VERSION ""

NS_ :

BS_:

BU_:

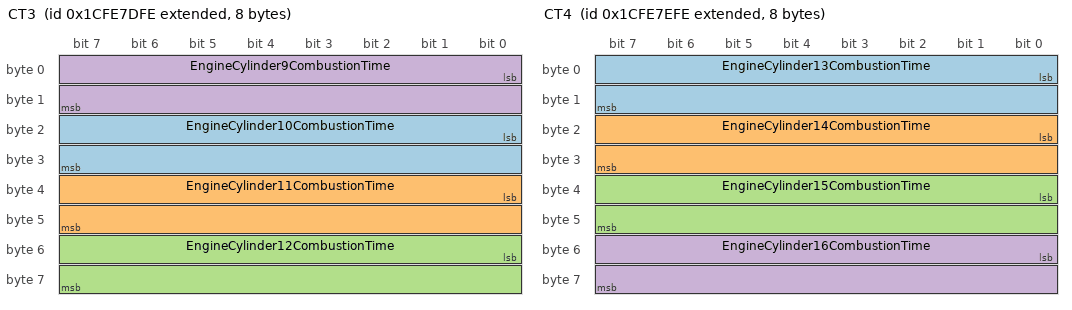
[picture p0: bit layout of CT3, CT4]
BO_ 2633924094 CT3: 8 Vector__XXX
 SG_ EngineCylinder10CombustionTime : 16|16@1+ (0.01,0) [0|642.55] "ms" Vector__XXX
 SG_ EngineCylinder11CombustionTime : 32|16@1+ (0.01,0) [0|642.55] "ms" Vector__XXX
 SG_ EngineCylinder12CombustionTime : 48|16@1+ (0.01,0) [0|642.55] "ms" Vector__XXX
 SG_ EngineCylinder9CombustionTime : 0|16@1+ (0.01,0) [0|642.55] "ms" Vector__XXX

BO_ 2633924350 CT4: 8 Vector__XXX
 SG_ EngineCylinder13CombustionTime : 0|16@1+ (0.01,0) [0|642.55] "ms" Vector__XXX
 SG_ EngineCylinder14CombustionTime : 16|16@1+ (0.01,0) [0|642.55] "ms" Vector__XXX
 SG_ EngineCylinder15CombustionTime : 32|16@1+ (0.01,0) [0|642.55] "ms" Vector__XXX
 SG_ EngineCylinder16CombustionTime : 48|16@1+ (0.01,0) [0|642.55] "ms" Vector__XXX

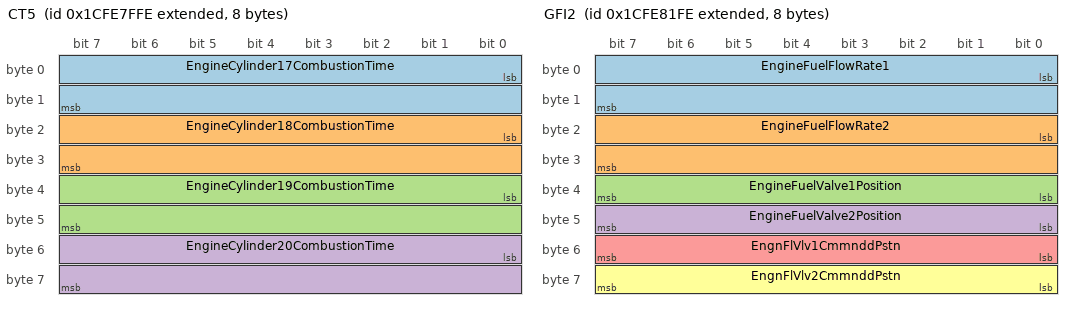
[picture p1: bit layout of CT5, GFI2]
BO_ 2633924606 CT5: 8 Vector__XXX
 SG_ EngineCylinder17CombustionTime : 0|16@1+ (0.01,0) [0|642.55] "ms" Vector__XXX
 SG_ EngineCylinder18CombustionTime : 16|16@1+ (0.01,0) [0|642.55] "ms" Vector__XXX
 SG_ EngineCylinder19CombustionTime : 32|16@1+ (0.01,0) [0|642.55] "ms" Vector__XXX
 SG_ EngineCylinder20CombustionTime : 48|16@1+ (0.01,0) [0|642.55] "ms" Vector__XXX

BO_ 2633924862 CT6: 8 Vector__XXX
 SG_ EngineAverageCombustionTime : 16|16@1+ (0.01,0) [0|642.55] "ms" Vector__XXX
 SG_ EngineDesiredCombustionTime : 0|16@1+ (0.01,0) [0|642.55] "ms" Vector__XXX

BO_ 2633925118 GFI2: 8 Vector__XXX
 SG_ EngineFuelFlowRate1 : 0|16@1+ (0.1,0) [0|6425.5] "(m*m*m)/h" Vector__XXX
 SG_ EngineFuelFlowRate2 : 16|16@1+ (0.1,0) [0|6425.5] "(m*m*m)/h" Vector__XXX
 SG_ EngineFuelValve1Position : 32|8@1+ (0.4,0) [0|100] "%" Vector__XXX
 SG_ EngineFuelValve2Position : 40|8@1+ (0.4,0) [0|100] "%" Vector__XXX
 SG_ EngnFlVlv1CmmnddPstn : 48|8@1+ (0.4,0) [0|100] "%" Vector__XXX
 SG_ EngnFlVlv2CmmnddPstn : 56|8@1+ (0.4,0) [0|100] "%" Vector__XXX

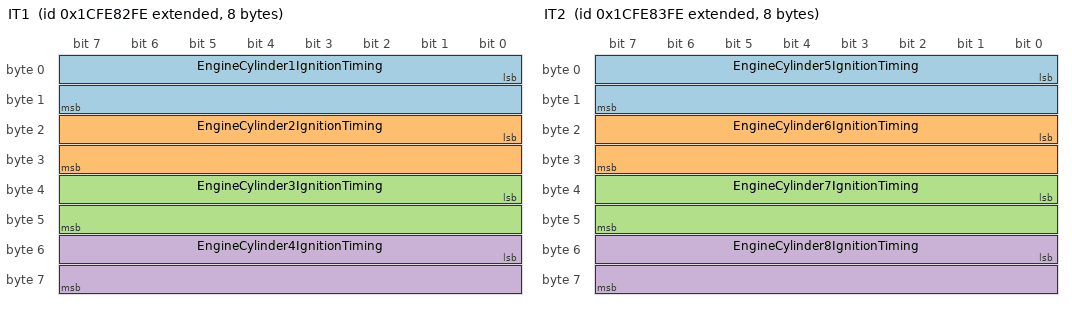
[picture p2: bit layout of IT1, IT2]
BO_ 2633925374 IT1: 8 Vector__XXX
 SG_ EngineCylinder1IgnitionTiming : 0|16@1+ (0.0078125,-200) [-200|301.9921875] "deg" Vector__XXX
 SG_ EngineCylinder2IgnitionTiming : 16|16@1+ (0.0078125,-200) [-200|301.9921875] "deg" Vector__XXX
 SG_ EngineCylinder3IgnitionTiming : 32|16@1+ (0.0078125,-200) [-200|301.9921875] "deg" Vector__XXX
 SG_ EngineCylinder4IgnitionTiming : 48|16@1+ (0.0078125,-200) [-200|301.9921875] "deg" Vector__XXX

BO_ 2633925630 IT2: 8 Vector__XXX
 SG_ EngineCylinder5IgnitionTiming : 0|16@1+ (0.0078125,-200) [-200|301.9921875] "deg" Vector__XXX
 SG_ EngineCylinder6IgnitionTiming : 16|16@1+ (0.0078125,-200) [-200|301.9921875] "deg" Vector__XXX
 SG_ EngineCylinder7IgnitionTiming : 32|16@1+ (0.0078125,-200) [-200|301.9921875] "deg" Vector__XXX
 SG_ EngineCylinder8IgnitionTiming : 48|16@1+ (0.0078125,-200) [-200|301.9921875] "deg" Vector__XXX

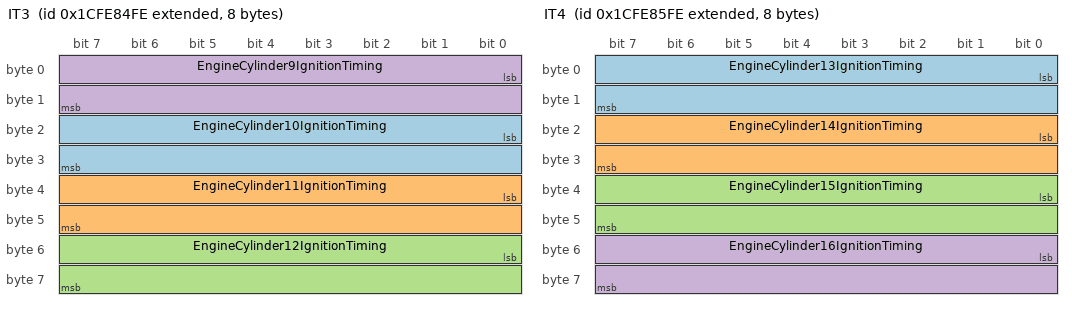
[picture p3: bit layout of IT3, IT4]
BO_ 2633925886 IT3: 8 Vector__XXX
 SG_ EngineCylinder10IgnitionTiming : 16|16@1+ (0.0078125,-200) [-200|301.9921875] "deg" Vector__XXX
 SG_ EngineCylinder11IgnitionTiming : 32|16@1+ (0.0078125,-200) [-200|301.9921875] "deg" Vector__XXX
 SG_ EngineCylinder12IgnitionTiming : 48|16@1+ (0.0078125,-200) [-200|301.9921875] "deg" Vector__XXX
 SG_ EngineCylinder9IgnitionTiming : 0|16@1+ (0.0078125,-200) [-200|301.9921875] "deg" Vector__XXX

BO_ 2633926142 IT4: 8 Vector__XXX
 SG_ EngineCylinder13IgnitionTiming : 0|16@1+ (0.0078125,-200) [-200|301.9921875] "deg" Vector__XXX
 SG_ EngineCylinder14IgnitionTiming : 16|16@1+ (0.0078125,-200) [-200|301.9921875] "deg" Vector__XXX
 SG_ EngineCylinder15IgnitionTiming : 32|16@1+ (0.0078125,-200) [-200|301.9921875] "deg" Vector__XXX
 SG_ EngineCylinder16IgnitionTiming : 48|16@1+ (0.0078125,-200) [-200|301.9921875] "deg" Vector__XXX

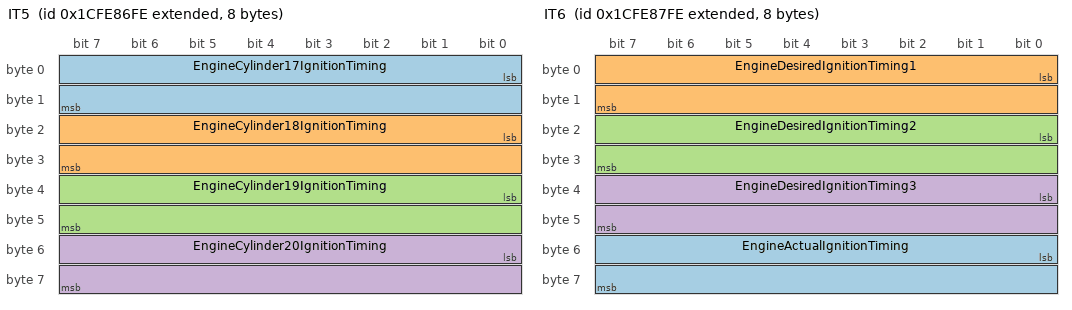
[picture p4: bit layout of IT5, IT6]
BO_ 2633926398 IT5: 8 Vector__XXX
 SG_ EngineCylinder17IgnitionTiming : 0|16@1+ (0.0078125,-200) [-200|301.9921875] "deg" Vector__XXX
 SG_ EngineCylinder18IgnitionTiming : 16|16@1+ (0.0078125,-200) [-200|301.9921875] "deg" Vector__XXX
 SG_ EngineCylinder19IgnitionTiming : 32|16@1+ (0.0078125,-200) [-200|301.9921875] "deg" Vector__XXX
 SG_ EngineCylinder20IgnitionTiming : 48|16@1+ (0.0078125,-200) [-200|301.9921875] "deg" Vector__XXX

BO_ 2633926654 IT6: 8 Vector__XXX
 SG_ EngineActualIgnitionTiming : 48|16@1+ (0.0078125,-200) [-200|301.9921875] "deg" Vector__XXX
 SG_ EngineDesiredIgnitionTiming1 : 0|16@1+ (0.0078125,-200) [-200|301.9921875] "deg" Vector__XXX
 SG_ EngineDesiredIgnitionTiming2 : 16|16@1+ (0.0078125,-200) [-200|301.9921875] "deg" Vector__XXX
 SG_ EngineDesiredIgnitionTiming3 : 32|16@1+ (0.0078125,-200) [-200|301.9921875] "deg" Vector__XXX

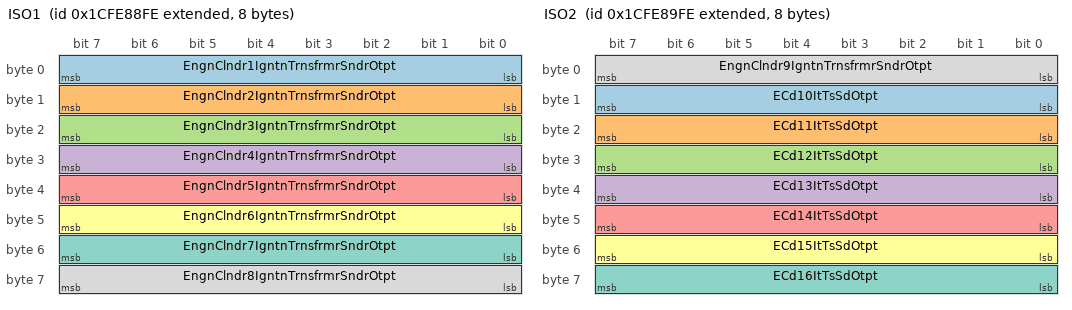
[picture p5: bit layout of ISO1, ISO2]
BO_ 2633926910 ISO1: 8 Vector__XXX
 SG_ EngnClndr1IgntnTrnsfrmrSndrOtpt : 0|8@1+ (1,-125) [-125|125] "%" Vector__XXX
 SG_ EngnClndr2IgntnTrnsfrmrSndrOtpt : 8|8@1+ (1,-125) [-125|125] "%" Vector__XXX
 SG_ EngnClndr3IgntnTrnsfrmrSndrOtpt : 16|8@1+ (1,-125) [-125|125] "%" Vector__XXX
 SG_ EngnClndr4IgntnTrnsfrmrSndrOtpt : 24|8@1+ (1,-125) [-125|125] "%" Vector__XXX
 SG_ EngnClndr5IgntnTrnsfrmrSndrOtpt : 32|8@1+ (1,-125) [-125|125] "%" Vector__XXX
 SG_ EngnClndr6IgntnTrnsfrmrSndrOtpt : 40|8@1+ (1,-125) [-125|125] "%" Vector__XXX
 SG_ EngnClndr7IgntnTrnsfrmrSndrOtpt : 48|8@1+ (1,-125) [-125|125] "%" Vector__XXX
 SG_ EngnClndr8IgntnTrnsfrmrSndrOtpt : 56|8@1+ (1,-125) [-125|125] "%" Vector__XXX

BO_ 2633927166 ISO2: 8 Vector__XXX
 SG_ ECd10ItTsSdOtpt : 8|8@1+ (1,-125) [-125|125] "%" Vector__XXX
 SG_ ECd11ItTsSdOtpt : 16|8@1+ (1,-125) [-125|125] "%" Vector__XXX
 SG_ ECd12ItTsSdOtpt : 24|8@1+ (1,-125) [-125|125] "%" Vector__XXX
 SG_ ECd13ItTsSdOtpt : 32|8@1+ (1,-125) [-125|125] "%" Vector__XXX
 SG_ ECd14ItTsSdOtpt : 40|8@1+ (1,-125) [-125|125] "%" Vector__XXX
 SG_ ECd15ItTsSdOtpt : 48|8@1+ (1,-125) [-125|125] "%" Vector__XXX
 SG_ ECd16ItTsSdOtpt : 56|8@1+ (1,-125) [-125|125] "%" Vector__XXX
 SG_ EngnClndr9IgntnTrnsfrmrSndrOtpt : 0|8@1+ (1,-125) [-125|125] "%" Vector__XXX

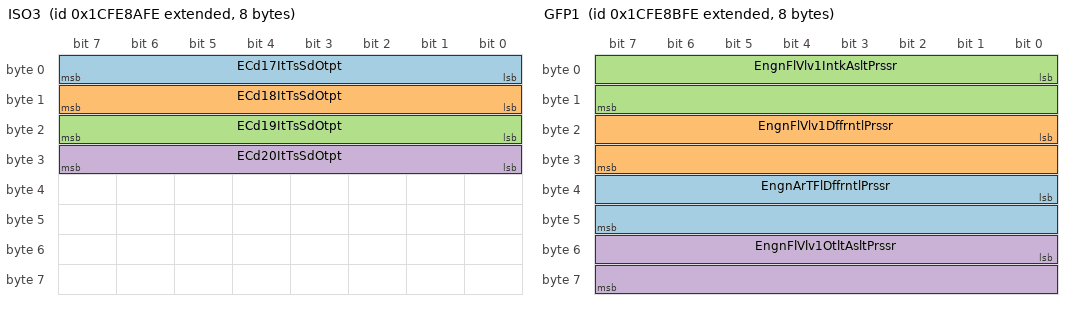
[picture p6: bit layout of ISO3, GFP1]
BO_ 2633927422 ISO3: 8 Vector__XXX
 SG_ ECd17ItTsSdOtpt : 0|8@1+ (1,-125) [-125|125] "%" Vector__XXX
 SG_ ECd18ItTsSdOtpt : 8|8@1+ (1,-125) [-125|125] "%" Vector__XXX
 SG_ ECd19ItTsSdOtpt : 16|8@1+ (1,-125) [-125|125] "%" Vector__XXX
 SG_ ECd20ItTsSdOtpt : 24|8@1+ (1,-125) [-125|125] "%" Vector__XXX

BO_ 2633927678 GFP1: 8 Vector__XXX
 SG_ EngnArTFlDffrntlPrssr : 32|16@1+ (0.1,0) [0|6425.5] "kPa" Vector__XXX
 SG_ EngnFlVlv1DffrntlPrssr : 16|16@1+ (0.1,0) [0|6425.5] "kPa" Vector__XXX
 SG_ EngnFlVlv1IntkAsltPrssr : 0|16@1+ (0.1,0) [0|6425.5] "kPa" Vector__XXX
 SG_ EngnFlVlv1OtltAsltPrssr : 48|16@1+ (0.1,0) [0|6425.5] "kPa" Vector__XXX

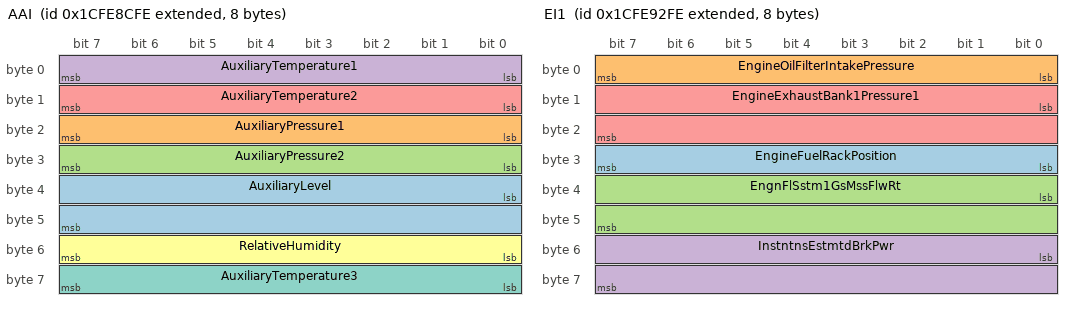
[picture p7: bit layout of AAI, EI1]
BO_ 2633927934 AAI: 8 Vector__XXX
 SG_ AuxiliaryLevel : 32|16@1+ (0.1,0) [0|6425.5] "mm" Vector__XXX
 SG_ AuxiliaryPressure1 : 16|8@1+ (16,0) [0|4000] "kPa" Vector__XXX
 SG_ AuxiliaryPressure2 : 24|8@1+ (16,0) [0|4000] "kPa" Vector__XXX
 SG_ AuxiliaryTemperature1 : 0|8@1+ (1,-40) [-40|210] "degC" Vector__XXX
 SG_ AuxiliaryTemperature2 : 8|8@1+ (1,-40) [-40|210] "degC" Vector__XXX
 SG_ RelativeHumidity : 48|8@1+ (0.4,0) [0|100] "%" Vector__XXX
 SG_ AuxiliaryTemperature3 : 56|8@1+ (1,-40) [-40|210] "degC" Vector__XXX

BO_ 2633928446 S2: 8 Vector__XXX
 SG_ ServiceComponentIdentification : 0|8@1+ (1,0) [0|250] "ID" Vector__XXX
 SG_ TimeSinceLastService : 8|16@1+ (1,-32127) [-32127|32128] "h" Vector__XXX

BO_ 2633929214 FL: 8 Vector__XXX
 SG_ EngineFluidBundLevel : 8|8@1+ (0.4,0) [0|100] "%" Vector__XXX
 SG_ EngineFuelLeakage1 : 0|2@1+ (1,0) [0|3] "" Vector__XXX
 SG_ EngineFuelLeakage2 : 2|2@1+ (1,0) [0|3] "" Vector__XXX

BO_ 2633929470 EI1: 8 Vector__XXX
 SG_ EngineFuelRackPosition : 24|8@1+ (0.4,0) [0|100] "%" Vector__XXX
 SG_ EngineOilFilterIntakePressure : 0|8@1+ (4,0) [0|1000] "kPa" Vector__XXX
 SG_ EngnFlSstm1GsMssFlwRt : 32|16@1+ (0.05,0) [0|3212.75] "kg/h" Vector__XXX
 SG_ InstntnsEstmtdBrkPwr : 48|16@1+ (0.5,0) [0|32127.5] "kW" Vector__XXX
 SG_ EngineExhaustBank1Pressure1 : 8|16@1+ (0.0078125,-250) [-250|251.9921875] "kPa" Vector__XXX

BO_ 2633929726 EES: 8 Vector__XXX
 SG_ ElectricalLoad : 0|16@1+ (0.5,0) [0|32127.5] "kW" Vector__XXX
 SG_ EngineTurningGearEngaged : 18|2@1+ (1,0) [0|3] "" Vector__XXX
 SG_ SafetyWireStatus : 16|2@1+ (1,0) [0|3] "" Vector__XXX

BO_ 2633930238 RBI: 8 Vector__XXX
 SG_ EngineOperationTimeSinceRebuild : 0|32@1+ (1,0) [0|4211081215] "s" Vector__XXX

BO_ 2633931774 TCI1: 8 Vector__XXX
 SG_ EngineTurbocharger2Speed : 8|16@1+ (4,0) [0|257020] "rpm" Vector__XXX
 SG_ EngineTurbocharger3Speed : 24|16@1+ (4,0) [0|257020] "rpm" Vector__XXX
 SG_ EngineTurbocharger4Speed : 40|16@1+ (4,0) [0|257020] "rpm" Vector__XXX
 SG_ EngnTrhrgrLOlPrssr2 : 0|8@1+ (4,0) [0|1000] "kPa" Vector__XXX

BO_ 2633932798 EPT5: 8 Vector__XXX
 SG_ EngnExhstGsPrt17Tmprtr : 0|16@1+ (0.03125,-273) [-273|1734.96875] "degC" Vector__XXX
 SG_ EngnExhstGsPrt18Tmprtr : 16|16@1+ (0.03125,-273) [-273|1734.96875] "degC" Vector__XXX
 SG_ EngnExhstGsPrt19Tmprtr : 32|16@1+ (0.03125,-273) [-273|1734.96875] "degC" Vector__XXX
 SG_ EngnExhstGsPrt20Tmprtr : 48|16@1+ (0.03125,-273) [-273|1734.96875] "degC" Vector__XXX

BO_ 2633933310 EPT3: 8 Vector__XXX
 SG_ EngnExhstGsPrt10Tmprtr : 16|16@1+ (0.03125,-273) [-273|1734.96875] "degC" Vector__XXX
 SG_ EngnExhstGsPrt11Tmprtr : 32|16@1+ (0.03125,-273) [-273|1734.96875] "degC" Vector__XXX
 SG_ EngnExhstGsPrt12Tmprtr : 48|16@1+ (0.03125,-273) [-273|1734.96875] "degC" Vector__XXX
 SG_ EngnExhstGsPrt9Tmprtr : 0|16@1+ (0.03125,-273) [-273|1734.96875] "degC" Vector__XXX

BO_ 2633933566 EPT2: 8 Vector__XXX
 SG_ EngnExhstGsPrt5Tmprtr : 0|16@1+ (0.03125,-273) [-273|1734.96875] "degC" Vector__XXX
 SG_ EngnExhstGsPrt6Tmprtr : 16|16@1+ (0.03125,-273) [-273|1734.96875] "degC" Vector__XXX
 SG_ EngnExhstGsPrt7Tmprtr : 32|16@1+ (0.03125,-273) [-273|1734.96875] "degC" Vector__XXX
 SG_ EngnExhstGsPrt8Tmprtr : 48|16@1+ (0.03125,-273) [-273|1734.96875] "degC" Vector__XXX

BO_ 2633933822 EPT1: 8 Vector__XXX
 SG_ EngnExhstGsPrt1Tmprtr : 0|16@1+ (0.03125,-273) [-273|1734.96875] "degC" Vector__XXX
 SG_ EngnExhstGsPrt2Tmprtr : 16|16@1+ (0.03125,-273) [-273|1734.96875] "degC" Vector__XXX
 SG_ EngnExhstGsPrt3Tmprtr : 32|16@1+ (0.03125,-273) [-273|1734.96875] "degC" Vector__XXX
 SG_ EngnExhstGsPrt4Tmprtr : 48|16@1+ (0.03125,-273) [-273|1734.96875] "degC" Vector__XXX

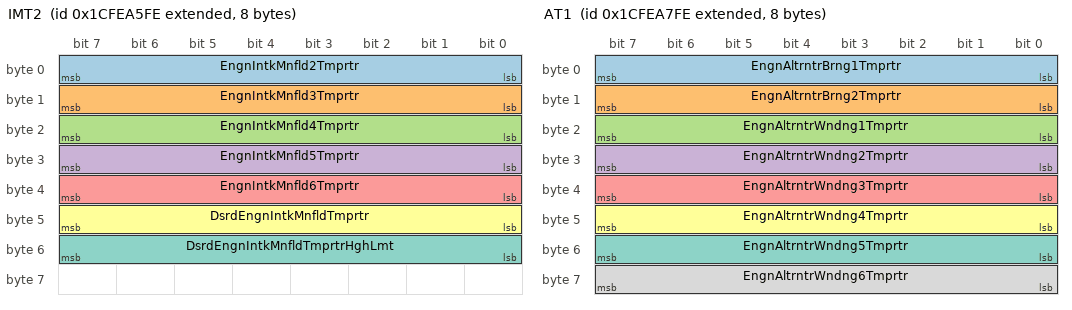
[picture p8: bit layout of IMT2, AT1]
BO_ 2633934334 IMT2: 8 Vector__XXX
 SG_ EngnIntkMnfld2Tmprtr : 0|8@1+ (1,-40) [-40|210] "degC" Vector__XXX
 SG_ EngnIntkMnfld3Tmprtr : 8|8@1+ (1,-40) [-40|210] "degC" Vector__XXX
 SG_ EngnIntkMnfld4Tmprtr : 16|8@1+ (1,-40) [-40|210] "degC" Vector__XXX
 SG_ EngnIntkMnfld5Tmprtr : 24|8@1+ (1,-40) [-40|210] "degC" Vector__XXX
 SG_ EngnIntkMnfld6Tmprtr : 32|8@1+ (1,-40) [-40|210] "degC" Vector__XXX
 SG_ DsrdEngnIntkMnfldTmprtr : 40|8@1+ (1,-40) [-40|210] "degC" Vector__XXX
 SG_ DsrdEngnIntkMnfldTmprtrHghLmt : 48|8@1+ (1,-40) [-40|210] "degC" Vector__XXX

BO_ 2633934846 AT1: 8 Vector__XXX
 SG_ EngnAltrntrBrng1Tmprtr : 0|8@1+ (1,-40) [-40|210] "degC" Vector__XXX
 SG_ EngnAltrntrBrng2Tmprtr : 8|8@1+ (1,-40) [-40|210] "degC" Vector__XXX
 SG_ EngnAltrntrWndng1Tmprtr : 16|8@1+ (1,-40) [-40|210] "degC" Vector__XXX
 SG_ EngnAltrntrWndng2Tmprtr : 24|8@1+ (1,-40) [-40|210] "degC" Vector__XXX
 SG_ EngnAltrntrWndng3Tmprtr : 32|8@1+ (1,-40) [-40|210] "degC" Vector__XXX
 SG_ EngnAltrntrWndng4Tmprtr : 40|8@1+ (1,-40) [-40|210] "degC" Vector__XXX
 SG_ EngnAltrntrWndng5Tmprtr : 48|8@1+ (1,-40) [-40|210] "degC" Vector__XXX
 SG_ EngnAltrntrWndng6Tmprtr : 56|8@1+ (1,-40) [-40|210] "degC" Vector__XXX

BO_ 2633935102 ACTL: 8 Vector__XXX
 SG_ ArticulationAngle : 0|8@1+ (1,-125) [-125|125] "deg" Vector__XXX
 SG_ ArticulationAngularVelocity : 8|16@1+ (0.0078125,-250) [-250|251.9921875] "deg/s" Vector__XXX

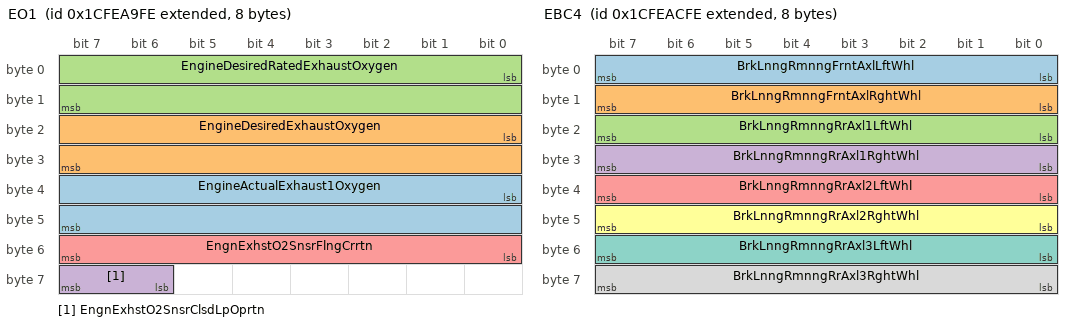
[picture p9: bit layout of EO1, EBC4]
BO_ 2633935358 EO1: 8 Vector__XXX
 SG_ EngineActualExhaust1Oxygen : 32|16@1+ (0.0025,0) [0|160.6375] "%" Vector__XXX
 SG_ EngineDesiredExhaustOxygen : 16|16@1+ (0.0025,0) [0|160.6375] "%" Vector__XXX
 SG_ EngineDesiredRatedExhaustOxygen : 0|16@1+ (0.0025,0) [0|160.6375] "%" Vector__XXX
 SG_ EngnExhstO2SnsrClsdLpOprtn : 62|2@1+ (1,0) [0|3] "" Vector__XXX
 SG_ EngnExhstO2SnsrFlngCrrtn : 48|8@1+ (1,-125) [-125|125] "%" Vector__XXX

BO_ 2633935614 AF2: 8 Vector__XXX
 SG_ EFSstGsMssFwRtSsFCt : 32|8@1+ (1,-125) [-125|125] "%" Vector__XXX
 SG_ EngnIntkMnfldDsrdAsltPrssr : 8|16@1+ (0.1,0) [0|6425.5] "kPa" Vector__XXX
 SG_ EngnTrhrgrWstgtVlvPstn : 24|8@1+ (0.4,0) [0|100] "%" Vector__XXX
 SG_ GaseousFuelCorrectionFactor : 0|8@1+ (1,0) [0|250] "%" Vector__XXX
 SG_ GssFlInjtnPlsCrrtnFtr : 40|16@1+ (0.0078125,-251) [0|150] "%" Vector__XXX

BO_ 2633935870 ETC6: 8 Vector__XXX
 SG_ ClutchLifeRemaining : 24|8@1+ (0.4,0) [0|100] "%" Vector__XXX
 SG_ HighestPossibleGear : 8|8@1+ (1,-125) [-125|125] "gear value" Vector__XXX
 SG_ LowestPossibleGear : 16|8@1+ (1,-125) [-125|125] "gear value" Vector__XXX
 SG_ RecommendedGear : 0|8@1+ (1,-125) [-125|125] "gear value" Vector__XXX

BO_ 2633936126 EBC4: 8 Vector__XXX
 SG_ BrkLnngRmnngFrntAxlLftWhl : 0|8@1+ (0.4,0) [0|100] "%" Vector__XXX
 SG_ BrkLnngRmnngFrntAxlRghtWhl : 8|8@1+ (0.4,0) [0|100] "%" Vector__XXX
 SG_ BrkLnngRmnngRrAxl1LftWhl : 16|8@1+ (0.4,0) [0|100] "%" Vector__XXX
 SG_ BrkLnngRmnngRrAxl1RghtWhl : 24|8@1+ (0.4,0) [0|100] "%" Vector__XXX
 SG_ BrkLnngRmnngRrAxl2LftWhl : 32|8@1+ (0.4,0) [0|100] "%" Vector__XXX
 SG_ BrkLnngRmnngRrAxl2RghtWhl : 40|8@1+ (0.4,0) [0|100] "%" Vector__XXX
 SG_ BrkLnngRmnngRrAxl3LftWhl : 48|8@1+ (0.4,0) [0|100] "%" Vector__XXX
 SG_ BrkLnngRmnngRrAxl3RghtWhl : 56|8@1+ (0.4,0) [0|100] "%" Vector__XXX

BO_ 2633936894 GFC: 8 Vector__XXX
 SG_ TotalFuelUsedGaseous : 32|32@1+ (0.5,0) [0|2105540607.5] "kg" Vector__XXX
 SG_ TripFuelGaseous : 0|32@1+ (0.5,0) [0|2105540607.5] "kg" Vector__XXX

BO_ 2633937150 TTI2: 20 Vector__XXX
 SG_ TripAirCompressorOnTime : 128|32@1+ (0.05,0) [0|210554060.75] "h" Vector__XXX
 SG_ TripCruiseTime : 0|32@1+ (0.05,0) [0|210554060.75] "h" Vector__XXX
 SG_ TripEngineRunningTime : 64|32@1+ (0.05,0) [0|210554060.75] "h" Vector__XXX
 SG_ TripIdleTime : 96|32@1+ (0.05,0) [0|210554060.75] "h" Vector__XXX
 SG_ TripPtoGovernorTime : 32|32@1+ (0.05,0) [0|210554060.75] "h" Vector__XXX

BO_ 2633937406 EH: 8 Vector__XXX
 SG_ TotalEcuDistance : 0|32@1+ (0.125,0) [0|526385151.875] "km" Vector__XXX
 SG_ TotalEcuRunTime : 32|32@1+ (0.05,0) [0|210554060.75] "h" Vector__XXX

BO_ 2633937662 GFI1: 8 Vector__XXX
 SG_ EngineFuelSpecificGravity : 48|16@1+ (0.0001,0) [0|2] "" Vector__XXX
 SG_ TripAverageFuelRateGaseous : 32|16@1+ (0.05,0) [0|3212.75] "kg/h" Vector__XXX
 SG_ TtlEngnPtGvrnrFlUsdGss : 0|32@1+ (0.5,0) [0|2105540607.5] "kg" Vector__XXX

BO_ 2633937918 LFI1: 8 Vector__XXX
 SG_ FlexibleFuelPercentage : 48|16@1+ (0.0025,0) [0|100] "%" Vector__XXX
 SG_ TotalEnginePtoGovernorFuelUsed : 0|32@1+ (0.5,0) [0|2105540607.5] "l" Vector__XXX
 SG_ TripAverageFuelRate : 32|16@1+ (0.05,0) [0|3212.75] "l/h" Vector__XXX

BO_ 2633938174 TTI1: 16 Vector__XXX
 SG_ TripTimeInDerateByEngine : 96|32@1+ (0.05,0) [0|210554060.75] "h" Vector__XXX
 SG_ TripTimeInGearDown : 64|32@1+ (0.05,0) [0|210554060.75] "h" Vector__XXX
 SG_ TripTimeInTopGear : 32|32@1+ (0.05,0) [0|210554060.75] "h" Vector__XXX
 SG_ TripTimeInVsl : 0|32@1+ (0.05,0) [0|210554060.75] "h" Vector__XXX

BO_ 2633938430 TSI: 8 Vector__XXX
 SG_ TripNumberOfHotShutdowns : 0|16@1+ (1,0) [0|64255] "count" Vector__XXX
 SG_ TripNumberOfIdleShutdowns : 16|16@1+ (1,0) [0|64255] "count" Vector__XXX
 SG_ TripSuddenDecelerations : 48|16@1+ (1,0) [0|64255] "count" Vector__XXX
 SG_ TrpNmrOfIdlShtdwnOvrrds : 32|16@1+ (1,0) [0|64255] "count" Vector__XXX

BO_ 2633938686 TVI: 8 Vector__XXX
 SG_ TripCruiseDistance : 16|32@1+ (0.125,0) [0|526385151.875] "km" Vector__XXX
 SG_ TripMaximumVehicleSpeed : 0|16@1+ (0.00390625,0) [0|250.99609375] "km/h" Vector__XXX

BO_ 2633938942 LF1: 10 Vector__XXX
 SG_ TotalEngineCruiseTime : 48|32@1+ (0.05,0) [0|210554060.75] "h" Vector__XXX
 SG_ TripAverageEngineSpeed : 16|16@1+ (0.125,0) [0|8031.875] "rpm" Vector__XXX
 SG_ TripMaximumEngineSpeed : 0|16@1+ (0.125,0) [0|8031.875] "rpm" Vector__XXX
 SG_ TripDriveAverageLoadFactor : 32|8@1+ (0.4,0) [0|100] "%" Vector__XXX
 SG_ TotalDriveAverageLoadFactor : 40|8@1+ (0.4,0) [0|100] "%" Vector__XXX

BO_ 2633939198 GTFI: 22 Vector__XXX
 SG_ TripCruiseFuelUsedGaseous : 128|32@1+ (0.5,0) [0|2105540607.5] "kg" Vector__XXX
 SG_ TripDriveFuelEconomyGaseous : 160|16@1+ (0.001953125,0) [0|125.498046875] "km/kg" Vector__XXX
 SG_ TripDriveFuelUsedGaseous : 0|32@1+ (0.5,0) [0|2105540607.5] "kg" Vector__XXX
 SG_ TripVehicleIdleFuelUsedGaseous : 96|32@1+ (0.5,0) [0|2105540607.5] "kg" Vector__XXX
 SG_ TrpPtGvrnrMvngFlUsdGss : 32|32@1+ (0.5,0) [0|2105540607.5] "kg" Vector__XXX
 SG_ TrpPtGvrnrNnMvngFlUsdGss : 64|32@1+ (0.5,0) [0|2105540607.5] "kg" Vector__XXX

BO_ 2633939454 LTFI: 22 Vector__XXX
 SG_ TripCruiseFuelUsed : 128|32@1+ (0.5,0) [0|2105540607.5] "l" Vector__XXX
 SG_ TripDriveFuelEconomy : 160|16@1+ (0.001953125,0) [0|125.498046875] "km/L" Vector__XXX
 SG_ TripDriveFuelUsed : 0|32@1+ (0.5,0) [0|2105540607.5] "l" Vector__XXX
 SG_ TripPtoGovernorMovingFuelUsed : 32|32@1+ (0.5,0) [0|2105540607.5] "l" Vector__XXX
 SG_ TripVehicleIdleFuelUsed : 96|32@1+ (0.5,0) [0|2105540607.5] "l" Vector__XXX
 SG_ TrpPtGvrnrNnMvngFlUsd : 64|32@1+ (0.5,0) [0|2105540607.5] "l" Vector__XXX

BO_ 2633939710 TDI: 12 Vector__XXX
 SG_ TripDistanceInTopGear : 64|32@1+ (0.125,0) [0|526385151.875] "km" Vector__XXX
 SG_ TripDistanceOnVsl : 0|32@1+ (0.125,0) [0|526385151.875] "km" Vector__XXX
 SG_ TripGearDownDistance : 32|32@1+ (0.125,0) [0|526385151.875] "km" Vector__XXX

BO_ 2633939966 TFI: 16 Vector__XXX
 SG_ TripFanOnTime : 0|32@1+ (0.05,0) [0|210554060.75] "h" Vector__XXX
 SG_ TripFanOnTimeDueToAManualSwitch : 64|32@1+ (0.05,0) [0|210554060.75] "h" Vector__XXX
 SG_ TripFanOnTimeDueToTheACSystem : 96|32@1+ (0.05,0) [0|210554060.75] "h" Vector__XXX
 SG_ TrpFnOnTmDTThEngnSstm : 32|32@1+ (0.05,0) [0|210554060.75] "h" Vector__XXX

BO_ 2633940222 CBI: 16 Vector__XXX
 SG_ TotalCompressionBrakeDistance : 0|32@1+ (0.125,0) [0|526385151.875] "km" Vector__XXX
 SG_ TripCompressionBrakeDistance : 32|32@1+ (0.125,0) [0|526385151.875] "km" Vector__XXX
 SG_ TripServiceBrakeApplications : 96|32@1+ (1,0) [0|4211081215] "brake appl" Vector__XXX
 SG_ TripServiceBrakeDistance : 64|32@1+ (0.125,0) [0|526385151.875] "km" Vector__XXX

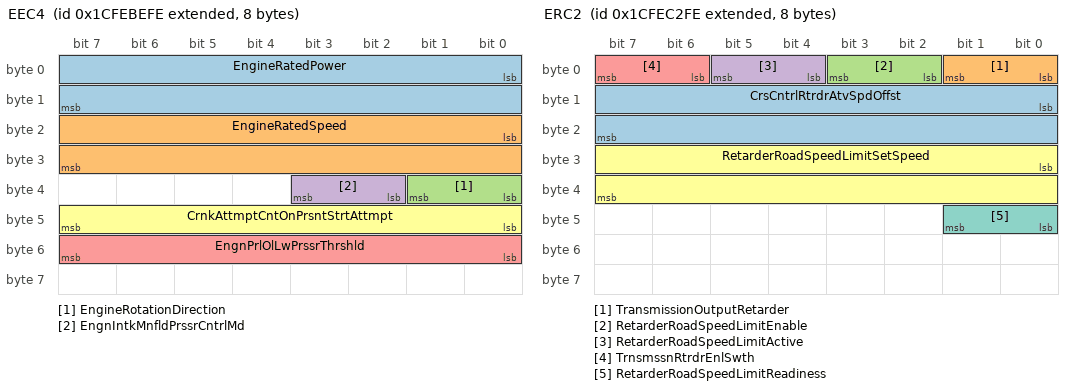
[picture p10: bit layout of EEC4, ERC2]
BO_ 2633940734 EEC4: 8 Vector__XXX
 SG_ EngineRatedPower : 0|16@1+ (0.5,0) [0|32127.5] "kW" Vector__XXX
 SG_ EngineRatedSpeed : 16|16@1+ (0.125,0) [0|8031.875] "rpm" Vector__XXX
 SG_ EngineRotationDirection : 32|2@1+ (1,0) [0|3] "" Vector__XXX
 SG_ EngnIntkMnfldPrssrCntrlMd : 34|2@1+ (1,0) [0|3] "" Vector__XXX
 SG_ EngnPrlOlLwPrssrThrshld : 48|8@1+ (4,0) [0|1000] "kPa" Vector__XXX
 SG_ CrnkAttmptCntOnPrsntStrtAttmpt : 40|8@1+ (1,0) [0|250] "count" Vector__XXX

BO_ 2633941758 ERC2: 8 Vector__XXX
 SG_ CrsCntrlRtrdrAtvSpdOffst : 8|16@1+ (0.00390625,-125) [0|125.996] "km/h" Vector__XXX
 SG_ TransmissionOutputRetarder : 0|2@1+ (1,0) [0|3] "" Vector__XXX
 SG_ RetarderRoadSpeedLimitEnable : 2|2@1+ (1,0) [0|3] "" Vector__XXX
 SG_ RetarderRoadSpeedLimitActive : 4|2@1+ (1,0) [0|3] "" Vector__XXX
 SG_ TrnsmssnRtrdrEnlSwth : 6|2@1+ (1,0) [0|3] "" Vector__XXX
 SG_ RetarderRoadSpeedLimitSetSpeed : 24|16@1+ (0.00390625,0) [0|250.99609375] "km/h" Vector__XXX
 SG_ RetarderRoadSpeedLimitReadiness : 40|2@1+ (1,0) [0|3] "" Vector__XXX

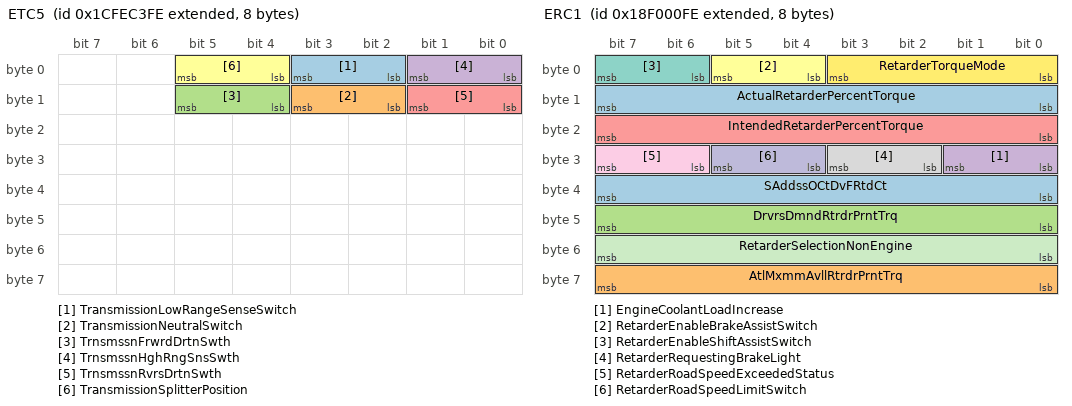
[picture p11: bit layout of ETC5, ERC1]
BO_ 2633942014 ETC5: 8 Vector__XXX
 SG_ TransmissionLowRangeSenseSwitch : 2|2@1+ (1,0) [0|3] "" Vector__XXX
 SG_ TransmissionNeutralSwitch : 10|2@1+ (1,0) [0|3] "" Vector__XXX
 SG_ TrnsmssnFrwrdDrtnSwth : 12|2@1+ (1,0) [0|3] "" Vector__XXX
 SG_ TrnsmssnHghRngSnsSwth : 0|2@1+ (1,0) [0|3] "" Vector__XXX
 SG_ TrnsmssnRvrsDrtnSwth : 8|2@1+ (1,0) [0|3] "" Vector__XXX
 SG_ TransmissionSplitterPosition : 4|2@1+ (1,0) [0|3] "" Vector__XXX

BO_ 2633942526 ETC4: 8 Vector__XXX
 SG_ TrnsmssnSnhrnzrBrkVl : 8|8@1+ (0.4,0) [0|100] "%" Vector__XXX
 SG_ TrnsmssnSnhrnzrClthVl : 0|8@1+ (0.4,0) [0|100] "%" Vector__XXX

BO_ 2633943038 ETC3: 8 Vector__XXX
 SG_ TransmissionClutchActuator : 40|2@1+ (1,0) [0|3] "" Vector__XXX
 SG_ TransmissionDefuelActuator : 44|2@1+ (1,0) [0|3] "" Vector__XXX
 SG_ TransmissionRangeHighActuator : 32|2@1+ (1,0) [0|3] "" Vector__XXX
 SG_ TransmissionRangeLowActuator : 34|2@1+ (1,0) [0|3] "" Vector__XXX
 SG_ TrnsmssnInrtBrkAttr : 46|2@1+ (1,0) [0|3] "" Vector__XXX
 SG_ TrnsmssnShftFngrCntrRlIndtr : 20|2@1+ (1,0) [0|3] "" Vector__XXX
 SG_ TrnsmssnShftFngrEnggmntIndtr : 18|2@1+ (1,0) [0|3] "" Vector__XXX
 SG_ TrnsmssnShftFngrGrAttr1 : 26|2@1+ (1,0) [0|3] "" Vector__XXX
 SG_ TrnsmssnShftFngrGrAttr2 : 30|2@1+ (1,0) [0|3] "" Vector__XXX
 SG_ TrnsmssnShftFngrGrPstn : 0|8@1+ (0.4,0) [0|100] "%" Vector__XXX
 SG_ TrnsmssnShftFngrNtrlIndtr : 16|2@1+ (1,0) [0|3] "" Vector__XXX
 SG_ TrnsmssnShftFngrRlAttr1 : 24|2@1+ (1,0) [0|3] "" Vector__XXX
 SG_ TrnsmssnShftFngrRlAttr2 : 28|2@1+ (1,0) [0|3] "" Vector__XXX
 SG_ TrnsmssnShftFngrRlPstn : 8|8@1+ (0.4,0) [0|100] "%" Vector__XXX
 SG_ TrnsmssnSplttrDrtAttr : 36|2@1+ (1,0) [0|3] "" Vector__XXX
 SG_ TrnsmssnSplttrIndrtAttr : 38|2@1+ (1,0) [0|3] "" Vector__XXX
 SG_ TrnsmssnTrqCnvrtrLkpClthAttr : 42|2@1+ (1,0) [0|3] "" Vector__XXX

BO_ 2565865726 ERC1: 8 Vector__XXX
 SG_ ActualRetarderPercentTorque : 8|8@1+ (1,-125) [-125|0] "%" Vector__XXX
 SG_ AtlMxmmAvllRtrdrPrntTrq : 56|8@1+ (1,-125) [-125|0] "%" Vector__XXX
 SG_ DrvrsDmndRtrdrPrntTrq : 40|8@1+ (1,-125) [-125|0] "%" Vector__XXX
 SG_ EngineCoolantLoadIncrease : 24|2@1+ (1,0) [0|3] "" Vector__XXX
 SG_ IntendedRetarderPercentTorque : 16|8@1+ (1,-125) [-125|0] "%" Vector__XXX
 SG_ RetarderEnableBrakeAssistSwitch : 4|2@1+ (1,0) [0|3] "" Vector__XXX
 SG_ RetarderEnableShiftAssistSwitch : 6|2@1+ (1,0) [0|3] "" Vector__XXX
 SG_ RetarderRequestingBrakeLight : 26|2@1+ (1,0) [0|3] "" Vector__XXX
 SG_ RetarderRoadSpeedExceededStatus : 30|2@1+ (1,0) [0|3] "" Vector__XXX
 SG_ RetarderRoadSpeedLimitSwitch : 28|2@1+ (1,0) [0|3] "" Vector__XXX
 SG_ RetarderSelectionNonEngine : 48|8@1+ (0.4,0) [0|100] "%" Vector__XXX
 SG_ RetarderTorqueMode : 0|4@1+ (1,0) [0|15] "" Vector__XXX
 SG_ SAddssOCtDvFRtdCt : 32|8@1+ (1,0) [0|253] "sourceadr" Vector__XXX

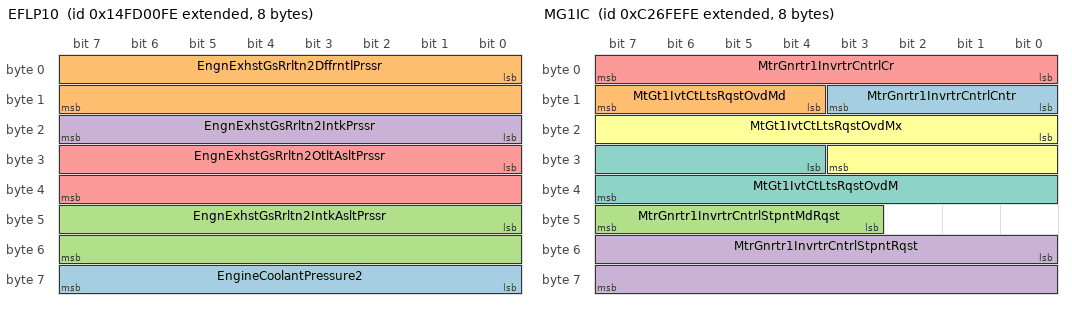
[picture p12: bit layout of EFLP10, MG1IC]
BO_ 2499608830 EFLP10: 8 Vector__XXX
 SG_ EngineCoolantPressure2 : 56|8@1+ (2,0) [0|500] "kPa" Vector__XXX
 SG_ EngnExhstGsRrltn2DffrntlPrssr : 0|16@1+ (0.0078125,-250) [-250|251.9921875] "kPa" Vector__XXX
 SG_ EngnExhstGsRrltn2IntkAsltPrssr : 40|16@1+ (0.1,0) [0|6425.5] "kPa" Vector__XXX
 SG_ EngnExhstGsRrltn2IntkPrssr : 16|8@1+ (2,0) [0|500] "kPa" Vector__XXX
 SG_ EngnExhstGsRrltn2OtltAsltPrssr : 24|16@1+ (0.1,0) [0|6425.5] "kPa" Vector__XXX

BO_ 2365456638 GPBAC: 8 Vector__XXX
 SG_ GeneratorPhaseBAcFrequency : 32|16@1+ (0.0078125,0) [0|501.9921875] "Hz" Vector__XXX
 SG_ GeneratorPhaseBAcRmsCurrent : 48|16@1+ (1,0) [0|64255] "A" Vector__XXX
 SG_ GnrtrPhsBLnLnARmsVltg : 0|16@1+ (1,0) [0|64255] "V" Vector__XXX
 SG_ GnrtrPhsBLnNtrlARmsVltg : 16|16@1+ (1,0) [0|64255] "V" Vector__XXX

BO_ 2351365886 MG1IC: 8 Vector__XXX
 SG_ MtrGnrtr1InvrtrCntrlCntr : 8|4@1+ (1,0) [0|15] "" Vector__XXX
 SG_ MtGt1IvtCtLtsRqstOvdMd : 12|4@1+ (1,0) [0|15] "" Vector__XXX
 SG_ MtrGnrtr1InvrtrCntrlStpntMdRqst : 43|5@1+ (1,0) [0|31] "" Vector__XXX
 SG_ MtrGnrtr1InvrtrCntrlStpntRqst : 48|16@1+ (0.00390625,-125) [-125|125.99609375] "%" Vector__XXX
 SG_ MtrGnrtr1InvrtrCntrlCr : 0|8@1+ (1,0) [0|250] "count" Vector__XXX
 SG_ MtGt1IvtCtLtsRqstOvdMx : 16|12@1+ (0.0625,-125) [-125|125.9375] "%" Vector__XXX
 SG_ MtGt1IvtCtLtsRqstOvdM : 28|12@1+ (0.0625,-125) [-125|125.9375] "%" Vector__XXX

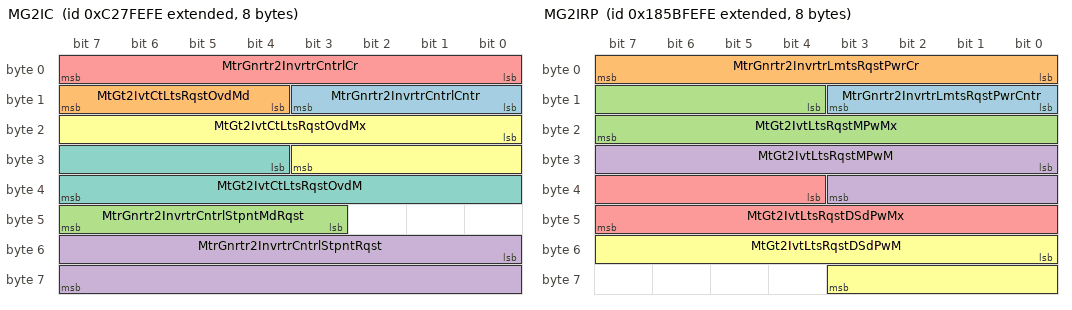
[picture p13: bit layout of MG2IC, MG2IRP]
BO_ 2351431422 MG2IC: 8 Vector__XXX
 SG_ MtrGnrtr2InvrtrCntrlCntr : 8|4@1+ (1,0) [0|15] "" Vector__XXX
 SG_ MtGt2IvtCtLtsRqstOvdMd : 12|4@1+ (1,0) [0|15] "" Vector__XXX
 SG_ MtrGnrtr2InvrtrCntrlStpntMdRqst : 43|5@1+ (1,0) [0|31] "" Vector__XXX
 SG_ MtrGnrtr2InvrtrCntrlStpntRqst : 48|16@1+ (0.00390625,-125) [-125|125.99609375] "%" Vector__XXX
 SG_ MtrGnrtr2InvrtrCntrlCr : 0|8@1+ (1,0) [0|250] "count" Vector__XXX
 SG_ MtGt2IvtCtLtsRqstOvdMx : 16|12@1+ (0.0625,-125) [-125|125.9375] "%" Vector__XXX
 SG_ MtGt2IvtCtLtsRqstOvdM : 28|12@1+ (0.0625,-125) [-125|125.9375] "%" Vector__XXX

BO_ 2556165886 MG2IRP: 8 Vector__XXX
 SG_ MtrGnrtr2InvrtrLmtsRqstPwrCntr : 8|4@1+ (1,0) [0|15] "" Vector__XXX
 SG_ MtrGnrtr2InvrtrLmtsRqstPwrCr : 0|8@1+ (1,0) [0|250] "count" Vector__XXX
 SG_ MtGt2IvtLtsRqstMPwMx : 12|12@1+ (0.0625,-125) [-125|125.9375] "%" Vector__XXX
 SG_ MtGt2IvtLtsRqstMPwM : 24|12@1+ (0.0625,-125) [-125|125.9375] "%" Vector__XXX
 SG_ MtGt2IvtLtsRqstDSdPwMx : 36|12@1+ (0.0625,-125) [-125|125.9375] "%" Vector__XXX
 SG_ MtGt2IvtLtsRqstDSdPwM : 48|12@1+ (0.0625,-125) [-125|125.9375] "%" Vector__XXX

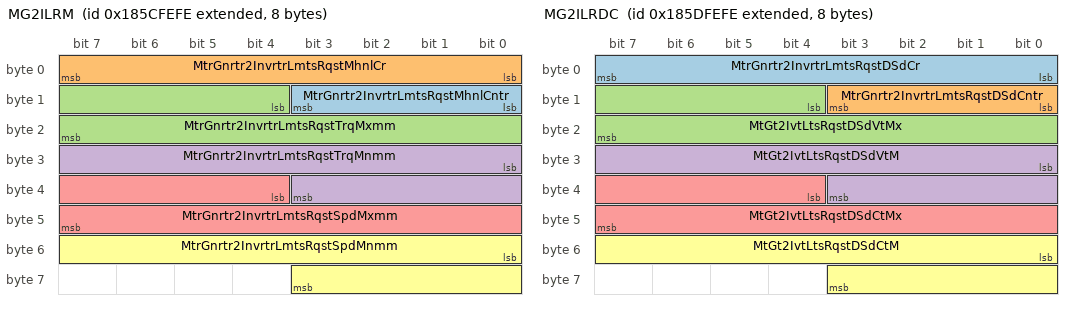
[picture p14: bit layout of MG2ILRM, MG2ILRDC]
BO_ 2556231422 MG2ILRM: 8 Vector__XXX
 SG_ MtrGnrtr2InvrtrLmtsRqstMhnlCntr : 8|4@1+ (1,0) [0|15] "" Vector__XXX
 SG_ MtrGnrtr2InvrtrLmtsRqstMhnlCr : 0|8@1+ (1,0) [0|250] "count" Vector__XXX
 SG_ MtrGnrtr2InvrtrLmtsRqstTrqMxmm : 12|12@1+ (0.0625,-125) [-125|125.9375] "%" Vector__XXX
 SG_ MtrGnrtr2InvrtrLmtsRqstTrqMnmm : 24|12@1+ (0.0625,-125) [-125|125.9375] "%" Vector__XXX
 SG_ MtrGnrtr2InvrtrLmtsRqstSpdMxmm : 36|12@1+ (0.0625,-125) [-125|125.9375] "%" Vector__XXX
 SG_ MtrGnrtr2InvrtrLmtsRqstSpdMnmm : 48|12@1+ (0.0625,-125) [-125|125.9375] "%" Vector__XXX

BO_ 2556296958 MG2ILRDC: 8 Vector__XXX
 SG_ MtrGnrtr2InvrtrLmtsRqstDSdCr : 0|8@1+ (1,0) [0|250] "count" Vector__XXX
 SG_ MtrGnrtr2InvrtrLmtsRqstDSdCntr : 8|4@1+ (1,0) [0|15] "" Vector__XXX
 SG_ MtGt2IvtLtsRqstDSdVtMx : 12|12@1+ (0.0625,-125) [-125|125.9375] "%" Vector__XXX
 SG_ MtGt2IvtLtsRqstDSdVtM : 24|12@1+ (0.0625,-125) [-125|125.9375] "%" Vector__XXX
 SG_ MtGt2IvtLtsRqstDSdCtMx : 36|12@1+ (0.0625,-125) [-125|125.9375] "%" Vector__XXX
 SG_ MtGt2IvtLtsRqstDSdCtM : 48|12@1+ (0.0625,-125) [-125|125.9375] "%" Vector__XXX

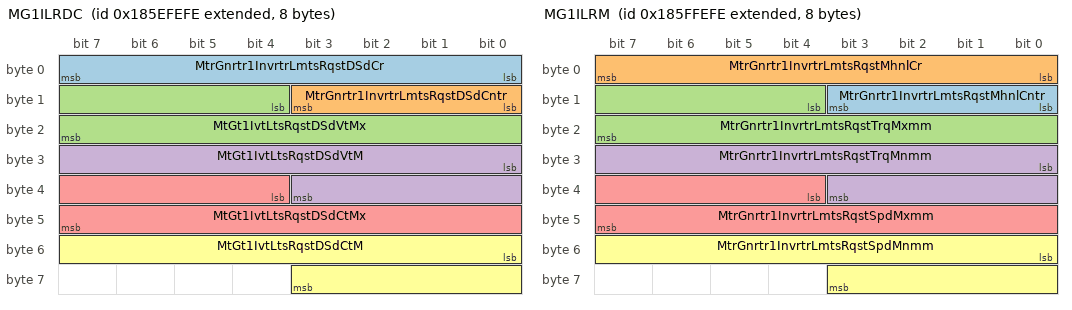
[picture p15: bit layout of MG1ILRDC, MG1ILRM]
BO_ 2556362494 MG1ILRDC: 8 Vector__XXX
 SG_ MtrGnrtr1InvrtrLmtsRqstDSdCr : 0|8@1+ (1,0) [0|250] "count" Vector__XXX
 SG_ MtrGnrtr1InvrtrLmtsRqstDSdCntr : 8|4@1+ (1,0) [0|15] "" Vector__XXX
 SG_ MtGt1IvtLtsRqstDSdVtMx : 12|12@1+ (0.0625,-125) [-125|125.9375] "%" Vector__XXX
 SG_ MtGt1IvtLtsRqstDSdVtM : 24|12@1+ (0.0625,-125) [-125|125.9375] "%" Vector__XXX
 SG_ MtGt1IvtLtsRqstDSdCtMx : 36|12@1+ (0.0625,-125) [-125|125.9375] "%" Vector__XXX
 SG_ MtGt1IvtLtsRqstDSdCtM : 48|12@1+ (0.0625,-125) [-125|125.9375] "%" Vector__XXX

BO_ 2556428030 MG1ILRM: 8 Vector__XXX
 SG_ MtrGnrtr1InvrtrLmtsRqstMhnlCntr : 8|4@1+ (1,0) [0|15] "" Vector__XXX
 SG_ MtrGnrtr1InvrtrLmtsRqstMhnlCr : 0|8@1+ (1,0) [0|250] "count" Vector__XXX
 SG_ MtrGnrtr1InvrtrLmtsRqstTrqMxmm : 12|12@1+ (0.0625,-125) [-125|125.9375] "%" Vector__XXX
 SG_ MtrGnrtr1InvrtrLmtsRqstTrqMnmm : 24|12@1+ (0.0625,-125) [-125|125.9375] "%" Vector__XXX
 SG_ MtrGnrtr1InvrtrLmtsRqstSpdMxmm : 36|12@1+ (0.0625,-125) [-125|125.9375] "%" Vector__XXX
 SG_ MtrGnrtr1InvrtrLmtsRqstSpdMnmm : 48|12@1+ (0.0625,-125) [-125|125.9375] "%" Vector__XXX

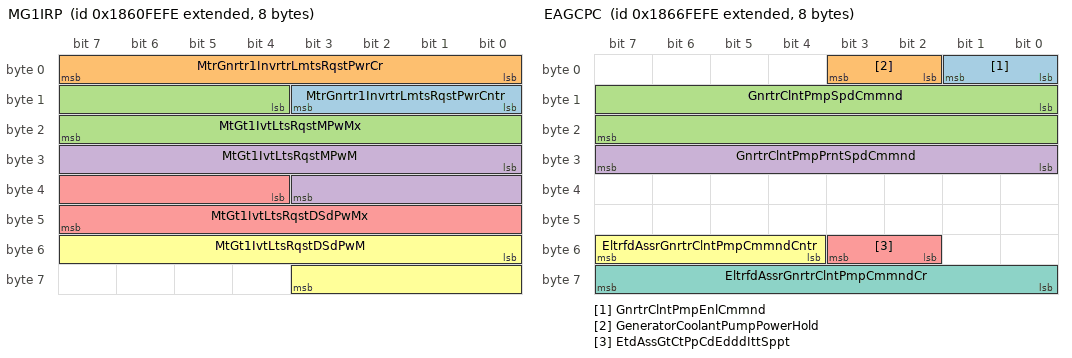
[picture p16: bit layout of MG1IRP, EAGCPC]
BO_ 2556493566 MG1IRP: 8 Vector__XXX
 SG_ MtrGnrtr1InvrtrLmtsRqstPwrCntr : 8|4@1+ (1,0) [0|15] "" Vector__XXX
 SG_ MtrGnrtr1InvrtrLmtsRqstPwrCr : 0|8@1+ (1,0) [0|250] "count" Vector__XXX
 SG_ MtGt1IvtLtsRqstMPwMx : 12|12@1+ (0.0625,-125) [-125|125.9375] "%" Vector__XXX
 SG_ MtGt1IvtLtsRqstMPwM : 24|12@1+ (0.0625,-125) [-125|125.9375] "%" Vector__XXX
 SG_ MtGt1IvtLtsRqstDSdPwMx : 36|12@1+ (0.0625,-125) [-125|125.9375] "%" Vector__XXX
 SG_ MtGt1IvtLtsRqstDSdPwM : 48|12@1+ (0.0625,-125) [-125|125.9375] "%" Vector__XXX

BO_ 2556559102 PDI: 8 Vector__XXX
 SG_ PrsnnlDttAlrmRvStts : 0|3@1+ (1,0) [0|7] "" Vector__XXX
 SG_ PrsnnlDttSqnCntrEh : 8|8@1+ (1,0) [0|250] "count" Vector__XXX

BO_ 2556624638 ECCCF: 8 Vector__XXX
 SG_ CnfgrdEngnClndrMssFrtnBrndLtn1 : 0|8@1+ (0.4,0) [0|100] "%" Vector__XXX
 SG_ CnfgrdEngnClndrMssFrtnBrndLtn2 : 8|8@1+ (0.4,0) [0|100] "%" Vector__XXX

BO_ 2556690174 ECCC: 8 Vector__XXX
 SG_ EngnClndrMssFrtnBrndLtn1 : 0|8@1+ (0.4,0) [0|100] "%" Vector__XXX
 SG_ EngnClndrMssFrtnBrndLtn2 : 8|8@1+ (0.4,0) [0|100] "%" Vector__XXX

BO_ 2556755710 ECPTF: 8 Vector__XXX
 SG_ CnfgrdEngnClndrPrssrTmng1 : 0|16@1+ (0.0125,-360) [-360|360] "deg" Vector__XXX
 SG_ CnfgrdEngnClndrPrssrTmng2 : 16|16@1+ (0.0125,-360) [-360|360] "deg" Vector__XXX
 SG_ CnfgrdEngnClndrPrssrTmng3 : 32|16@1+ (0.0125,-360) [-360|360] "deg" Vector__XXX
 SG_ CnfgrdEngnClndrPrssrTmng4 : 48|16@1+ (0.0125,-360) [-360|360] "deg" Vector__XXX

BO_ 2556821246 ECPTC: 8 Vector__XXX
 SG_ EngineCylinderPressureTiming1 : 0|16@1+ (0.0125,-360) [-360|360] "deg" Vector__XXX
 SG_ EngineCylinderPressureTiming2 : 16|16@1+ (0.0125,-360) [-360|360] "deg" Vector__XXX
 SG_ EngineCylinderPressureTiming3 : 32|16@1+ (0.0125,-360) [-360|360] "deg" Vector__XXX
 SG_ EngineCylinderPressureTiming4 : 48|16@1+ (0.0125,-360) [-360|360] "deg" Vector__XXX

BO_ 2556886782 EAGCPC: 8 Vector__XXX
 SG_ GnrtrClntPmpEnlCmmnd : 0|2@1+ (1,0) [0|3] "" Vector__XXX
 SG_ GeneratorCoolantPumpPowerHold : 2|2@1+ (1,0) [0|3] "" Vector__XXX
 SG_ GnrtrClntPmpSpdCmmnd : 8|16@1+ (0.5,0) [0|32127.5] "rpm" Vector__XXX
 SG_ GnrtrClntPmpPrntSpdCmmnd : 24|8@1+ (0.5,0) [0|100] "%" Vector__XXX
 SG_ EtdAssGtCtPpCdEdddIttSppt : 50|2@1+ (1,0) [0|3] "" Vector__XXX
 SG_ EltrfdAssrGnrtrClntPmpCmmndCntr : 52|4@1+ (1,0) [0|15] "count" Vector__XXX
 SG_ EltrfdAssrGnrtrClntPmpCmmndCr : 56|8@1+ (1,0) [0|250] "count" Vector__XXX

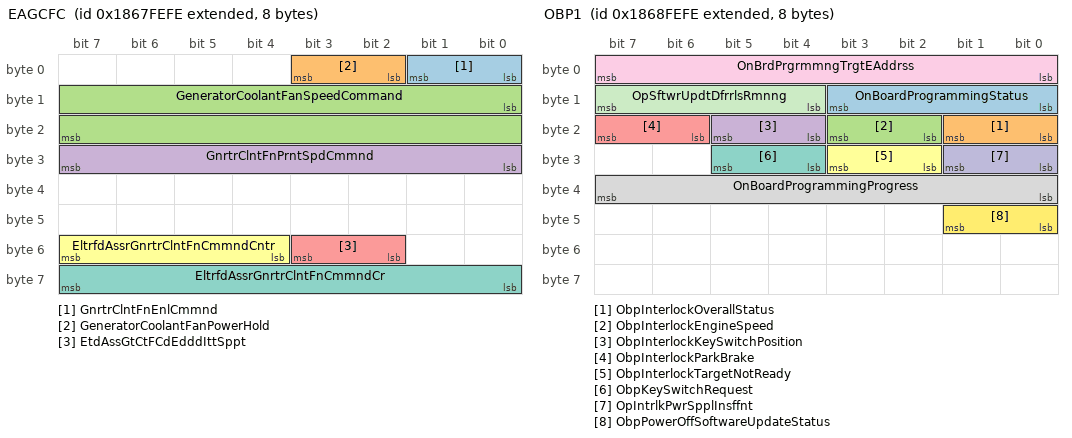
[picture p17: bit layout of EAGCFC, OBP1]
BO_ 2556952318 EAGCFC: 8 Vector__XXX
 SG_ GnrtrClntFnEnlCmmnd : 0|2@1+ (1,0) [0|3] "" Vector__XXX
 SG_ GeneratorCoolantFanPowerHold : 2|2@1+ (1,0) [0|3] "" Vector__XXX
 SG_ GeneratorCoolantFanSpeedCommand : 8|16@1+ (0.5,0) [0|32127.5] "rpm" Vector__XXX
 SG_ GnrtrClntFnPrntSpdCmmnd : 24|8@1+ (0.5,0) [0|100] "%" Vector__XXX
 SG_ EtdAssGtCtFCdEdddIttSppt : 50|2@1+ (1,0) [0|3] "" Vector__XXX
 SG_ EltrfdAssrGnrtrClntFnCmmndCntr : 52|4@1+ (1,0) [0|15] "count" Vector__XXX
 SG_ EltrfdAssrGnrtrClntFnCmmndCr : 56|8@1+ (1,0) [0|250] "count" Vector__XXX

BO_ 2557017854 OBP1: 8 Vector__XXX
 SG_ OnBoardProgrammingStatus : 8|4@1+ (1,0) [0|15] "" Vector__XXX
 SG_ ObpInterlockOverallStatus : 16|2@1+ (1,0) [0|3] "" Vector__XXX
 SG_ ObpInterlockEngineSpeed : 18|2@1+ (1,0) [0|3] "" Vector__XXX
 SG_ ObpInterlockKeySwitchPosition : 20|2@1+ (1,0) [0|3] "" Vector__XXX
 SG_ ObpInterlockParkBrake : 22|2@1+ (1,0) [0|3] "" Vector__XXX
 SG_ ObpInterlockTargetNotReady : 26|2@1+ (1,0) [0|3] "" Vector__XXX
 SG_ ObpKeySwitchRequest : 28|2@1+ (1,0) [0|3] "" Vector__XXX
 SG_ OnBoardProgrammingProgress : 32|8@1+ (0.5,0) [0|100] "%" Vector__XXX
 SG_ OnBrdPrgrmmngTrgtEAddrss : 0|8@1+ (1,0) [0|250] "sourceadr" Vector__XXX
 SG_ OpIntrlkPwrSpplInsffnt : 24|2@1+ (1,0) [0|3] "" Vector__XXX
 SG_ OpSftwrUpdtDfrrlsRmnng : 12|4@1+ (1,0) [0|15] "count" Vector__XXX
 SG_ ObpPowerOffSoftwareUpdateStatus : 40|2@1+ (1,0) [0|3] "" Vector__XXX

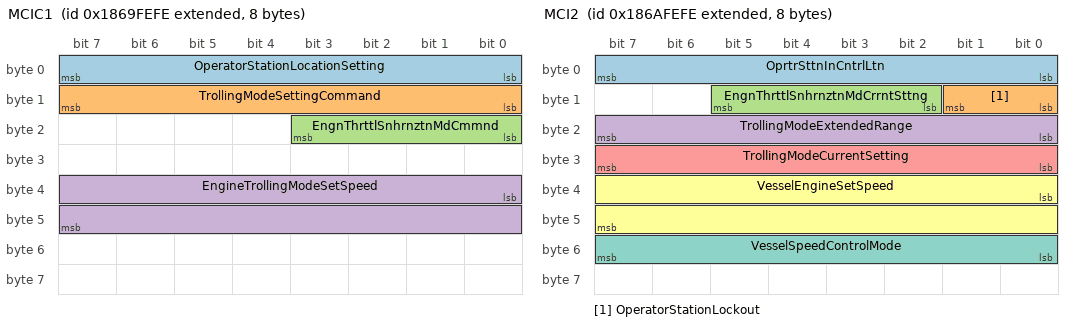
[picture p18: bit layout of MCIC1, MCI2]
BO_ 2557083390 MCIC1: 8 Vector__XXX
 SG_ OperatorStationLocationSetting : 0|8@1+ (1,0) [0|250] "ID" Vector__XXX
 SG_ TrollingModeSettingCommand : 8|8@1+ (1,0) [0|250] "" Vector__XXX
 SG_ EngnThrttlSnhrnztnMdCmmnd : 16|4@1+ (1,0) [0|15] "" Vector__XXX
 SG_ EngineTrollingModeSetSpeed : 32|16@1+ (0.125,0) [0|8031.875] "rpm" Vector__XXX

BO_ 2557148926 MCI2: 8 Vector__XXX
 SG_ OprtrSttnInCntrlLtn : 0|8@1+ (1,0) [0|250] "ID" Vector__XXX
 SG_ OperatorStationLockout : 8|2@1+ (1,0) [0|3] "" Vector__XXX
 SG_ EngnThrttlSnhrnztnMdCrrntSttng : 10|4@1+ (1,0) [0|15] "" Vector__XXX
 SG_ TrollingModeExtendedRange : 16|8@1+ (1,0) [0|250] "" Vector__XXX
 SG_ TrollingModeCurrentSetting : 24|8@1+ (1,0) [0|250] "" Vector__XXX
 SG_ VesselEngineSetSpeed : 32|16@1+ (0.125,0) [0|8031.875] "rpm" Vector__XXX
 SG_ VesselSpeedControlMode : 48|8@1+ (1,0) [0|250] "" Vector__XXX

BO_ 2364617726 EPCVDC1: 8 Vector__XXX
 SG_ EngnPrChmrFlVlv1Drtn : 0|16@1+ (2,0) [0|128510] "micro s" Vector__XXX
 SG_ EngnPrChmrFlVlv2Drtn : 16|16@1+ (2,0) [0|128510] "micro s" Vector__XXX
 SG_ EngnPrChmrFlVlv3Drtn : 32|16@1+ (2,0) [0|128510] "micro s" Vector__XXX
 SG_ EngnPrChmrFlVlv4Drtn : 48|16@1+ (2,0) [0|128510] "micro s" Vector__XXX

BO_ 2364617982 EPCVDC2: 8 Vector__XXX
 SG_ EngnPrChmrFlVlv5Drtn : 0|16@1+ (2,0) [0|128510] "micro s" Vector__XXX
 SG_ EngnPrChmrFlVlv6Drtn : 16|16@1+ (2,0) [0|128510] "micro s" Vector__XXX
 SG_ EngnPrChmrFlVlv7Drtn : 32|16@1+ (2,0) [0|128510] "micro s" Vector__XXX
 SG_ EngnPrChmrFlVlv8Drtn : 48|16@1+ (2,0) [0|128510] "micro s" Vector__XXX

BO_ 2364618238 EPCVDC3: 8 Vector__XXX
 SG_ EngnPrChmrFlVlv9Drtn : 0|16@1+ (2,0) [0|128510] "micro s" Vector__XXX
 SG_ EngnPrChmrFlVlv10Drtn : 16|16@1+ (2,0) [0|128510] "micro s" Vector__XXX
 SG_ EngnPrChmrFlVlv11Drtn : 32|16@1+ (2,0) [0|128510] "micro s" Vector__XXX
 SG_ EngnPrChmrFlVlv12Drtn : 48|16@1+ (2,0) [0|128510] "micro s" Vector__XXX

BO_ 2364618494 EPCVDC4: 8 Vector__XXX
 SG_ EngnPrChmrFlVlv13Drtn : 0|16@1+ (2,0) [0|128510] "micro s" Vector__XXX
 SG_ EngnPrChmrFlVlv14Drtn : 16|16@1+ (2,0) [0|128510] "micro s" Vector__XXX
 SG_ EngnPrChmrFlVlv15Drtn : 32|16@1+ (2,0) [0|128510] "micro s" Vector__XXX
 SG_ EngnPrChmrFlVlv16Drtn : 48|16@1+ (2,0) [0|128510] "micro s" Vector__XXX

BO_ 2364618750 EPCVDC5: 8 Vector__XXX
 SG_ EngnPrChmrFlVlv17Drtn : 0|16@1+ (2,0) [0|128510] "micro s" Vector__XXX
 SG_ EngnPrChmrFlVlv18Drtn : 16|16@1+ (2,0) [0|128510] "micro s" Vector__XXX
 SG_ EngnPrChmrFlVlv19Drtn : 32|16@1+ (2,0) [0|128510] "micro s" Vector__XXX
 SG_ EngnPrChmrFlVlv20Drtn : 48|16@1+ (2,0) [0|128510] "micro s" Vector__XXX

BO_ 2364619006 EPCSOAC1: 8 Vector__XXX
 SG_ EngnPrChmrFlVlv1StrtOfAttnCmmnd : 0|16@1+ (0.0078125,-400) [-400|101.9921875] "deg" Vector__XXX
 SG_ EngnPrChmrFlVlv2StrtOfAttnCmmnd : 16|16@1+ (0.0078125,-400) [-400|101.9921875] "deg" Vector__XXX
 SG_ EngnPrChmrFlVlv3StrtOfAttnCmmnd : 32|16@1+ (0.0078125,-400) [-400|101.9921875] "deg" Vector__XXX
 SG_ EngnPrChmrFlVlv4StrtOfAttnCmmnd : 48|16@1+ (0.0078125,-400) [-400|101.9921875] "deg" Vector__XXX

BO_ 2364619262 EPCSOAC2: 8 Vector__XXX
 SG_ EngnPrChmrFlVlv5StrtOfAttnCmmnd : 0|16@1+ (0.0078125,-400) [-400|101.9921875] "deg" Vector__XXX
 SG_ EngnPrChmrFlVlv6StrtOfAttnCmmnd : 16|16@1+ (0.0078125,-400) [-400|101.9921875] "deg" Vector__XXX
 SG_ EngnPrChmrFlVlv7StrtOfAttnCmmnd : 32|16@1+ (0.0078125,-400) [-400|101.9921875] "deg" Vector__XXX
 SG_ EngnPrChmrFlVlv8StrtOfAttnCmmnd : 48|16@1+ (0.0078125,-400) [-400|101.9921875] "deg" Vector__XXX

BO_ 2364619518 EPCSOAC3: 8 Vector__XXX
 SG_ EngnPrChmrFlVlv9StrtOfAttnCmmnd : 0|16@1+ (0.0078125,-400) [-400|101.9921875] "deg" Vector__XXX
 SG_ EPCFVv10SttOAttCd : 16|16@1+ (0.0078125,-400) [-400|101.9921875] "deg" Vector__XXX
 SG_ EPCFVv11SttOAttCd : 32|16@1+ (0.0078125,-400) [-400|101.9921875] "deg" Vector__XXX
 SG_ EPCFVv12SttOAttCd : 48|16@1+ (0.0078125,-400) [-400|101.9921875] "deg" Vector__XXX

BO_ 2364619774 EPCSOAC4: 8 Vector__XXX
 SG_ EPCFVv13SttOAttCd : 0|16@1+ (0.0078125,-400) [-400|101.9921875] "deg" Vector__XXX
 SG_ EPCFVv14SttOAttCd : 16|16@1+ (0.0078125,-400) [-400|101.9921875] "deg" Vector__XXX
 SG_ EPCFVv15SttOAttCd : 32|16@1+ (0.0078125,-400) [-400|101.9921875] "deg" Vector__XXX
 SG_ EPCFVv16SttOAttCd : 48|16@1+ (0.0078125,-400) [-400|101.9921875] "deg" Vector__XXX

BO_ 2364620030 EPCSOAC5: 8 Vector__XXX
 SG_ EPCFVv17SttOAttCd : 0|16@1+ (0.0078125,-400) [-400|101.9921875] "deg" Vector__XXX
 SG_ EPCFVv18SttOAttCd : 16|16@1+ (0.0078125,-400) [-400|101.9921875] "deg" Vector__XXX
 SG_ EPCFVv19SttOAttCd : 32|16@1+ (0.0078125,-400) [-400|101.9921875] "deg" Vector__XXX
 SG_ EPCFVv20SttOAttCd : 48|16@1+ (0.0078125,-400) [-400|101.9921875] "deg" Vector__XXX

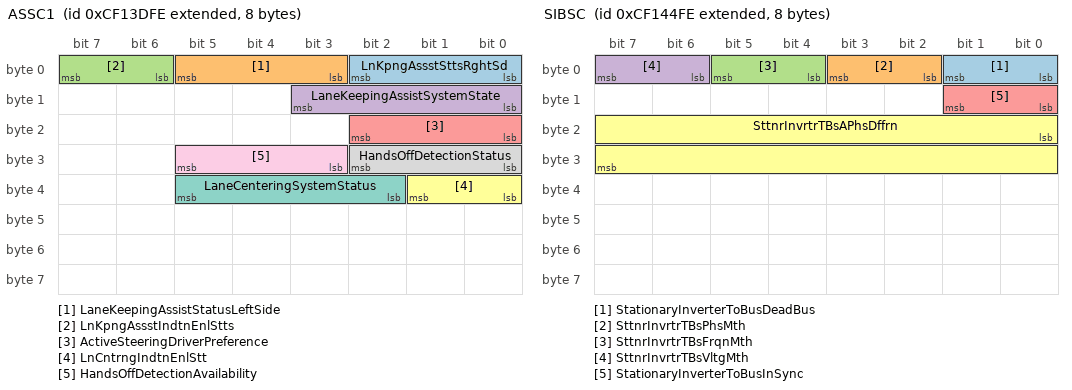
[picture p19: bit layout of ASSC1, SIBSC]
BO_ 2364620286 ASSC1: 8 Vector__XXX
 SG_ LnKpngAssstSttsRghtSd : 0|3@1+ (1,0) [0|7] "" Vector__XXX
 SG_ LaneKeepingAssistStatusLeftSide : 3|3@1+ (1,0) [0|7] "" Vector__XXX
 SG_ LnKpngAssstIndtnEnlStts : 6|2@1+ (1,0) [0|3] "" Vector__XXX
 SG_ LaneKeepingAssistSystemState : 8|4@1+ (1,0) [0|15] "" Vector__XXX
 SG_ ActiveSteeringDriverPreference : 16|3@1+ (1,0) [0|7] "" Vector__XXX
 SG_ LnCntrngIndtnEnlStt : 32|2@1+ (1,0) [0|3] "" Vector__XXX
 SG_ LaneCenteringSystemStatus : 34|4@1+ (1,0) [0|15] "" Vector__XXX
 SG_ HandsOffDetectionStatus : 24|3@1+ (1,0) [0|7] "" Vector__XXX
 SG_ HandsOffDetectionAvailability : 27|3@1+ (1,0) [0|7] "" Vector__XXX

BO_ 2364621054 SIAAC: 8 Vector__XXX
 SG_ SttnrInvrtrAvrgARmsVltg : 0|16@1+ (1,0) [0|64255] "V" Vector__XXX
 SG_ SttnrInvrtrAvrgLnNtrlARmsVltg : 16|16@1+ (1,0) [0|64255] "V" Vector__XXX
 SG_ SttnrInvrtrAvrgAFrqn : 32|16@1+ (0.0078125,0) [0|501.9921875] "Hz" Vector__XXX
 SG_ SttnrInvrtrAvrgARmsCrrnt : 48|16@1+ (1,0) [0|64255] "A" Vector__XXX

BO_ 2364621310 SITACR: 8 Vector__XXX
 SG_ SttnrInvrtrTtlRtvPwr : 0|32@1+ (1,-2000000000) [-2000000000|2211081215] "VAr" Vector__XXX
 SG_ SttnrInvrtrOvrllPwrFtr : 32|16@1+ (0.00006103515625,-1) [-1|2.92181396484375] "" Vector__XXX
 SG_ SttnrInvrtrOvrllPwrFtrLggng : 48|2@1+ (1,0) [0|3] "" Vector__XXX

BO_ 2364621566 SITACP: 8 Vector__XXX
 SG_ SttnrInvrtrTtlRlPwr : 0|32@1+ (1,-2000000000) [-2000000000|2211081215] "W" Vector__XXX
 SG_ SttnrInvrtrTtlApprntPwr : 32|32@1+ (1,-2000000000) [-2000000000|2211081215] "VA" Vector__XXX

BO_ 2364621822 SIC: 8 Vector__XXX
 SG_ SttnrInvrtrNtRdTAtmtllPrlllStt : 0|2@1+ (1,0) [0|3] "" Vector__XXX
 SG_ SttnrInvrtrAxlrShtdwnSwth : 2|2@1+ (1,0) [0|3] "" Vector__XXX

BO_ 2364622078 SIBSC: 8 Vector__XXX
 SG_ StationaryInverterToBusDeadBus : 0|2@1+ (1,0) [0|3] "" Vector__XXX
 SG_ SttnrInvrtrTBsPhsMth : 2|2@1+ (1,0) [0|3] "" Vector__XXX
 SG_ SttnrInvrtrTBsFrqnMth : 4|2@1+ (1,0) [0|3] "" Vector__XXX
 SG_ SttnrInvrtrTBsVltgMth : 6|2@1+ (1,0) [0|3] "" Vector__XXX
 SG_ StationaryInverterToBusInSync : 8|2@1+ (1,0) [0|3] "" Vector__XXX
 SG_ SttnrInvrtrTBsAPhsDffrn : 16|16@1+ (0.0078125,-200) [-200|301.9921875] "deg" Vector__XXX

BO_ 2364622334 ECCP1: 8 Vector__XXX
 SG_ EngineCylinder1Timing1Pressure : 0|16@1+ (0.0009765625,0) [0|62.7490234375] "MPa" Vector__XXX
 SG_ EngineCylinder1Timing2Pressure : 16|16@1+ (0.0009765625,0) [0|62.7490234375] "MPa" Vector__XXX
 SG_ EngineCylinder1Timing3Pressure : 32|16@1+ (0.0009765625,0) [0|62.7490234375] "MPa" Vector__XXX
 SG_ EngineCylinder1Timing4Pressure : 48|16@1+ (0.0009765625,0) [0|62.7490234375] "MPa" Vector__XXX

BO_ 2364622590 ECCP2: 8 Vector__XXX
 SG_ EngineCylinder2Timing1Pressure : 0|16@1+ (0.0009765625,0) [0|62.7490234375] "MPa" Vector__XXX
 SG_ EngineCylinder2Timing2Pressure : 16|16@1+ (0.0009765625,0) [0|62.7490234375] "MPa" Vector__XXX
 SG_ EngineCylinder2Timing3Pressure : 32|16@1+ (0.0009765625,0) [0|62.7490234375] "MPa" Vector__XXX
 SG_ EngineCylinder2Timing4Pressure : 48|16@1+ (0.0009765625,0) [0|62.7490234375] "MPa" Vector__XXX

BO_ 2364622846 ECCP3: 8 Vector__XXX
 SG_ EngineCylinder3Timing1Pressure : 0|16@1+ (0.0009765625,0) [0|62.7490234375] "MPa" Vector__XXX
 SG_ EngineCylinder3Timing2Pressure : 16|16@1+ (0.0009765625,0) [0|62.7490234375] "MPa" Vector__XXX
 SG_ EngineCylinder3Timing3Pressure : 32|16@1+ (0.0009765625,0) [0|62.7490234375] "MPa" Vector__XXX
 SG_ EngineCylinder3Timing4Pressure : 48|16@1+ (0.0009765625,0) [0|62.7490234375] "MPa" Vector__XXX

BO_ 2364623102 ECCP4: 8 Vector__XXX
 SG_ EngineCylinder4Timing1Pressure : 0|16@1+ (0.0009765625,0) [0|62.7490234375] "MPa" Vector__XXX
 SG_ EngineCylinder4Timing2Pressure : 16|16@1+ (0.0009765625,0) [0|62.7490234375] "MPa" Vector__XXX
 SG_ EngineCylinder4Timing3Pressure : 32|16@1+ (0.0009765625,0) [0|62.7490234375] "MPa" Vector__XXX
 SG_ EngineCylinder4Timing4Pressure : 48|16@1+ (0.0009765625,0) [0|62.7490234375] "MPa" Vector__XXX

BO_ 2364623358 ECCP5: 8 Vector__XXX
 SG_ EngineCylinder5Timing1Pressure : 0|16@1+ (0.0009765625,0) [0|62.7490234375] "MPa" Vector__XXX
 SG_ EngineCylinder5Timing2Pressure : 16|16@1+ (0.0009765625,0) [0|62.7490234375] "MPa" Vector__XXX
 SG_ EngineCylinder5Timing3Pressure : 32|16@1+ (0.0009765625,0) [0|62.7490234375] "MPa" Vector__XXX
 SG_ EngineCylinder5Timing4Pressure : 48|16@1+ (0.0009765625,0) [0|62.7490234375] "MPa" Vector__XXX

BO_ 2364623614 ECCP6: 8 Vector__XXX
 SG_ EngineCylinder6Timing1Pressure : 0|16@1+ (0.0009765625,0) [0|62.7490234375] "MPa" Vector__XXX
 SG_ EngineCylinder6Timing2Pressure : 16|16@1+ (0.0009765625,0) [0|62.7490234375] "MPa" Vector__XXX
 SG_ EngineCylinder6Timing3Pressure : 32|16@1+ (0.0009765625,0) [0|62.7490234375] "MPa" Vector__XXX
 SG_ EngineCylinder6Timing4Pressure : 48|16@1+ (0.0009765625,0) [0|62.7490234375] "MPa" Vector__XXX

BO_ 2364623870 ECCP7: 8 Vector__XXX
 SG_ EngineCylinder7Timing1Pressure : 0|16@1+ (0.0009765625,0) [0|62.7490234375] "MPa" Vector__XXX
 SG_ EngineCylinder7Timing2Pressure : 16|16@1+ (0.0009765625,0) [0|62.7490234375] "MPa" Vector__XXX
 SG_ EngineCylinder7Timing3Pressure : 32|16@1+ (0.0009765625,0) [0|62.7490234375] "MPa" Vector__XXX
 SG_ EngineCylinder7Timing4Pressure : 48|16@1+ (0.0009765625,0) [0|62.7490234375] "MPa" Vector__XXX

BO_ 2364624126 ECCP8: 8 Vector__XXX
 SG_ EngineCylinder8Timing1Pressure : 0|16@1+ (0.0009765625,0) [0|62.7490234375] "MPa" Vector__XXX
 SG_ EngineCylinder8Timing2Pressure : 16|16@1+ (0.0009765625,0) [0|62.7490234375] "MPa" Vector__XXX
 SG_ EngineCylinder8Timing3Pressure : 32|16@1+ (0.0009765625,0) [0|62.7490234375] "MPa" Vector__XXX
 SG_ EngineCylinder8Timing4Pressure : 48|16@1+ (0.0009765625,0) [0|62.7490234375] "MPa" Vector__XXX

BO_ 2364624382 ECCP9: 8 Vector__XXX
 SG_ EngineCylinder9Timing1Pressure : 0|16@1+ (0.0009765625,0) [0|62.7490234375] "MPa" Vector__XXX
 SG_ EngineCylinder9Timing2Pressure : 16|16@1+ (0.0009765625,0) [0|62.7490234375] "MPa" Vector__XXX
 SG_ EngineCylinder9Timing3Pressure : 32|16@1+ (0.0009765625,0) [0|62.7490234375] "MPa" Vector__XXX
 SG_ EngineCylinder9Timing4Pressure : 48|16@1+ (0.0009765625,0) [0|62.7490234375] "MPa" Vector__XXX

BO_ 2364624638 ECCP10: 8 Vector__XXX
 SG_ EngineCylinder10Timing1Pressure : 0|16@1+ (0.0009765625,0) [0|62.7490234375] "MPa" Vector__XXX
 SG_ EngineCylinder10Timing2Pressure : 16|16@1+ (0.0009765625,0) [0|62.7490234375] "MPa" Vector__XXX
 SG_ EngineCylinder10Timing3Pressure : 32|16@1+ (0.0009765625,0) [0|62.7490234375] "MPa" Vector__XXX
 SG_ EngineCylinder10Timing4Pressure : 48|16@1+ (0.0009765625,0) [0|62.7490234375] "MPa" Vector__XXX

BO_ 2364624894 ECCP11: 8 Vector__XXX
 SG_ EngineCylinder11Timing1Pressure : 0|16@1+ (0.0009765625,0) [0|62.7490234375] "MPa" Vector__XXX
 SG_ EngineCylinder11Timing2Pressure : 16|16@1+ (0.0009765625,0) [0|62.7490234375] "MPa" Vector__XXX
 SG_ EngineCylinder11Timing3Pressure : 32|16@1+ (0.0009765625,0) [0|62.7490234375] "MPa" Vector__XXX
 SG_ EngineCylinder11Timing4Pressure : 48|16@1+ (0.0009765625,0) [0|62.7490234375] "MPa" Vector__XXX

BO_ 2364625150 ECCP12: 8 Vector__XXX
 SG_ EngineCylinder12Timing1Pressure : 0|16@1+ (0.0009765625,0) [0|62.7490234375] "MPa" Vector__XXX
 SG_ EngineCylinder12Timing2Pressure : 16|16@1+ (0.0009765625,0) [0|62.7490234375] "MPa" Vector__XXX
 SG_ EngineCylinder12Timing3Pressure : 32|16@1+ (0.0009765625,0) [0|62.7490234375] "MPa" Vector__XXX
 SG_ EngineCylinder12Timing4Pressure : 48|16@1+ (0.0009765625,0) [0|62.7490234375] "MPa" Vector__XXX

BO_ 2364625406 ECCP13: 8 Vector__XXX
 SG_ EngineCylinder13Timing1Pressure : 0|16@1+ (0.0009765625,0) [0|62.7490234375] "MPa" Vector__XXX
 SG_ EngineCylinder13Timing2Pressure : 16|16@1+ (0.0009765625,0) [0|62.7490234375] "MPa" Vector__XXX
 SG_ EngineCylinder13Timing3Pressure : 32|16@1+ (0.0009765625,0) [0|62.7490234375] "MPa" Vector__XXX
 SG_ EngineCylinder13Timing4Pressure : 48|16@1+ (0.0009765625,0) [0|62.7490234375] "MPa" Vector__XXX

BO_ 2364625662 ECCP14: 8 Vector__XXX
 SG_ EngineCylinder14Timing1Pressure : 0|16@1+ (0.0009765625,0) [0|62.7490234375] "MPa" Vector__XXX
 SG_ EngineCylinder14Timing2Pressure : 16|16@1+ (0.0009765625,0) [0|62.7490234375] "MPa" Vector__XXX
 SG_ EngineCylinder14Timing3Pressure : 32|16@1+ (0.0009765625,0) [0|62.7490234375] "MPa" Vector__XXX
 SG_ EngineCylinder14Timing4Pressure : 48|16@1+ (0.0009765625,0) [0|62.7490234375] "MPa" Vector__XXX

BO_ 2364625918 ECCP15: 8 Vector__XXX
 SG_ EngineCylinder15Timing1Pressure : 0|16@1+ (0.0009765625,0) [0|62.7490234375] "MPa" Vector__XXX
 SG_ EngineCylinder15Timing2Pressure : 16|16@1+ (0.0009765625,0) [0|62.7490234375] "MPa" Vector__XXX
 SG_ EngineCylinder15Timing3Pressure : 32|16@1+ (0.0009765625,0) [0|62.7490234375] "MPa" Vector__XXX
 SG_ EngineCylinder15Timing4Pressure : 48|16@1+ (0.0009765625,0) [0|62.7490234375] "MPa" Vector__XXX

BO_ 2364626174 ECCP16: 8 Vector__XXX
 SG_ EngineCylinder16Timing1Pressure : 0|16@1+ (0.0009765625,0) [0|62.7490234375] "MPa" Vector__XXX
 SG_ EngineCylinder16Timing2Pressure : 16|16@1+ (0.0009765625,0) [0|62.7490234375] "MPa" Vector__XXX
 SG_ EngineCylinder16Timing3Pressure : 32|16@1+ (0.0009765625,0) [0|62.7490234375] "MPa" Vector__XXX
 SG_ EngineCylinder16Timing4Pressure : 48|16@1+ (0.0009765625,0) [0|62.7490234375] "MPa" Vector__XXX

CM_ BO_ 2633924094 "Combustion Time 3";
CM_ SG_ 2633924094 EngineCylinder10CombustionTime "Engine Cylinder #10 Combustion Time: The amount of time from when the ignition of the fuel is initiated to when the fuel is completely ignited (i.e., the flame front has propagated across the cylinder).";
CM_ SG_ 2633924094 EngineCylinder11CombustionTime "Engine Cylinder #11 Combustion Time: The amount of time from when the ignition of the fuel is initiated to when the fuel is completely ignited (i.e., the flame front has propagated across the cylinder).";
CM_ SG_ 2633924094 EngineCylinder12CombustionTime "Engine Cylinder #12 Combustion Time: The amount of time from when the ignition of the fuel is initiated to when the fuel is completely ignited (i.e., the flame front has propagated across the cylinder).";
CM_ SG_ 2633924094 EngineCylinder9CombustionTime "Engine Cylinder #9 Combustion Time: The amount of time from when the ignition of the fuel is initiated to when the fuel is completely ignited (i.e., the flame front has propagated across the cylinder).";
CM_ BO_ 2633924350 "Combustion Time 4";
CM_ SG_ 2633924350 EngineCylinder13CombustionTime "Engine Cylinder #13 Combustion Time: The amount of time from when the ignition of the fuel is initiated to when the fuel is completely ignited (i.e., the flame front has propagated across the cylinder).";
CM_ SG_ 2633924350 EngineCylinder14CombustionTime "Engine Cylinder #14 Combustion Time: The amount of time from when the ignition of the fuel is initiated to when the fuel is completely ignited (i.e., the flame front has propagated across the cylinder).";
CM_ SG_ 2633924350 EngineCylinder15CombustionTime "Engine Cylinder #15 Combustion Time: The amount of time from when the ignition of the fuel is initiated to when the fuel is completely ignited (i.e., the flame front has propagated across the cylinder).";
CM_ SG_ 2633924350 EngineCylinder16CombustionTime "Engine Cylinder #16 Combustion Time: The amount of time from when the ignition of the fuel is initiated to when the fuel is completely ignited (i.e., the flame front has propagated across the cylinder).";
CM_ BO_ 2633924606 "Combustion Time 5";
CM_ SG_ 2633924606 EngineCylinder17CombustionTime "Engine Cylinder #17 Combustion Time: The amount of time from when the ignition of the fuel is initiated to when the fuel is completely ignited (i.e., the flame front has propagated across the cylinder).";
CM_ SG_ 2633924606 EngineCylinder18CombustionTime "Engine Cylinder #18 Combustion Time: The amount of time from when the ignition of the fuel is initiated to when the fuel is completely ignited (i.e., the flame front has propagated across the cylinder).";
CM_ SG_ 2633924606 EngineCylinder19CombustionTime "Engine Cylinder #19 Combustion Time: The amount of time from when the ignition of the fuel is initiated to when the fuel is completely ignited (i.e., the flame front has propagated across the cylinder).";
CM_ SG_ 2633924606 EngineCylinder20CombustionTime "Engine Cylinder #20 Combustion Time: The amount of time from when the ignition of the fuel is initiated to when the fuel is completely ignited (i.e., the flame front has propagated across the cylinder).";
CM_ BO_ 2633924862 "Combustion Time 6";
CM_ SG_ 2633924862 EngineAverageCombustionTime "Engine Average Combustion Time: The average combustion time of all cylinders of an engine.";
CM_ SG_ 2633924862 EngineDesiredCombustionTime "Engine Desired Combustion Time: The desired combustion time based upon engine load and speed lookup maps.";
CM_ BO_ 2633925118 "Fuel Information 2 (Gaseous)";
CM_ SG_ 2633925118 EngineFuelFlowRate1 "Engine Fuel Flow Rate 1: The rate at which the fuel is flowing through a fuel valve.";
CM_ SG_ 2633925118 EngineFuelFlowRate2 "Engine Fuel Flow Rate 2: The rate at which the fuel is flowing through a fuel valve.";
CM_ SG_ 2633925118 EngineFuelValve1Position "Engine Fuel Valve 1 Position: The position of a gaseous fuel valve that is metering the fuel flow to the engine.  0% indicates no fuel flow through valve and 100% means maximum fuel flow through valve.";
CM_ SG_ 2633925118 EngineFuelValve2Position "Engine Fuel Valve 2 Position: The position of a gaseous fuel valve that is metering the fuel flow to the engine.  0% indicates no fuel flow through valve and 100% means maximum fuel flow through valve.";
CM_ SG_ 2633925118 EngnFlVlv1CmmnddPstn "Engine Fuel Valve 1 Commanded Position: The commanded position of the first fuel valve that is metering the fuel flow to the engine.";
CM_ SG_ 2633925118 EngnFlVlv2CmmnddPstn "Engine Fuel Valve 2 Commanded Position: The commanded position of the second fuel valve that is metering the fuel flow to the engine.";
CM_ BO_ 2633925374 "Ignition Timing 1";
CM_ SG_ 2633925374 EngineCylinder1IgnitionTiming "Engine Cylinder 1 Ignition Timing: The ignition timing (SI engines) or main fuel injection timing (CI engines) of the cylinder. Positive values indicate an increasingly advanced timing from TDC.";
CM_ SG_ 2633925374 EngineCylinder2IgnitionTiming "Engine Cylinder 2 Ignition Timing: The ignition timing (SI engines) or main fuel injection timing (CI engines) of the cylinder. Positive values indicate an increasingly advanced timing from TDC.";
CM_ SG_ 2633925374 EngineCylinder3IgnitionTiming "Engine Cylinder 3 Ignition Timing: The ignition timing (SI engines) or main fuel injection timing (CI engines) of the cylinder. Positive values indicate an increasingly advanced timing from TDC.";
CM_ SG_ 2633925374 EngineCylinder4IgnitionTiming "Engine Cylinder 4 Ignition Timing: The ignition timing (SI engines) or main fuel injection timing (CI engines) of the cylinder. Positive values indicate an increasingly advanced timing from TDC.";
CM_ BO_ 2633925630 "Ignition Timing 2";
CM_ SG_ 2633925630 EngineCylinder5IgnitionTiming "Engine Cylinder 5 Ignition Timing: The ignition timing (SI engines) or main fuel injection timing (CI engines) of the cylinder. Positive values indicate an increasingly advanced timing from TDC.";
CM_ SG_ 2633925630 EngineCylinder6IgnitionTiming "Engine Cylinder 6 Ignition Timing: The ignition timing (SI engines) or main fuel injection timing (CI engines) of the cylinder. Positive values indicate an increasingly advanced timing from TDC.";
CM_ SG_ 2633925630 EngineCylinder7IgnitionTiming "Engine Cylinder 7 Ignition Timing: The ignition timing (SI engines) or main fuel injection timing (CI engines) of the cylinder. Positive values indicate an increasingly advanced timing from TDC.";
CM_ SG_ 2633925630 EngineCylinder8IgnitionTiming "Engine Cylinder 8 Ignition Timing: The ignition timing (SI engines) or main fuel injection timing (CI engines) of the cylinder. Positive values indicate an increasingly advanced timing from TDC.";
CM_ BO_ 2633925886 "Ignition Timing 3";
CM_ SG_ 2633925886 EngineCylinder10IgnitionTiming "Engine Cylinder 10 Ignition Timing: The ignition timing (SI engines) or main fuel injection timing (CI engines) of the cylinder. Positive values indicate an increasingly advanced timing from TDC.";
CM_ SG_ 2633925886 EngineCylinder11IgnitionTiming "Engine Cylinder 11 Ignition Timing: The ignition timing (SI engines) or main fuel injection timing (CI engines) of the cylinder. Positive values indicate an increasingly advanced timing from TDC.";
CM_ SG_ 2633925886 EngineCylinder12IgnitionTiming "Engine Cylinder 12 Ignition Timing: The ignition timing (SI engines) or main fuel injection timing (CI engines) of the cylinder. Positive values indicate an increasingly advanced timing from TDC.";
CM_ SG_ 2633925886 EngineCylinder9IgnitionTiming "Engine Cylinder 9 Ignition Timing: The ignition timing (SI engines) or main fuel injection timing (CI engines) of the cylinder. Positive values indicate an increasingly advanced timing from TDC.";
CM_ BO_ 2633926142 "Ignition Timing 4";
CM_ SG_ 2633926142 EngineCylinder13IgnitionTiming "Engine Cylinder 13 Ignition Timing: The ignition timing (SI engines) or main fuel injection timing (CI engines) of the cylinder. Positive values indicate an increasingly advanced timing from TDC.";
CM_ SG_ 2633926142 EngineCylinder14IgnitionTiming "Engine Cylinder 14 Ignition Timing: The ignition timing (SI engines) or main fuel injection timing (CI engines) of the cylinder. Positive values indicate an increasingly advanced timing from TDC.";
CM_ SG_ 2633926142 EngineCylinder15IgnitionTiming "Engine Cylinder 15 Ignition Timing: The ignition timing (SI engines) or main fuel injection timing (CI engines) of the cylinder. Positive values indicate an increasingly advanced timing from TDC.";
CM_ SG_ 2633926142 EngineCylinder16IgnitionTiming "Engine Cylinder 16 Ignition Timing: The ignition timing (SI engines) or main fuel injection timing (CI engines) of the cylinder. Positive values indicate an increasingly advanced timing from TDC.";
CM_ BO_ 2633926398 "Ignition Timing 5";
CM_ SG_ 2633926398 EngineCylinder17IgnitionTiming "Engine Cylinder 17 Ignition Timing: The ignition timing (SI engines) or main fuel injection timing (CI engines) of the cylinder. Positive values indicate an increasingly advanced timing from TDC.";
CM_ SG_ 2633926398 EngineCylinder18IgnitionTiming "Engine Cylinder 18 Ignition Timing: The ignition timing (SI engines) or main fuel injection timing (CI engines) of the cylinder. Positive values indicate an increasingly advanced timing from TDC.";
CM_ SG_ 2633926398 EngineCylinder19IgnitionTiming "Engine Cylinder 19 Ignition Timing: The ignition timing (SI engines) or main fuel injection timing (CI engines) of the cylinder. Positive values indicate an increasingly advanced timing from TDC.";
CM_ SG_ 2633926398 EngineCylinder20IgnitionTiming "Engine Cylinder 20 Ignition Timing: The ignition timing (SI engines) or main fuel injection timing (CI engines) of the cylinder. Positive values indicate an increasingly advanced timing from TDC.";
CM_ BO_ 2633926654 "Ignition Timing 6";
CM_ SG_ 2633926654 EngineActualIgnitionTiming "Engine Actual Ignition Timing: The actual ignition timing at the current engine conditions. This parameter may or may not be equal to one of the desired timing parameters (see SPNs 1433-1435), depending on the status of the engine. Positive values in...";
CM_ SG_ 2633926654 EngineDesiredIgnitionTiming1 "Engine Desired Ignition Timing 1: A programmable timing value specific to the engine's application. Factors affecting this value include both fuel type and the nature of the load being driven. Positive values indicate an increasingly advanced timing ...";
CM_ SG_ 2633926654 EngineDesiredIgnitionTiming2 "Engine Desired Ignition Timing 2: A programmable timing value specific to the engine's application. Factors affecting this value include both fuel type and the nature of the load being driven. Positive values indicate an increasingly advanced timing ...";
CM_ SG_ 2633926654 EngineDesiredIgnitionTiming3 "Engine Desired Ignition Timing 3: A programmable timing value specific to the engine's application. Factors affecting this value include both fuel type and the nature of the load being driven. Positive values indicate an increasingly advanced timing ...";
CM_ BO_ 2633926910 "Ignition Transformer Secondary Output 1";
CM_ SG_ 2633926910 EngnClndr1IgntnTrnsfrmrSndrOtpt "Engine Cylinder 1 Ignition Transformer Secondary Output: This parameter indicates the relative intensity of the secondary output voltage of the ignition transformer.";
CM_ SG_ 2633926910 EngnClndr2IgntnTrnsfrmrSndrOtpt "Engine Cylinder 2 Ignition Transformer Secondary Output: This parameter indicates the relative intensity of the secondary output voltage of the ignition transformer.";
CM_ SG_ 2633926910 EngnClndr3IgntnTrnsfrmrSndrOtpt "Engine Cylinder 3 Ignition Transformer Secondary Output: This parameter indicates the relative intensity of the secondary output voltage of the ignition transformer.";
CM_ SG_ 2633926910 EngnClndr4IgntnTrnsfrmrSndrOtpt "Engine Cylinder 4 Ignition Transformer Secondary Output: This parameter indicates the relative intensity of the secondary output voltage of the ignition transformer.";
CM_ SG_ 2633926910 EngnClndr5IgntnTrnsfrmrSndrOtpt "Engine Cylinder 5 Ignition Transformer Secondary Output: This parameter indicates the relative intensity of the secondary output voltage of the ignition transformer.";
CM_ SG_ 2633926910 EngnClndr6IgntnTrnsfrmrSndrOtpt "Engine Cylinder 6 Ignition Transformer Secondary Output: This parameter indicates the relative intensity of the secondary output voltage of the ignition transformer.";
CM_ SG_ 2633926910 EngnClndr7IgntnTrnsfrmrSndrOtpt "Engine Cylinder 7 Ignition Transformer Secondary Output: This parameter indicates the relative intensity of the secondary output voltage of the ignition transformer.";
CM_ SG_ 2633926910 EngnClndr8IgntnTrnsfrmrSndrOtpt "Engine Cylinder 8 Ignition Transformer Secondary Output: This parameter indicates the relative intensity of the secondary output voltage of the ignition transformer.";
CM_ BO_ 2633927166 "Ignition Transformer Secondary Output 2";
CM_ SG_ 2633927166 ECd10ItTsSdOtpt "Engine Cylinder 10 Ignition Transformer Secondary Output: This parameter indicates the relative intensity of the secondary output voltage of the ignition transformer.";
CM_ SG_ 2633927166 ECd11ItTsSdOtpt "Engine Cylinder 11 Ignition Transformer Secondary Output: This parameter indicates the relative intensity of the secondary output voltage of the ignition transformer.";
CM_ SG_ 2633927166 ECd12ItTsSdOtpt "Engine Cylinder 12 Ignition Transformer Secondary Output: This parameter indicates the relative intensity of the secondary output voltage of the ignition transformer.";
CM_ SG_ 2633927166 ECd13ItTsSdOtpt "Engine Cylinder 13 Ignition Transformer Secondary Output: This parameter indicates the relative intensity of the secondary output voltage of the ignition transformer.";
CM_ SG_ 2633927166 ECd14ItTsSdOtpt "Engine Cylinder 14 Ignition Transformer Secondary Output: This parameter indicates the relative intensity of the secondary output voltage of the ignition transformer.";
CM_ SG_ 2633927166 ECd15ItTsSdOtpt "Engine Cylinder 15 Ignition Transformer Secondary Output: This parameter indicates the relative intensity of the secondary output voltage of the ignition transformer.";
CM_ SG_ 2633927166 ECd16ItTsSdOtpt "Engine Cylinder 16 Ignition Transformer Secondary Output: This parameter indicates the relative intensity of the secondary output voltage of the ignition transformer.";
CM_ SG_ 2633927166 EngnClndr9IgntnTrnsfrmrSndrOtpt "Engine Cylinder 9 Ignition Transformer Secondary Output: This parameter indicates the relative intensity of the secondary output voltage of the ignition transformer.";
CM_ BO_ 2633927422 "Ignition Transformer Secondary Output 3";
CM_ SG_ 2633927422 ECd17ItTsSdOtpt "Engine Cylinder 17 Ignition Transformer Secondary Output: This parameter indicates the relative intensity of the secondary output voltage of the ignition transformer.";
CM_ SG_ 2633927422 ECd18ItTsSdOtpt "Engine Cylinder 18 Ignition Transformer Secondary Output: This parameter indicates the relative intensity of the secondary output voltage of the ignition transformer.";
CM_ SG_ 2633927422 ECd19ItTsSdOtpt "Engine Cylinder 19 Ignition Transformer Secondary Output: This parameter indicates the relative intensity of the secondary output voltage of the ignition transformer.";
CM_ SG_ 2633927422 ECd20ItTsSdOtpt "Engine Cylinder 20 Ignition Transformer Secondary Output: This parameter indicates the relative intensity of the secondary output voltage of the ignition transformer.";
CM_ BO_ 2633927678 "Gaseous Fuel Pressure 1";
CM_ SG_ 2633927678 EngnArTFlDffrntlPrssr "Engine Air to Fuel Differential Pressure: The differential pressure between the gaseous fuel and the air intake manifold.";
CM_ SG_ 2633927678 EngnFlVlv1DffrntlPrssr "Engine Fuel Valve 1 Differential Pressure: The differential pressure between the intake and the outlet of the first or only gaseous fuel valve.See SPN 8494 for alternate range and resolution.";
CM_ SG_ 2633927678 EngnFlVlv1IntkAsltPrssr "Engine Fuel Valve 1 Intake Absolute Pressure: The absolute pressure of gas on the intake side of the first system control valve.  See SPN 3466 for Engine Fuel Valve 2, 7505 for Engine Fuel Valve 3 & 7506 for Engine Fuel Valve 4.";
CM_ SG_ 2633927678 EngnFlVlv1OtltAsltPrssr "Engine Fuel Valve 1 Outlet Absolute Pressure: Absolute Pressure of gas on outlet side of the first or only fuel system control valve.  See SPN 3469 for the second fuel control valve.";
CM_ BO_ 2633927934 "Auxiliary Analog Information";
CM_ SG_ 2633927934 AuxiliaryLevel "Auxiliary Level: Level measured by a sensor.";
CM_ SG_ 2633927934 AuxiliaryPressure1 "Auxiliary Pressure #1: Pressure measured by auxiliary pressure sensor #1.  Not to be used in place of existing SPs.";
CM_ SG_ 2633927934 AuxiliaryPressure2 "Auxiliary Pressure #2: Pressure measured by auxiliary pressure sensor #2.  Not to be used in place of existing SPs.";
CM_ SG_ 2633927934 AuxiliaryTemperature1 "Auxiliary Temperature 1: Temperature measured by auxiliary temperature sensor #1.  Not to be used in place of existing SPs.";
CM_ SG_ 2633927934 AuxiliaryTemperature2 "Auxiliary Temperature 2: Temperature measured by auxiliary temperature sensor #2.  Not to be used in place of existing SPs.";
CM_ SG_ 2633927934 RelativeHumidity "Relative Humidity: Measures humidity of combustion air prior to entry into turbocharger";
CM_ SG_ 2633927934 AuxiliaryTemperature3 "Auxiliary Temperature 3: Temperature measured by auxiliary temperature sensor 3. Not to be used in place of existing SPs.";
CM_ BO_ 2633928446 "Service 2";
CM_ SG_ 2633928446 ServiceComponentIdentification "Service Component Identification: Identification of component needing service.  See Table SPN911_A.";
CM_ SG_ 2633928446 TimeSinceLastService "Time Since Last Service: The vehicle operation time since the last service was performed.  The type of service information is identified by the service component identification number.";
CM_ BO_ 2633929214 "Fuel Leakage";
CM_ SG_ 2633929214 EngineFluidBundLevel "Engine Fluid Bund Level: Ratio of the volume of engine fluid within the bund containment frame to the maximum capacity of the bund containment frame. The bund containment frame is used to contain engine fluid leaks including, but not limited to, engi...";
CM_ SG_ 2633929214 EngineFuelLeakage1 "Engine Fuel Leakage 1: Status signal which indicates fuel leakage in the fuel rail of the engine. Location can be either before or after the fuel pump.  00b = no leakage detected01b = leakage detected10b = Error11b = Not available";
CM_ SG_ 2633929214 EngineFuelLeakage2 "Engine Fuel Leakage 2: Status signal which indicates fuel leakage in the fuel rail of the engine. Location can be either before or after the fuel pump.  00b = no leakage detected01b = leakage detected10b = Error11b = Not available";
CM_ BO_ 2633929470 "Engine Information 1";
CM_ SG_ 2633929470 EngineFuelRackPosition "Engine Fuel Rack Position: Measured position of the engine fuel rack.  A value of 0% rack represents no fueling and a value of 100% rack represents maximum fueling.";
CM_ SG_ 2633929470 EngineOilFilterIntakePressure "Engine Oil Filter Intake Pressure: Gage pressure of the engine oil before the oil reaches the oil filter.   See SPN 7470 for alternate resolution.";
CM_ SG_ 2633929470 EngnFlSstm1GsMssFlwRt "Engine Fuel System 1 Gas Mass Flow Rate: Gas mass flow rate delivered to an engine through its first fuel control system.  See SPN 3467 for the second fuel control system.";
CM_ SG_ 2633929470 InstntnsEstmtdBrkPwr "Instantaneous Estimated Brake Power: Estimate of the power developed by the engine.";
CM_ SG_ 2633929470 EngineExhaustBank1Pressure1 "Engine Exhaust Bank 1 Pressure 1: Gage pressure of the exhaust gases as measured at the turbine intake of the turbocharger. This SP to be used for inline engines or exhaust bank 1 of multiple bank engines.  See SPN 5749 for exhaust bank 2 and See SPN...";
CM_ BO_ 2633929726 "Engine Electrical System/Module Information";
CM_ SG_ 2633929726 ElectricalLoad "Electrical Load: Electrical power delivered by the engine to the electrical system connected to the generator.";
CM_ SG_ 2633929726 EngineTurningGearEngaged "Engine Turning Gear Engaged: Status signal which indicates that the turning gear is engaged.  The turning gear is used to turn the flywheel/crankshaft, for maintenance purposes, while the engine is not running.00b = Not engaged01b = Engaged10b = Erro...";
CM_ SG_ 2633929726 SafetyWireStatus "Safety Wire Status: Status signal which indicates that the safety wire has been activated.  When the safety wire is activated, the engine will not operate.  This is used for maintenance purposes.00b = Safety wire has not been activated01b = Safety wi...";
CM_ BO_ 2633930238 "Rebuild Information";
CM_ SG_ 2633930238 EngineOperationTimeSinceRebuild "Engine Operation Time Since Rebuild: The time in engine operation since the last engine rebuild.";
CM_ BO_ 2633931774 "Turbocharger Information 1";
CM_ SG_ 2633931774 EngineTurbocharger2Speed "Engine Turbocharger 2 Speed: Rotational velocity of rotor in the turbocharger.";
CM_ SG_ 2633931774 EngineTurbocharger3Speed "Engine Turbocharger 3 Speed: Rotational velocity of rotor in the turbocharger.";
CM_ SG_ 2633931774 EngineTurbocharger4Speed "Engine Turbocharger 4 Speed: Rotational velocity of rotor in the turbocharger.";
CM_ SG_ 2633931774 EngnTrhrgrLOlPrssr2 "Engine Turbocharger Lube Oil Pressure 2: Gage pressure of oil in turbocharger lubrication system.";
CM_ BO_ 2633932798 "Exhaust Port Temperature 5";
CM_ SG_ 2633932798 EngnExhstGsPrt17Tmprtr "Engine Exhaust Gas Port 17 Temperature: Temperature at the cylinder exhaust port of the engine.";
CM_ SG_ 2633932798 EngnExhstGsPrt18Tmprtr "Engine Exhaust Gas Port 18 Temperature: Temperature at the cylinder exhaust port of the engine.";
CM_ SG_ 2633932798 EngnExhstGsPrt19Tmprtr "Engine Exhaust Gas Port 19 Temperature: Temperature at the cylinder exhaust port of the engine.";
CM_ SG_ 2633932798 EngnExhstGsPrt20Tmprtr "Engine Exhaust Gas Port 20 Temperature: Temperature at the cylinder exhaust port of the engine.";
CM_ BO_ 2633933310 "Exhaust Port Temperature 3";
CM_ SG_ 2633933310 EngnExhstGsPrt10Tmprtr "Engine Exhaust Gas Port 10 Temperature: Temperature at the cylinder exhaust port of the engine.";
CM_ SG_ 2633933310 EngnExhstGsPrt11Tmprtr "Engine Exhaust Gas Port 11 Temperature: Temperature at the cylinder exhaust port of the engine.";
CM_ SG_ 2633933310 EngnExhstGsPrt12Tmprtr "Engine Exhaust Gas Port 12 Temperature: Temperature at the cylinder exhaust port of the engine.";
CM_ SG_ 2633933310 EngnExhstGsPrt9Tmprtr "Engine Exhaust Gas Port 9 Temperature: Temperature at the cylinder exhaust port of the engine.";
CM_ BO_ 2633933566 "Exhaust Port Temperature 2";
CM_ SG_ 2633933566 EngnExhstGsPrt5Tmprtr "Engine Exhaust Gas Port 5 Temperature: Temperature at the cylinder exhaust port of the engine.";
CM_ SG_ 2633933566 EngnExhstGsPrt6Tmprtr "Engine Exhaust Gas Port 6 Temperature: Temperature at the cylinder exhaust port of the engine.";
CM_ SG_ 2633933566 EngnExhstGsPrt7Tmprtr "Engine Exhaust Gas Port 7 Temperature: Temperature at the cylinder exhaust port of the engine.";
CM_ SG_ 2633933566 EngnExhstGsPrt8Tmprtr "Engine Exhaust Gas Port 8 Temperature: Temperature at the cylinder exhaust port of the engine.";
CM_ BO_ 2633933822 "Exhaust Port Temperature 1";
CM_ SG_ 2633933822 EngnExhstGsPrt1Tmprtr "Engine Exhaust Gas Port 1 Temperature: Temperature at the cylinder exhaust port of the engine.";
CM_ SG_ 2633933822 EngnExhstGsPrt2Tmprtr "Engine Exhaust Gas Port 2 Temperature: Temperature at the cylinder exhaust port of the engine.";
CM_ SG_ 2633933822 EngnExhstGsPrt3Tmprtr "Engine Exhaust Gas Port 3 Temperature: Temperature at the cylinder exhaust port of the engine.";
CM_ SG_ 2633933822 EngnExhstGsPrt4Tmprtr "Engine Exhaust Gas Port 4 Temperature: Temperature at the cylinder exhaust port of the engine.";
CM_ BO_ 2633934334 "Intake Manifold Information 2";
CM_ SG_ 2633934334 EngnIntkMnfld2Tmprtr "Engine Intake Manifold 2 Temperature: Temperature of pre-combustion air found in intake manifold of engine air supply system.";
CM_ SG_ 2633934334 EngnIntkMnfld3Tmprtr "Engine Intake Manifold 3 Temperature: Temperature of pre-combustion air found in intake manifold of engine air supply system.";
CM_ SG_ 2633934334 EngnIntkMnfld4Tmprtr "Engine Intake Manifold 4 Temperature: Temperature of pre-combustion air found in intake manifold of engine air supply system.";
CM_ SG_ 2633934334 EngnIntkMnfld5Tmprtr "Engine Intake Manifold 5 Temperature: Temperature of pre-combustion air found in intake manifold number 5 of engine air supply system.";
CM_ SG_ 2633934334 EngnIntkMnfld6Tmprtr "Engine Intake Manifold 6 Temperature: Temperature of pre-combustion air found in intake manifold  number 6 of engine air supply system.";
CM_ SG_ 2633934334 DsrdEngnIntkMnfldTmprtr "Desired Engine Intake Manifold Temperature: Indicates the desired temperature of pre-combustion air found in the intake manifold of the engine air supply system.";
CM_ SG_ 2633934334 DsrdEngnIntkMnfldTmprtrHghLmt "Desired Engine Intake Manifold Temperature High Limit: Indicates the desired upper temperature limit of the intake manifold of the engines air supply system.";
CM_ BO_ 2633934846 "Alternator Temperature 1";
CM_ SG_ 2633934846 EngnAltrntrBrng1Tmprtr "Engine Alternator Bearing 1 Temperature: Temperature of the bearing inside the alternator.  Bearing 1 is the left or rear bearing.";
CM_ SG_ 2633934846 EngnAltrntrBrng2Tmprtr "Engine Alternator Bearing 2 Temperature: Temperature of the bearing inside the alternator.  Bearing 2 is the right or front bearing.";
CM_ SG_ 2633934846 EngnAltrntrWndng1Tmprtr "Engine Alternator Winding 1 Temperature: Temperature of the windings inside the alternator.";
CM_ SG_ 2633934846 EngnAltrntrWndng2Tmprtr "Engine Alternator Winding 2 Temperature: Temperature of the windings inside the alternator.";
CM_ SG_ 2633934846 EngnAltrntrWndng3Tmprtr "Engine Alternator Winding 3 Temperature: Temperature of the windings inside the alternator.";
CM_ SG_ 2633934846 EngnAltrntrWndng4Tmprtr "Engine Alternator Winding 4 Temperature: Temperature of this winding inside the alternator.";
CM_ SG_ 2633934846 EngnAltrntrWndng5Tmprtr "Engine Alternator Winding 5 Temperature: Temperature of this winding inside the alternator.";
CM_ SG_ 2633934846 EngnAltrntrWndng6Tmprtr "Engine Alternator Winding 6 Temperature: Temperature of this winding inside the alternator.";
CM_ BO_ 2633935102 "Articulation Control";
CM_ SG_ 2633935102 ArticulationAngle "Articulation Angle: Angle of deflection of an articulated transit vehicle (rotation angle about the vehicles z-axis). A right turn (clockwise) is indicated with a positive angle and a left turn is indicated with a negative angle.  This parameter is d...";
CM_ SG_ 2633935102 ArticulationAngularVelocity "Articulation Angular Velocity: Angular velocity of deflection of an articulated transit vehicle (rotation angle about the vehicle's z-axis).  An increasing clockwise angle is indicated with a positive angular velocity and an increasing counterclockwi...";
CM_ BO_ 2633935358 "Exhaust Oxygen 1";
CM_ SG_ 2633935358 EngineActualExhaust1Oxygen "Engine Actual Exhaust 1 Oxygen: The actual amount of oxygen in the exhaust represented as a percentage by volume with respect to the total volume of exhaust gases leaving the engine.Note:  A value of FB00h shall be provided when ambient or engine ope...";
CM_ SG_ 2633935358 EngineDesiredExhaustOxygen "Engine Desired Exhaust Oxygen: The desired amount of oxygen in the exhaust represented as a percentage by volume with respect to the total volume of exhaust gases leaving the engine.";
CM_ SG_ 2633935358 EngineDesiredRatedExhaustOxygen "Engine Desired Rated Exhaust Oxygen: The desired amount of oxygen in the exhaust at rated conditions represented as a percentage by volume with respect to the total volume of exhaust gases leaving the engine.";
CM_ SG_ 2633935358 EngnExhstO2SnsrClsdLpOprtn "Engine Exhaust O2 Sensor Closed Loop Operation: Indicates whether the engine is using the exhaust oxygen sensor to control the air/fuel ratio.00b = Engine not using the exhaust oxygen sensor (open loop)01b = Engine using the exhaust oxygen sensor for...";
CM_ SG_ 2633935358 EngnExhstO2SnsrFlngCrrtn "Engine Exhaust O2 Sensor Fueling Correction: The amount of fueling change required by the system based on the measured exhaust oxygen value compared to the maximum fueling change permitted by the system, expressed as percentages.";
CM_ BO_ 2633935614 "Alternate Fuel 2";
CM_ SG_ 2633935614 EFSstGsMssFwRtSsFCt "Engine Fuel System Gas Mass Flow Rate Sensor Fueling Correction: The amount of fuel the Gas Mass Flow Rate Sensor is sensing should be added or subtracted compared to the maximum amount of fuel the control system allows the sensor to add or subtract.";
CM_ SG_ 2633935614 EngnIntkMnfldDsrdAsltPrssr "Engine Intake Manifold Desired Absolute Pressure: The desired absolute intake manifold pressure (turbo boost limit) of the engine.";
CM_ SG_ 2633935614 EngnTrhrgrWstgtVlvPstn "Engine Turbocharger Wastegate Valve Position: The position of the turbocharger wastegate valve (not the electronic wastegate control valve).";
CM_ SG_ 2633935614 GaseousFuelCorrectionFactor "Gaseous Fuel Correction Factor: A correction to a predefined gaseous fuel energy (expressed in energy per unit volume) represented as a percentage.  The actual fuel energy used to control the engine is the product of the gaseous fuel correction facto...";
CM_ SG_ 2633935614 GssFlInjtnPlsCrrtnFtr "Gaseous Fuel Injection Pulse Correction Factor: A correction to the gaseous fuel injection pulse (expressed in msec) represented as a percentage.  100% means no correction, higher values indicate increased pulse time, lower values indicate decreased ...";
CM_ BO_ 2633935870 "Electronic Transmission Controller 6";
CM_ SG_ 2633935870 ClutchLifeRemaining "Clutch Life Remaining: Signal which indicates the actual clutch life remaining in percent. One hundred percent means the clutch is brand new and zero percent means the clutch is at the end of its life.";
CM_ SG_ 2633935870 HighestPossibleGear "Highest Possible Gear: The transmission calculates this gear continuously.  Together with the lowest possible gear (see  SPN 1114), it enables a management computer to know the exact range of available gears.Negative values are reverse gears, positiv...";
CM_ SG_ 2633935870 LowestPossibleGear "Lowest Possible Gear: The transmission calculates this gear continuously.  Together with the highest possible gear (see SPN 1115), it enables a management computer to know the exact range of available gears.Negative values are reverse gears, positive...";
CM_ SG_ 2633935870 RecommendedGear "Recommended Gear: The transmission calculates this gear continuously.  In dangerous situations this gear may be selected to gain back vehicle control.Negative values are reverse gears, positive values are forward gears, zero is neutral, 251 (FBh) is ...";
CM_ BO_ 2633936126 "Wheel Brake Lining Remaining Information 1";
CM_ SG_ 2633936126 BrkLnngRmnngFrntAxlLftWhl "Brake Lining Remaining, Front Axle, Left Wheel: The percentage of brake lining which can still be measured for the left wheel on the front axle.  100% represents new brake linings, 0% represents totally worn brake linings.";
CM_ SG_ 2633936126 BrkLnngRmnngFrntAxlRghtWhl "Brake Lining Remaining, Front Axle, Right Wheel: The percentage of brake lining which can still be measured for the right wheel on the front axle.  100% represents new brake linings, 0% represents totally worn brake linings.";
CM_ SG_ 2633936126 BrkLnngRmnngRrAxl1LftWhl "Brake Lining Remaining, Rear Axle #1, Left Wheel: The percentage of brake lining which can still be measured for the left wheel on the rear axle #1.  100% represents new brake linings, 0% represents totally worn brake linings.";
CM_ SG_ 2633936126 BrkLnngRmnngRrAxl1RghtWhl "Brake Lining Remaining, Rear Axle #1, Right Wheel: The percentage of brake lining which can still be measured for the right wheel on the rear axle #1.  100% represents new brake linings, 0% represents totally worn brake linings.";
CM_ SG_ 2633936126 BrkLnngRmnngRrAxl2LftWhl "Brake Lining Remaining, Rear Axle #2, Left Wheel: The percentage of brake lining which can still be measured for the left wheel on the rear axle #2.  100% represents new brake linings, 0% represents totally worn brake linings.";
CM_ SG_ 2633936126 BrkLnngRmnngRrAxl2RghtWhl "Brake Lining Remaining, Rear Axle #2, Right Wheel: The percentage of brake lining which can still be measured for the right wheel on the rear axle #2.  100% represents new brake linings, 0% represents totally worn brake linings.";
CM_ SG_ 2633936126 BrkLnngRmnngRrAxl3LftWhl "Brake Lining Remaining, Rear Axle #3, Left Wheel: The percentage of brake lining which can still be measured for the left wheel on the rear axle #3.  100% represents new brake linings, 0% represents totally worn brake linings.";
CM_ SG_ 2633936126 BrkLnngRmnngRrAxl3RghtWhl "Brake Lining Remaining, Rear Axle #3, Right Wheel: The percentage of brake lining which can still be measured for the right wheel on the rear axle #3.  100% represents new brake linings, 0% represents totally worn brake linings.";
CM_ BO_ 2633936894 "Fuel Consumption (Gaseous)";
CM_ SG_ 2633936894 TotalFuelUsedGaseous "Total Fuel Used (Gaseous): Total fuel consumed (trip drive fuel + trip PTO governor moving fuel + trip PTO governor non-moving fuel + trip idle fuel) over the life of the engine.";
CM_ SG_ 2633936894 TripFuelGaseous "Trip Fuel (Gaseous): Total fuel consumed (trip drive fuel + trip PTO governor moving fuel + trip PTO governor non-moving fuel + trip idle fuel) since the last trip reset.";
CM_ BO_ 2633937150 "Trip Time Information 2";
CM_ SG_ 2633937150 TripAirCompressorOnTime "Trip Air Compressor On Time: Total time that the air compressor is on and compressing air since the last trip reset.";
CM_ SG_ 2633937150 TripCruiseTime "Trip Cruise Time: Total time accumulated while the engine is in the cruise hold state, excluding time in accelerator override, since the last trip reset.";
CM_ SG_ 2633937150 TripEngineRunningTime "Trip Engine Running Time: Total time accumulated while the engine speed is greater than zero since the last trip reset.  Note that time with the ignition switch on but engine speed at zero is not included.";
CM_ SG_ 2633937150 TripIdleTime "Trip Idle Time: Total time accumulated while the engine speed is greater than zero, both the PTO and remote PTO governors are inactive, and the vehicle speed is less than 2 km/h, since the last trip reset.In marine applications, this parameter is def...";
CM_ SG_ 2633937150 TripPtoGovernorTime "Trip PTO Governor Time: Total time accumulated while the engine is in the PTO or remote PTO governor hold state since the last trip reset.";
CM_ BO_ 2633937406 "ECU History";
CM_ SG_ 2633937406 TotalEcuDistance "Total ECU Distance: Total distance accumulated over the life of the ECU.  When the ECU is replaced this value shall be reset.";
CM_ SG_ 2633937406 TotalEcuRunTime "Total ECU Run Time: Total time accumulated over the life of the ECU, from ignition switch ON to ignition switch OFF.  When the ECU is replaced this value shall be reset.";
CM_ BO_ 2633937662 "Fuel Information 1 (Gaseous)";
CM_ SG_ 2633937662 EngineFuelSpecificGravity "Engine Fuel Specific Gravity: This parameter conveys the specific gravity of the gaseous fuel being used by the engine.  The specific gravity of the fuel can then be used to compute the density of the fuel.";
CM_ SG_ 2633937662 TripAverageFuelRateGaseous "Trip Average Fuel Rate (Gaseous): Average fuel rate, equal to trip fuel divided by trip time while the engine speed is above zero, since the last trip reset.  This includes idle, engine PTO governor (both moving and non-moving) and drive operation bu...";
CM_ SG_ 2633937662 TtlEngnPtGvrnrFlUsdGss "Total Engine PTO Governor Fuel Used (Gaseous): Total fuel used while the PTO or remote PTO governors are in the hold state and engine speed is above zero, over the life of the engine.NOTE-This parameter is intended for gaseous fueled engines.  See SP...";
CM_ BO_ 2633937918 "Fuel Information 1 (Liquid)";
CM_ SG_ 2633937918 FlexibleFuelPercentage "Flexible Fuel Percentage: Measured signal that indicates the percentage of alcohol in the fuel currently being used.  0% means no alcohol in fuel, 100% means alcohol as fuel and nothing else.EXAMPLE: If a Bi-fuel vehicle has less than 10% ethanol in ...";
CM_ SG_ 2633937918 TotalEnginePtoGovernorFuelUsed "Total Engine PTO Governor Fuel Used: Total fuel used while the PTO or remote PTO governors are in the hold state and engine speed is above zero, over the life of the engine.NOTE-This parameter is intended for liquid fueled engines.  See SPN 1030 for ...";
CM_ SG_ 2633937918 TripAverageFuelRate "Trip Average Fuel Rate: Average fuel rate, equal to trip fuel divided by trip time while the engine speed is above zero, since the last trip reset.  This includes idle, engine PTO governor (both moving and non-moving) and drive operation but excludes...";
CM_ BO_ 2633938174 "Trip Time Information 1";
CM_ SG_ 2633938174 TripTimeInDerateByEngine "Trip Time in Derate by Engine: Total time accumulated when the engine final fueling has been derated due to an engine protection algorithm, since the last reset.";
CM_ SG_ 2633938174 TripTimeInGearDown "Trip Time in Gear Down: Total time accumulated when the vehicle has operated in one gear down from the top gear for a calibrated minimum time, since the last trip reset.";
CM_ SG_ 2633938174 TripTimeInTopGear "Trip Time in Top Gear: Total time accumulated when the vehicle has operated in top gear for a calibrated minimum time, since the last trip reset.";
CM_ SG_ 2633938174 TripTimeInVsl "Trip Time in VSL: Total time accumulated when the engine has operated on the vehicle speed limiter (VSL) while not in the cruise hold state, since the last trip reset.  The engine torque mode is equal to road speed governor during this operation.";
CM_ BO_ 2633938430 "Trip Shutdown Information";
CM_ SG_ 2633938430 TripNumberOfHotShutdowns "Trip Number of Hot Shutdowns: Total number of hot shutdowns since the last trip reset.  A hot shutdown is based on operation at high load or high engine speed or for long operating periods without allowing the engine to cool sufficiently.";
CM_ SG_ 2633938430 TripNumberOfIdleShutdowns "Trip Number of Idle Shutdowns: Total number of times the engine has been shutdown due to idling too long (at normal idle or fast idle) since the last trip reset.";
CM_ SG_ 2633938430 TripSuddenDecelerations "Trip Sudden Decelerations: Total number of decelerations whenever the vehicle deceleration is more than XYZ km/h/sec (where XYZ is a calibratible threshold), since the last trip reset.  A lengthy deceleration shall be counted as one sudden decelerati...";
CM_ SG_ 2633938430 TrpNmrOfIdlShtdwnOvrrds "Trip Number of Idle Shutdown Overrides: Total number of times an operator disables idle shutdown to prevent an engine shutdown, since the last trip reset.";
CM_ BO_ 2633938686 "Trip Vehicle Speed/Cruise Distance Information";
CM_ SG_ 2633938686 TripCruiseDistance "Trip Cruise Distance: Total distance that the engine has operated in the cruise hold state, excluding time in accelerator override, since the last trip reset.";
CM_ SG_ 2633938686 TripMaximumVehicleSpeed "Trip Maximum Vehicle Speed: Maximum vehicle speed achieved while the engine speed is greater than zero and the accelerator pedal position (APS) is at a value greater than 0%, since the last trip reset.";
CM_ BO_ 2633938942 "Engine Speed/Load Factor Information 1";
CM_ SG_ 2633938942 TotalEngineCruiseTime "Total Engine Cruise Time: Total time that the engine has operated in the cruise hold state, excluding time in accelerator override, over the life of the engine.";
CM_ SG_ 2633938942 TripAverageEngineSpeed "Trip Average Engine Speed: Average speed of the engine since the last trip reset.NOTE - Excludes ignition-on time without the engine speed above zero.  Includes idle, engine PTO governor (moving and non-moving), and drive operation.";
CM_ SG_ 2633938942 TripMaximumEngineSpeed "Trip Maximum Engine Speed: Maximum engine speed achieved since the last trip reset.";
CM_ SG_ 2633938942 TripDriveAverageLoadFactor "Trip Drive Average Load Factor: Average engine load factor while engine speed is greater than zero, vehicle speed is greater than or equal to 2 km/h, and both the PTO (moving/non-moving) and remote PTO governors are not in the hold state, since the l...";
CM_ SG_ 2633938942 TotalDriveAverageLoadFactor "Total Drive Average Load Factor: Average engine load factor while engine speed is greater than zero, vehicle speed is greater than or equal to 2 km/h, and both the PTO (moving/non-moving) and remote PTO governors are not in the hold state, over the l...";
CM_ BO_ 2633939198 "Trip Fuel Information (Gaseous)";
CM_ SG_ 2633939198 TripCruiseFuelUsedGaseous "Trip Cruise Fuel Used (Gaseous): Total fuel consumed while the engine is in the cruise hold state since the last trip reset.  If both cruise control and VSL (vehicle speed limiter) are commanding the same amount of fuel, the cruise control is deemed ...";
CM_ SG_ 2633939198 TripDriveFuelEconomyGaseous "Trip Drive Fuel Economy (Gaseous): Trip drive fuel economy is equal to the distance traveled by vehicle in the drive state (engine speed greater than zero, vehicle speed greater than or equal to 2 km/h, and neither the PTO or remote PTO governors are...";
CM_ SG_ 2633939198 TripDriveFuelUsedGaseous "Trip Drive Fuel Used (Gaseous): Total fuel consumed while the engine speed is greater than zero, vehicle speed is greater than or equal to 2 km/h, and neither the PTO or the remote PTO governors are controlling the engine power output, since the last...";
CM_ SG_ 2633939198 TripVehicleIdleFuelUsedGaseous "Trip Vehicle Idle Fuel Used (Gaseous): Total fuel consumed while neither the PTO or remote PTO governors are active, the engine speed is greater than zero, and vehicle speed is less than to 2 km/h, since the last trip reset.NOTE-This parameter is int...";
CM_ SG_ 2633939198 TrpPtGvrnrMvngFlUsdGss "Trip PTO Governor Moving Fuel Used (Gaseous): Total fuel consumed while the PTO or remote PTO governors are in the hold state, the engine speed is greater than zero, and vehicle speed is greater than or equal to 2 km/h, since the last trip reset.NOTE...";
CM_ SG_ 2633939198 TrpPtGvrnrNnMvngFlUsdGss "Trip PTO Governor Non-moving Fuel Used (Gaseous): Total fuel consumed while the PTO or remote PTO governors are in the hold state, the engine speed is greater than zero, and vehicle speed is less than to 2 km/h, since the last trip reset.NOTE-This pa...";
CM_ BO_ 2633939454 "Trip Fuel Information (Liquid)";
CM_ SG_ 2633939454 TripCruiseFuelUsed "Trip Cruise Fuel Used: Total fuel consumed while the engine is in the cruise hold state since the last trip reset.  If both cruise control and VSL (vehicle speed limiter) are commanding the same amount of fuel, the cruise control is deemed the active...";
CM_ SG_ 2633939454 TripDriveFuelEconomy "Trip Drive Fuel Economy: Trip drive fuel economy is equal to the distance traveled by vehicle in the drive state (engine speed greater than zero, vehicle speed greater than or equal to 2 km/h, and neither the PTO or remote PTO governors are controlli...";
CM_ SG_ 2633939454 TripDriveFuelUsed "Trip Drive Fuel Used: Total fuel consumed while the engine speed is greater than zero, vehicle speed is greater than or equal to 2 km/h, and neither the PTO or the remote PTO is controlling the engine power output, since the last trip reset.NOTE-This...";
CM_ SG_ 2633939454 TripPtoGovernorMovingFuelUsed "Trip PTO Governor Moving Fuel Used: Total fuel consumed while either the PTO or remote PTO governors are in the hold state, the engine speed is greater than zero, and vehicle speed is greater than or equal to 2 km/h, since the last trip reset.NOTE-Th...";
CM_ SG_ 2633939454 TripVehicleIdleFuelUsed "Trip Vehicle Idle Fuel Used: Total fuel consumed while neither the PTO or remote PTO governor is in the hold state, the engine speed is greater than zero, and vehicle speed is less than 2 km/h, since the last trip reset.In marine applications, this p...";
CM_ SG_ 2633939454 TrpPtGvrnrNnMvngFlUsd "Trip PTO Governor Non-moving Fuel Used: Total fuel consumed while either the PTO or remote PTO governors are in the hold state, the engine speed is greater than zero, and vehicle speed is less than 2 km/h, since the last trip reset.NOTE-This paramete...";
CM_ BO_ 2633939710 "Trip Distance Information";
CM_ SG_ 2633939710 TripDistanceInTopGear "Trip Distance in Top Gear: Total distance accumulated while the vehicle has operated in top gear for a calibrated minimum time since the last trip reset.";
CM_ SG_ 2633939710 TripDistanceOnVsl "Trip Distance on VSL: Total distance accumulated while the engine torque mode is road speed governing since the last trip reset.";
CM_ SG_ 2633939710 TripGearDownDistance "Trip Gear Down Distance: Total distance accumulated while the vehicle has operated in the gear which is one gear down from top gear and exceeds a calibrated minimum time (typically the time to shift the transmission) since the last trip reset.";
CM_ BO_ 2633939966 "Trip Fan Information";
CM_ SG_ 2633939966 TripFanOnTime "Trip Fan On Time: Total time the fan has been on (due to an automatic trigger or manual trigger) since the last trip reset.  The fan could be requested to be on by the engine system, a manual switch, and/or the A/C system.  Whichever system requests ...";
CM_ SG_ 2633939966 TripFanOnTimeDueToAManualSwitch "Trip Fan On Time Due to a Manual Switch: Total time the fan has been on due to manual activation by the operator (i.e., excluding time on due to automatic triggers) since the last trip reset.  For the time to be accumulated against the manual switch,...";
CM_ SG_ 2633939966 TripFanOnTimeDueToTheACSystem "Trip Fan On Time Due to the A/C System: Total time the fan has been on due to the A/C system since the last trip reset.  For the time to be accumulated against the A/C system, it is necessary that it be the first to request the fan activation or it b...";
CM_ SG_ 2633939966 TrpFnOnTmDTThEngnSstm "Trip Fan On Time Due to the Engine System: Total time the fan has been on due to engine triggers (i.e., excluding time on due to an operator manual switch or A/C system) since the last trip reset.  For the time to be accumulated against the engine sy...";
CM_ BO_ 2633940222 "Compression/Service Brake Information";
CM_ SG_ 2633940222 TotalCompressionBrakeDistance "Total Compression Brake Distance: Total distance over which the compression brakes have been active for the life of the engine.";
CM_ SG_ 2633940222 TripCompressionBrakeDistance "Trip Compression Brake Distance: Total distance over which the compression brakes have been active since the last trip reset.";
CM_ SG_ 2633940222 TripServiceBrakeApplications "Trip Service Brake Applications: Total number of times the service brakes have been activated since the last trip reset.  Brake applications of less than 0.5 s are not counted and lengthy brake applications (longer than 0.5 s) are counted as a single...";
CM_ SG_ 2633940222 TripServiceBrakeDistance "Trip Service Brake Distance: Total distance over which the service brakes have been active since the last trip reset.";
CM_ BO_ 2633940734 "Electronic Engine Controller 4";
CM_ SG_ 2633940734 EngineRatedPower "Engine Rated Power: Net brake power that the engine will deliver continuously, specified for a given application at a rated speed.";
CM_ SG_ 2633940734 EngineRatedSpeed "Engine Rated Speed: The maximum governed rotational velocity of the engine crankshaft under full load conditions.  Note that the engine speed at point 2 (SPN 528) is equal to rated engine speed only in the case when the engine has not been derated.  ...";
CM_ SG_ 2633940734 EngineRotationDirection "Engine Rotation Direction: Direction of engine rotation, as reported by the engine.  Direction convention as viewed by an observer standing at the rear of the engine, viewing the flywheel.00b = CounterClockWise (CCW)01b = ClockWise (CW)10b = Unknown ...";
CM_ SG_ 2633940734 EngnIntkMnfldPrssrCntrlMd "Engine Intake Manifold Pressure Control Mode: Indicates that the Boost Pressure Closed Loop Control status either open loop or closed loop.00b = Open loop 01b = Closed loop 10b = SAE reserved11b = Not available";
CM_ SG_ 2633940734 EngnPrlOlLwPrssrThrshld "Engine Prelube Oil Low Pressure Threshold: The minimum value that the engine oil pressure (SPN 100 and SPN 7468) must exceed in order to start the engine.This parameter is intended for applications that have an external means of lubricating the engin...";
CM_ SG_ 2633940734 CrnkAttmptCntOnPrsntStrtAttmpt "Crank Attempt Count on Present Start Attempt: Reports the number of cranking cycles undergone during the present start attempt.Note:  This is intended to be used in conjunction with Maximum Crank Attempts per Start Attempt, in order to give a FMI 0 d...";
CM_ BO_ 2633941758 "Electronic Retarder Controller 2";
CM_ SG_ 2633941758 CrsCntrlRtrdrAtvSpdOffst "Cruise Control Retarder Active Speed Offset: The additional speed (offset) above the operator selected cruise control set speed (SPN 6809 or SPN 86) at which the retarder will activate when cruise control is active. It is not an offset from SPN 7319 ...";
CM_ SG_ 2633941758 TransmissionOutputRetarder "Transmission Output Retarder: Identifies the status of the transmission output retarder.00b = Off01b = On10b = Error11b = Not available";
CM_ SG_ 2633941758 RetarderRoadSpeedLimitEnable "Retarder Road Speed Limit Enable: This indicates that the system is capable of activating the retarder to limit the downhill vehicle speed which is possible when SPN 4233 is ON and the operator has set a downhill vehicle speed.00b = Retarder Road Spe...";
CM_ SG_ 2633941758 RetarderRoadSpeedLimitActive "Retarder Road Speed Limit Active: This indicates the retarder road speed limit system is actively engaged and retarder is limiting the downhill vehicle speed. This parameter can also be used as feedback indication for conventional cruise control syst...";
CM_ SG_ 2633941758 TrnsmssnRtrdrEnlSwth "Transmission Retarder Enable Switch: The transmission retarder enable switch indicates whether the operator allows the transmission to engage its integral retarder when indicated by vehicle operating conditions.00b = Retarder Enable Switch Off01b = R...";
CM_ SG_ 2633941758 RetarderRoadSpeedLimitSetSpeed "Retarder Road Speed Limit Set Speed: Value of set (chosen) velocity of the retarder road speed limit system.";
CM_ SG_ 2633941758 RetarderRoadSpeedLimitReadiness "Retarder Road Speed Limit Readiness: This indicates that the system is capable of activating the retarder to limit the downhill vehicle speed. This parameter will be set to 01b when the system is capable of activating the retarder to limit the downhi...";
CM_ BO_ 2633942014 "Electronic Transmission Controller 5";
CM_ SG_ 2633942014 TransmissionLowRangeSenseSwitch "Transmission Low Range Sense Switch: Identifies the status of the switch that represents low range.00b = Off01b = On10b = Error11b = Not available";
CM_ SG_ 2633942014 TransmissionNeutralSwitch "Transmission Neutral Switch: Identifies the status of the switch that indicates neutral.00b = Off01b = On10b = Error11b = Not available";
CM_ SG_ 2633942014 TrnsmssnFrwrdDrtnSwth "Transmission Forward Direction Switch: Identifies the status of the switch that indicates forward direction.00b = Off01b = On10b = Error11b = Not available";
CM_ SG_ 2633942014 TrnsmssnHghRngSnsSwth "Transmission High Range Sense Switch: Identifies the status of the switch that represents high range.00b = Off01b = On10b = Error11b = Not available";
CM_ SG_ 2633942014 TrnsmssnRvrsDrtnSwth "Transmission Reverse Direction Switch: Identifies the status of the switch that indicates reverse direction.00b = Off01b = On10b = Error11b = Not available";
CM_ SG_ 2633942014 TransmissionSplitterPosition "Transmission Splitter Position: The current position of the splitter cylinder.00b = Off/Low01b = On/High10b = Error11b = Not Available";
CM_ BO_ 2633942526 "Electronic Transmission Controller 4";
CM_ SG_ 2633942526 TrnsmssnSnhrnzrBrkVl "Transmission Synchronizer Brake Value: The current modulated value for the air supply to the synchronizer brake.";
CM_ SG_ 2633942526 TrnsmssnSnhrnzrClthVl "Transmission Synchronizer Clutch Value: The current modulated value for the air supply to the synchronizer clutch.";
CM_ BO_ 2633943038 "Electronic Transmission Controller 3";
CM_ SG_ 2633943038 TransmissionClutchActuator "Transmission Clutch Actuator: Identifies the status of the actuator that controls the clutch.00b = Off01b = On10b = Error11b = Not available";
CM_ SG_ 2633943038 TransmissionDefuelActuator "Transmission Defuel Actuator: Identifies the status of the actuator that controls the engine defuel mechanism.00b = Off01b = On10b = Error11b = Not available";
CM_ SG_ 2633943038 TransmissionRangeHighActuator "Transmission Range High Actuator: Identifies the status of the range high actuator in the auxiliary unit.00b = Off01b = On10b = Error11b = Not available";
CM_ SG_ 2633943038 TransmissionRangeLowActuator "Transmission Range Low Actuator: Identifies the status of the range low actuator in the auxiliary unit.00b = Off01b = On10b = Error11b = Not available";
CM_ SG_ 2633943038 TrnsmssnInrtBrkAttr "Transmission Inertia Brake Actuator: Identifies the status of the actuator that controls the inertia brake.00b = Off01b = On10b = Error11b = Not available";
CM_ SG_ 2633943038 TrnsmssnShftFngrCntrRlIndtr "Transmission Shift Finger Center Rail Indicator: Identifies the status of the shift finger in the center rail position.00b = Off01b = On10b = Error11b = Not available";
CM_ SG_ 2633943038 TrnsmssnShftFngrEnggmntIndtr "Transmission Shift Finger Engagement Indicator: Identifies the status of the shift finger in the engagement position.00b = Off01b = On10b = Error11b = Not available";
CM_ SG_ 2633943038 TrnsmssnShftFngrGrAttr1 "Transmission Shift Finger Gear Actuator 1: Identifies the status of the actuator that moves the shift finger identified as gear actuator #1.00b = Off01b = On10b = Error11b = Not available";
CM_ SG_ 2633943038 TrnsmssnShftFngrGrAttr2 "Transmission Shift Finger Gear Actuator 2: Identifies the status of the actuator that moves the shift finger identified as gear actuator #2.00b = Off01b = On10b = Error11b = Not available";
CM_ SG_ 2633943038 TrnsmssnShftFngrGrPstn "Transmission Shift Finger Gear Position: The current position of the shift finger in the gear direction.";
CM_ SG_ 2633943038 TrnsmssnShftFngrNtrlIndtr "Transmission Shift Finger Neutral Indicator: Indicates the status of the shift finger in the neutral position.00b = Off01b = On10b = Error11b = Not available";
CM_ SG_ 2633943038 TrnsmssnShftFngrRlAttr1 "Transmission Shift Finger Rail Actuator 1: Identifies the status of the actuator that moves the shift finger identified as rail actuator #1.00b = Off01b = On10b = Error11b = Not available";
CM_ SG_ 2633943038 TrnsmssnShftFngrRlAttr2 "Transmission Shift Finger Rail Actuator 2: Identifies the status of the actuator that moves the shift finger identified as rail actuator #2.00b = Off01b = On10b = Error11b = Not available";
CM_ SG_ 2633943038 TrnsmssnShftFngrRlPstn "Transmission Shift Finger Rail Position: The current position of the shift finger in the rail direction.";
CM_ SG_ 2633943038 TrnsmssnSplttrDrtAttr "Transmission Splitter Direct Actuator: Identifies the status of the splitter direct actuator in the auxiliary unit.00b = Off01b = On10b = Error11b = Not available";
CM_ SG_ 2633943038 TrnsmssnSplttrIndrtAttr "Transmission Splitter Indirect Actuator: Identifies the status of the splitter indirect actuator in the auxiliary unit.00b = Off01b = On10b = Error11b = Not available";
CM_ SG_ 2633943038 TrnsmssnTrqCnvrtrLkpClthAttr "Transmission Torque Converter Lockup Clutch Actuator: Identifies the status of the actuator that controls the torque converter lockup clutch.00b = Off01b = On10b = Error11b = Not available";
CM_ BO_ 2565865726 "Electronic Retarder Controller 1";
CM_ SG_ 2565865726 ActualRetarderPercentTorque "Actual Retarder - Percent Torque: Actual braking torque of the retarder as a percent of retarder configuration reference torque SPN 556.Note:  Refer to section 5.2.1 in SAE J1939-71.";
CM_ SG_ 2565865726 AtlMxmmAvllRtrdrPrntTrq "Actual Maximum Available Retarder - Percent Torque: This is the maximum amount of torque that the retarder can immediately deliver.   It is the same as the maximum torque shown in the Retarder's Configuration message, but allows for a much faster rat...";
CM_ SG_ 2565865726 DrvrsDmndRtrdrPrntTrq "Drivers Demand Retarder -  Percent Torque: The Drivers demand retarder - percent torque is the maximum torque selected by the driver when one or more modes  are selected by the driver, such as hand lever, switch, constant torque, constant velocity, e...";
CM_ SG_ 2565865726 EngineCoolantLoadIncrease "Engine Coolant Load Increase: Status of an event, external to the engine, that may increase the nominal temperature of the engine coolant liquid.00b = No coolant load increase01b = Coolant load increase possible10b = Error11b = Not available...";
CM_ SG_ 2565865726 IntendedRetarderPercentTorque "Intended Retarder Percent Torque: Braking torque of retarder that the retarder is currently trying to achieve.  This value takes into account all static limitations, but not the limitations due to the dynamic behavior of the retarder.  This value, if...";
CM_ SG_ 2565865726 RetarderEnableBrakeAssistSwitch "Retarder Enable - Brake Assist Switch: Switch signal which indicates whether the operator wishes the retarder to be enabled for vehicle braking assist. The retarder does not check this switch, nor does the enabling of this switch engage the retarder....";
CM_ SG_ 2565865726 RetarderEnableShiftAssistSwitch "Retarder Enable - Shift Assist Switch: Switch signal which indicates whether the operator wishes the retarder to be enabled for transmission shift assist.  The retarder does not check this switch, nor does the enabling of this switch engage the retar...";
CM_ SG_ 2565865726 RetarderRequestingBrakeLight "Retarder Requesting Brake Light: Indicates that whether the retarder is requesting that the brake lights are illuminated.00b = Retarder is not requesting that the brake lights are illuminated01b = Retarder is requesting that the brake lights are illu...";
CM_ SG_ 2565865726 RetarderRoadSpeedExceededStatus "Retarder Road Speed Exceeded Status: Retarder Road Speed Exceeded Status:00b = Road speed is below threshold 01b = Road speed is above threshold and retarder is allowed to be activated10b = Reserved11b = Don't care/Take no action";
CM_ SG_ 2565865726 RetarderRoadSpeedLimitSwitch "Retarder Road Speed Limit Switch: Retarder road speed limit switch states:00b = Road speed limiting by retarder is disabled01b = Road speed limiting by retarder is enabled. When the speed limit is not set by a network device, the road speed that the ...";
CM_ SG_ 2565865726 RetarderSelectionNonEngine "Retarder Selection, non-engine: The 'Retarder Selection, non-engine' is the position of the driver's selector for retarders that are not part of the engine system, expressed as percent and determined by the ratio of current position to the maximum po...";
CM_ SG_ 2565865726 RetarderTorqueMode "Retarder Torque Mode: State signal which indicates which retarder torque mode is currently generating, limiting, or controlling the torque.  Note that the modes are not in prioritized order. Not all modes may be relevant for a given device.  Some dev...";
CM_ SG_ 2565865726 SAddssOCtDvFRtdCt "Source Address of Controlling Device for Retarder Control: The source address of the SAE J1939 device currently controlling the retarder.  It is used to expand the torque mode parameter (see SPN 899) in cases where control is in response to an ECU th...";
CM_ BO_ 2499608830 "Engine Fluid Level/Pressure 10";
CM_ SG_ 2499608830 EngineCoolantPressure2 "Engine Coolant Pressure 2: Gage pressure of liquid found in the engine coolant system - second instance.See SPN 7313 for alternate range and resolution.";
CM_ SG_ 2499608830 EngnExhstGsRrltn2DffrntlPrssr "Engine Exhaust Gas Recirculation 2 Differential Pressure: Differential Pressure across the Exhaust Gas Recirculation 2 (EGR2) system.";
CM_ SG_ 2499608830 EngnExhstGsRrltn2IntkAsltPrssr "Engine Exhaust Gas Recirculation 2 Intake Absolute Pressure: EGR intake absolute pressure measured before the EGR 2 valve.";
CM_ SG_ 2499608830 EngnExhstGsRrltn2IntkPrssr "Engine Exhaust Gas Recirculation 2 Intake Pressure: EGR2 intake gauge pressure is measured after EGR2 cooler and before EGR2 valve";
CM_ SG_ 2499608830 EngnExhstGsRrltn2OtltAsltPrssr "Engine Exhaust Gas Recirculation 2 Outlet Absolute Pressure: Absolute Pressure immediately after the EGR2 valve";
CM_ BO_ 2365456638 "Generator Phase B Basic AC Quantities";
CM_ SG_ 2365456638 GeneratorPhaseBAcFrequency "Generator Phase B AC Frequency: AC frequency measured at the generator phase B output.";
CM_ SG_ 2365456638 GeneratorPhaseBAcRmsCurrent "Generator Phase B AC RMS Current: RMS current measured at the generator phase B output.";
CM_ SG_ 2365456638 GnrtrPhsBLnLnARmsVltg "Generator Phase BC Line-Line AC RMS Voltage: Line to Line RMS voltage measured at the generator phase BC output.";
CM_ SG_ 2365456638 GnrtrPhsBLnNtrlARmsVltg "Generator Phase B Line-Neutral AC RMS Voltage: Line to Neutral RMS voltage measured at the generator phase B output.";
CM_ BO_ 2351365886 "Motor/Generator 1 Inverter Control";
CM_ SG_ 2351365886 MtrGnrtr1InvrtrCntrlCntr "Motor/Generator 1 Inverter Control Counter: The message counter is used to detect situations where the transmitting ECU malfunction repeats the same frame all the time. The receiver of the information may use the counter parameter to detect this situ...";
CM_ SG_ 2351365886 MtGt1IvtCtLtsRqstOvdMd "Motor/Generator 1 Inverter Control Limits Request Override Mode: This parameter provides a way to temporarily override limits that are being received by the inverter in other messages.  It allows a specific type of limit to be transmitted at a high r...";
CM_ SG_ 2351365886 MtrGnrtr1InvrtrCntrlStpntMdRqst "Motor/Generator 1 Inverter Control Setpoint Mode Request: Requests the modes for this instance of the inverter.  See SPN 10167 [Control Setpoint Mode] for the feedback to this request.Passive modes:  Modes where the inverter does not actively control...";
CM_ SG_ 2351365886 MtrGnrtr1InvrtrCntrlStpntRqst "Motor/Generator 1 Inverter Control Setpoint Request: Requests the set point for this inverter.  The type of set point requested by this parameter depends on the value of SPN 10162 [Control Setpoint Mode Request] as follows:Passive Modes: In any Passi...";
CM_ SG_ 2351365886 MtrGnrtr1InvrtrCntrlCr "Motor/Generator 1 Inverter Control CRC: The CRC is defined as follows: - Length: 8 bits- Polynomial: x^8+x^5+x^3+x^2+x+1- Initial Value: FFh- Input Data Reflection: Not reflected- Result Data Reflection: Not reflected- XOR value: FFh SAE makes no cla...";
CM_ SG_ 2351365886 MtGt1IvtCtLtsRqstOvdMx "Motor/Generator 1 Inverter Control Limits Request Override Maximum: The Maximum limit requested by this parameter depends on the value of SPN 10159 [Control Limits Request Override Mode].In normal operating conditions, the inverter operating limits a...";
CM_ SG_ 2351365886 MtGt1IvtCtLtsRqstOvdM "Motor/Generator 1 Inverter Control Limits Request Override Minimum : The Minimum limit requested by this parameter depends on the value of SPN 10159 [Control Limits Request Override Mode].In normal operating conditions, the inverter operating limits ...";
CM_ BO_ 2351431422 "Motor/Generator 2 Inverter Control";
CM_ SG_ 2351431422 MtrGnrtr2InvrtrCntrlCntr "Motor/Generator 2 Inverter Control Counter: The message counter is used to detect situations where the transmitting ECU malfunction repeats the same frame all the time. The receiver of the information may use the counter parameter to detect this situ...";
CM_ SG_ 2351431422 MtGt2IvtCtLtsRqstOvdMd "Motor/Generator 2 Inverter Control Limits Request Override Mode: This parameter provides a way to temporarily override limits that are being received by the inverter in other messages.  It allows a specific type of limit to be transmitted at a high r...";
CM_ SG_ 2351431422 MtrGnrtr2InvrtrCntrlStpntMdRqst "Motor/Generator 2 Inverter Control Setpoint Mode Request: Requests the modes for this instance of the inverter.  See SPN 10233 [Control Setpoint Mode] for the feedback to this request.Passive modes:  Modes where the inverter does not actively control...";
CM_ SG_ 2351431422 MtrGnrtr2InvrtrCntrlStpntRqst "Motor/Generator 2 Inverter Control Setpoint Request: Requests the set point for this inverter.  The type of set point requested by this parameter depends on the value of SPN 10228 [Control Setpoint Mode Request] as follows:Passive Modes: In any Passi...";
CM_ SG_ 2351431422 MtrGnrtr2InvrtrCntrlCr "Motor/Generator 2 Inverter Control CRC: The CRC is defined as follows: - Length: 8 bits- Polynomial: x^8+x^5+x^3+x^2+x+1- Initial Value: FFh- Input Data Reflection: Not reflected- Result Data Reflection: Not reflected- XOR value: FFh SAE makes no cla...";
CM_ SG_ 2351431422 MtGt2IvtCtLtsRqstOvdMx "Motor/Generator 2 Inverter Control Limits Request Override Maximum: The Maximum limit requested by this parameter depends on the value of SPN 10225 [Control Limits Request Override Mode].In normal operating conditions, the inverter operating limits a...";
CM_ SG_ 2351431422 MtGt2IvtCtLtsRqstOvdM "Motor/Generator 2 Inverter Control Limits Request Override Minimum : The Minimum limit requested by this parameter depends on the value of SPN 10225 [Control Limits Request Override Mode].In normal operating conditions, the inverter operating limits ...";
CM_ BO_ 2556165886 "Motor/Generator 2 Inverter Limits Request Power";
CM_ SG_ 2556165886 MtrGnrtr2InvrtrLmtsRqstPwrCntr "Motor/Generator 2 Inverter Limits Request Power Counter: The message counter is used to detect situations where the transmitting ECU malfunction repeats the same frame all the time. The receiver of the information may use the counter parameter to det...";
CM_ SG_ 2556165886 MtrGnrtr2InvrtrLmtsRqstPwrCr "Motor/Generator 2 Inverter Limits Request Power CRC: The CRC is defined as follows: - Length: 8 bits- Polynomial: x^8+x^5+x^3+x^2+x+1- Initial Value: FFh- Input Data Reflection: Not reflected- Result Data Reflection: Not reflected- XOR value: FFh SAE...";
CM_ SG_ 2556165886 MtGt2IvtLtsRqstMPwMx "Motor/Generator 2 Inverter Limits Request Mechanical Power Maximum: This requests a maximum limit for the mechanical power.Refer to SPN 10238 [Reference Power] to convert % to kW. Request a value of FBFh to instruct the inverter to use its default va...";
CM_ SG_ 2556165886 MtGt2IvtLtsRqstMPwM "Motor/Generator 2 Inverter Limits Request Mechanical Power Minimum: This requests a minimum limit for the mechanical power.Refer to SPN 10238 [Reference Power] to convert % to kW. Request a value of FBFh to instruct the inverter to use its default va...";
CM_ SG_ 2556165886 MtGt2IvtLtsRqstDSdPwMx "Motor/Generator 2 Inverter Limits Request DC Side Power Maximum: This requests a maximum limit for the DC Side power.Refer to SPN 10238 [Reference Power] to convert % to kW. Request a value of FBFh to instruct the inverter to use its default values.F...";
CM_ SG_ 2556165886 MtGt2IvtLtsRqstDSdPwM "Motor/Generator 2 Inverter Limits Request DC Side Power Minimum: This requests a minimum limit for the DC Side power.Refer to SPN 10238 [Reference Power] to convert % to kW. Request a value of FBFh to instruct the inverter to use its default values.F...";
CM_ BO_ 2556231422 "Motor/Generator 2 Inverter Limits Request Mechanical";
CM_ SG_ 2556231422 MtrGnrtr2InvrtrLmtsRqstMhnlCntr "Motor/Generator 2 Inverter Limits Request Mechanical Counter: The message counter is used to detect situations where the transmitting ECU malfunction repeats the same frame all the time. The receiver of the information may use the counter parameter t...";
CM_ SG_ 2556231422 MtrGnrtr2InvrtrLmtsRqstMhnlCr "Motor/Generator 2 Inverter Limits Request Mechanical CRC: The CRC is defined as follows: - Length: 8 bits- Polynomial: x^8+x^5+x^3+x^2+x+1- Initial Value: FFh- Input Data Reflection: Not reflected- Result Data Reflection: Not reflected- XOR value: FF...";
CM_ SG_ 2556231422 MtrGnrtr2InvrtrLmtsRqstTrqMxmm "Motor/Generator 2 Inverter Limits Request Torque Maximum: This requests a maximum torque the inverter should command for this device.Refer to SPN 10236 [Reference Torque] to convert % to Nm. Request a value of FBFh to instruct the inverter to use its...";
CM_ SG_ 2556231422 MtrGnrtr2InvrtrLmtsRqstTrqMnmm "Motor/Generator 2 Inverter Limits Request Torque Minimum: This requests a minimum torque the inverter should command for this device.Refer to SPN 10236 [Reference Torque] to convert % to Nm. Request a value of FBFh to instruct the inverter to use its...";
CM_ SG_ 2556231422 MtrGnrtr2InvrtrLmtsRqstSpdMxmm "Motor/Generator 2 Inverter Limits Request Speed Maximum: This is a request to the inverter to set a maximum speed limit for this device.Refer to SPN 10237 [Reference Speed] to convert % to rpm. Request a value of FBFh to instruct the inverter to use ...";
CM_ SG_ 2556231422 MtrGnrtr2InvrtrLmtsRqstSpdMnmm "Motor/Generator 2 Inverter Limits Request Speed Minimum: This is a request to the inverter to set a minimum speed limit for this device.Refer to SPN 10237 [Reference Speed] to convert % to rpm. Request a value of FBFh to instruct the inverter to use ...";
CM_ BO_ 2556296958 "Motor/Generator 2 Inverter Limits Request DC Side";
CM_ SG_ 2556296958 MtrGnrtr2InvrtrLmtsRqstDSdCr "Motor/Generator 2 Inverter Limits Request DC Side CRC: The CRC is defined as follows: - Length: 8 bits- Polynomial: x^8+x^5+x^3+x^2+x+1- Initial Value: FFh- Input Data Reflection: Not reflected- Result Data Reflection: Not reflected- XOR value: FFh S...";
CM_ SG_ 2556296958 MtrGnrtr2InvrtrLmtsRqstDSdCntr "Motor/Generator 2 Inverter Limits Request DC Side Counter: The message counter is used to detect situations where the transmitting ECU malfunction repeats the same frame all the time. The receiver of the information may use the counter parameter to d...";
CM_ SG_ 2556296958 MtGt2IvtLtsRqstDSdVtMx "Motor/Generator 2 Inverter Limits Request DC Side Voltage Maximum: This is a request to the inverter to set a maximum DC Side Voltage limit for this device instance.Refer to SPN 10269 [Reference Voltage] to convert % to Volts. Request a value of FBFh...";
CM_ SG_ 2556296958 MtGt2IvtLtsRqstDSdVtM "Motor/Generator 2 Inverter Limits Request DC Side Voltage Minimum: This is a request to the inverter to set a minimum DC Side Voltage limit for this device instance.Refer to SPN 10269 [Reference Voltage] to convert % to Volts. Request a value of FBFh...";
CM_ SG_ 2556296958 MtGt2IvtLtsRqstDSdCtMx "Motor/Generator 2 Inverter Limits Request DC Side Current Maximum: This is a request to the inverter to set a maximum DC Side Current limit for this device instance.Refer to SPN 10268 [Reference Current] to convert % to Amps. Request a value of FBFh ...";
CM_ SG_ 2556296958 MtGt2IvtLtsRqstDSdCtM "Motor/Generator 2 Inverter Limits Request DC Side Current Minimum: This is a request to the inverter to set a minimum DC Side Current limit for this device instance.Refer to SPN 10268 [Reference Current] to convert % to Amps. Request a value of FBFh ...";
CM_ BO_ 2556362494 "Motor/Generator 1 Inverter Limits Request DC Side";
CM_ SG_ 2556362494 MtrGnrtr1InvrtrLmtsRqstDSdCr "Motor/Generator 1 Inverter Limits Request DC Side CRC: The CRC is defined as follows: - Length: 8 bits- Polynomial: x^8+x^5+x^3+x^2+x+1- Initial Value: FFh- Input Data Reflection: Not reflected- Result Data Reflection: Not reflected- XOR value: FFh S...";
CM_ SG_ 2556362494 MtrGnrtr1InvrtrLmtsRqstDSdCntr "Motor/Generator 1 Inverter Limits Request DC Side Counter: The message counter is used to detect situations where the transmitting ECU malfunction repeats the same frame all the time. The receiver of the information may use the counter parameter to d...";
CM_ SG_ 2556362494 MtGt1IvtLtsRqstDSdVtMx "Motor/Generator 1 Inverter Limits Request DC Side Voltage Maximum: This is a request to the inverter to set a maximum DC Side Voltage limit for this device instance.Refer to SPN 10203 [Reference Voltage] to convert % to Volts. Request a value of FBFh...";
CM_ SG_ 2556362494 MtGt1IvtLtsRqstDSdVtM "Motor/Generator 1 Inverter Limits Request DC Side Voltage Minimum: This is a request to the inverter to set a minimum DC Side Voltage limit for this device instance.Refer to SPN 10203 [Reference Voltage] to convert % to Volts. Request a value of FBFh...";
CM_ SG_ 2556362494 MtGt1IvtLtsRqstDSdCtMx "Motor/Generator 1 Inverter Limits Request DC Side Current Maximum: This is a request to the inverter to set a maximum DC Side Current limit for this device instance.Refer to SPN 10202 [Reference Current] to convert % to Amps. Request a value of FBFh ...";
CM_ SG_ 2556362494 MtGt1IvtLtsRqstDSdCtM "Motor/Generator 1 Inverter Limits Request DC Side Current Minimum: This is a request to the inverter to set a minimum DC Side Current limit for this device instance.Refer to SPN 10202 [Reference Current] to convert % to Amps. Request a value of FBFh ...";
CM_ BO_ 2556428030 "Motor/Generator 1 Inverter Limits Request Mechanical";
CM_ SG_ 2556428030 MtrGnrtr1InvrtrLmtsRqstMhnlCntr "Motor/Generator 1 Inverter Limits Request Mechanical Counter: The message counter is used to detect situations where the transmitting ECU malfunction repeats the same frame all the time. The receiver of the information may use the counter parameter t...";
CM_ SG_ 2556428030 MtrGnrtr1InvrtrLmtsRqstMhnlCr "Motor/Generator 1 Inverter Limits Request Mechanical CRC: The CRC is defined as follows: - Length: 8 bits- Polynomial: x^8+x^5+x^3+x^2+x+1- Initial Value: FFh- Input Data Reflection: Not reflected- Result Data Reflection: Not reflected- XOR value: FF...";
CM_ SG_ 2556428030 MtrGnrtr1InvrtrLmtsRqstTrqMxmm "Motor/Generator 1 Inverter Limits Request Torque Maximum: This requests a maximum torque the inverter should command for this device.Refer to SPN 10170 [Reference Torque] to convert % to Nm. Request a value of FBFh to instruct the inverter to use its...";
CM_ SG_ 2556428030 MtrGnrtr1InvrtrLmtsRqstTrqMnmm "Motor/Generator 1 Inverter Limits Request Torque Minimum: This requests a minimum torque the inverter should command for this device.Refer to SPN 10170 [Reference Torque] to convert % to Nm. Request a value of FBFh to instruct the inverter to use its...";
CM_ SG_ 2556428030 MtrGnrtr1InvrtrLmtsRqstSpdMxmm "Motor/Generator 1 Inverter Limits Request Speed Maximum: This is a request to the inverter to set a maximum speed limit for this device.Refer to SPN 10171 [Reference Speed] to convert % to rpm. Request a value of FBFh to instruct the inverter to use ...";
CM_ SG_ 2556428030 MtrGnrtr1InvrtrLmtsRqstSpdMnmm "Motor/Generator 1 Inverter Limits Request Speed Minimum: This is a request to the inverter to set a minimum speed limit for this device.Refer to SPN 10171 [Reference Speed] to convert % to rpm. Request a value of FBFh to instruct the inverter to use ...";
CM_ BO_ 2556493566 "Motor/Generator 1 Inverter Limits Request Power";
CM_ SG_ 2556493566 MtrGnrtr1InvrtrLmtsRqstPwrCntr "Motor/Generator 1 Inverter Limits Request Power Counter: The message counter is used to detect situations where the transmitting ECU malfunction repeats the same frame all the time. The receiver of the information may use the counter parameter to det...";
CM_ SG_ 2556493566 MtrGnrtr1InvrtrLmtsRqstPwrCr "Motor/Generator 1 Inverter Limits Request Power CRC: The CRC is defined as follows: - Length: 8 bits- Polynomial: x^8+x^5+x^3+x^2+x+1- Initial Value: FFh- Input Data Reflection: Not reflected- Result Data Reflection: Not reflected- XOR value: FFh SAE...";
CM_ SG_ 2556493566 MtGt1IvtLtsRqstMPwMx "Motor/Generator 1 Inverter Limits Request Mechanical Power Maximum: This requests a maximum limit for the mechanical power.Refer to SPN 10172 [Reference Power] to convert % to kW. Request a value of FBFh to instruct the inverter to use its default va...";
CM_ SG_ 2556493566 MtGt1IvtLtsRqstMPwM "Motor/Generator 1 Inverter Limits Request Mechanical Power Minimum: This requests a minimum limit for the mechanical power.Refer to SPN 10172 [Reference Power] to convert % to kW. Request a value of FBFh to instruct the inverter to use its default va...";
CM_ SG_ 2556493566 MtGt1IvtLtsRqstDSdPwMx "Motor/Generator 1 Inverter Limits Request DC Side Power Maximum: This requests a maximum limit for the DC Side power.Refer to SPN 10172 [Reference Power] to convert % to kW. Request a value of FBFh to instruct the inverter to use its default values.F...";
CM_ SG_ 2556493566 MtGt1IvtLtsRqstDSdPwM "Motor/Generator 1 Inverter Limits Request DC Side Power Minimum: This requests a minimum limit for the DC Side power.Refer to SPN 10172 [Reference Power] to convert % to kW. Request a value of FBFh to instruct the inverter to use its default values.F...";
CM_ BO_ 2556559102 "Personnel Detect Interlock";
CM_ SG_ 2556559102 PrsnnlDttAlrmRvStts "Personnel Detect Alarm Receive Status: Indicates status of receiving the personnel detect alarm status information.000b = Alarm Status Data Not Received001b = Alarm Status Data Received010b = Reserved for SAE assignment011b = Reserved for SAE assignm...";
CM_ SG_ 2556559102 PrsnnlDttSqnCntrEh "Personnel Detect Sequence Counter Echo: Indicates the sequence counter value of the Personnel Detect Status message or group acknowledged.";
CM_ BO_ 2556624638 "Engine Cylinder Combustion Configuration Feedback";
CM_ SG_ 2556624638 CnfgrdEngnClndrMssFrtnBrndLtn1 "Configured Engine Cylinder Mass Fraction Burned Location 1: Configured value in use for x% mass fraction burned when reporting Engine Cylinder Instantaneous Combustion Timing, Location 1 in ECCT1-20.";
CM_ SG_ 2556624638 CnfgrdEngnClndrMssFrtnBrndLtn2 "Configured Engine Cylinder Mass Fraction Burned Location 2: Configured value in use for y% mass fraction burned when reporting Engine Cylinder Instantaneous Combustion Timing, Location 2 in ECCT1-20.";
CM_ BO_ 2556690174 "Engine Cylinder Combustion Configuration";
CM_ SG_ 2556690174 EngnClndrMssFrtnBrndLtn1 "Engine Cylinder Mass Fraction Burned Location 1: Commanded value to use for x% mass fraction burned when reporting Engine Cylinder Instantaneous Combustion Timing, Location 1 in ECCT1-20.";
CM_ SG_ 2556690174 EngnClndrMssFrtnBrndLtn2 "Engine Cylinder Mass Fraction Burned Location 2: Commanded value to use for y% mass fraction burned when reporting Engine Cylinder Instantaneous Combustion Timing, Location 2 in ECCT1-20.";
CM_ BO_ 2556755710 "Engine Cylinder Pressure Timing Feedback";
CM_ SG_ 2556755710 CnfgrdEngnClndrPrssrTmng1 "Configured Engine Cylinder Pressure Timing 1: Configured timing location #1 for combustion pressure reporting in ECCP1-20.  When the combustion happens after the TDC (Top Dead Center) of this cylinder, the timing is referred in terms of positive angl...";
CM_ SG_ 2556755710 CnfgrdEngnClndrPrssrTmng2 "Configured Engine Cylinder Pressure Timing 2: Configured timing location #2 for combustion pressure reporting in ECCP1-20.  When the combustion happens after the TDC (Top Dead Center) of this cylinder, the timing is referred in terms of positive angl...";
CM_ SG_ 2556755710 CnfgrdEngnClndrPrssrTmng3 "Configured Engine Cylinder Pressure Timing 3: Configured timing location #3 for combustion pressure reporting in ECCP1-20. When the combustion happens after the TDC (Top Dead Center) of this cylinder, the timing is referred in terms of positive angle...";
CM_ SG_ 2556755710 CnfgrdEngnClndrPrssrTmng4 "Configured Engine Cylinder Pressure Timing 4: Configured timing location #4 for combustion pressure reporting in ECCP1-20.  When the combustion happens after the TDC (Top Dead Center) of this cylinder, the timing is referred in terms of positive angl...";
CM_ BO_ 2556821246 "Engine Cylinder Pressure Timing Configuration";
CM_ SG_ 2556821246 EngineCylinderPressureTiming1 "Engine Cylinder Pressure Timing 1: Commanded timing location #1 for in-cylinder pressure reports in ECCP1-20.  When the combustion happens after the TDC (Top Dead Center) of this cylinder, the timing is referred in terms of positive angle and if comb...";
CM_ SG_ 2556821246 EngineCylinderPressureTiming2 "Engine Cylinder Pressure Timing 2: Commanded timing location #2 for in-cylinder pressure reports in ECCP1-20. When the combustion happens after the TDC (Top Dead Center) of this cylinder, the timing is referred in terms of positive angle and if combu...";
CM_ SG_ 2556821246 EngineCylinderPressureTiming3 "Engine Cylinder Pressure Timing 3: Commanded timing location #3 for in-cylinder pressure reports in ECCP1-20. When the combustion happens after the TDC (Top Dead Center) of this cylinder, the timing is referred in terms of positive angle and if combu...";
CM_ SG_ 2556821246 EngineCylinderPressureTiming4 "Engine Cylinder Pressure Timing 4: Commanded timing location #4 for in-cylinder pressure reports in ECCP1-20. When the combustion happens after the TDC (Top Dead Center) of this cylinder, the timing is referred in terms of positive angle and if combu...";
CM_ BO_ 2556886782 "Electrified Accessory Generator Coolant Pump Command ";
CM_ SG_ 2556886782 GnrtrClntPmpEnlCmmnd "Generator Coolant Pump Enable Command: Enable and direction command to the Generator Coolant Pump.00b = Accessory Motor Off01b = Accessory Motor On Normal/Default Direction10b = Accessory Motor On Reverse Direction11b = Don't Care/Take no action...";
CM_ SG_ 2556886782 GeneratorCoolantPumpPowerHold "Generator Coolant Pump Power Hold: Command to allow the Generator Coolant Pump to remain alive independently of the electrical enable input to the Accessory Motor.  For example, this could allow continued device operation after the keyswitch has turn...";
CM_ SG_ 2556886782 GnrtrClntPmpSpdCmmnd "Generator Coolant Pump Speed Command: Speed command to the Generator Coolant Pump.Note: Both Speed Command and Percent Speed Command cannot be used at the same time.  Always set the unused speed command to Not Available.  If both commands are set to ...";
CM_ SG_ 2556886782 GnrtrClntPmpPrntSpdCmmnd "Generator Coolant Pump Percent Speed Command: Speed command to the Generator Coolant Pump in percentage of maximum speed.Note: Both Speed Command and Percent Speed Command cannot be used at the same time.  Always set the unused speed command to Not A...";
CM_ SG_ 2556886782 EtdAssGtCtPpCdEdddIttSppt "Electrified Accessory Generator Coolant Pump Command Embedded Integrity Support: Indicates that SPN 23540 (Electrified Accessory Generator Coolant Pump Command CRC) and SPN 23539 (Electrified Accessory Generator Coolant Pump Command Counter) are supp...";
CM_ SG_ 2556886782 EltrfdAssrGnrtrClntPmpCmmndCntr "Electrified Accessory Generator Coolant Pump Command Counter: The message counter is used to detect situations where the transmitting ECU malfunction repeats the same frame all the time. The receiver of the information may use the counter parameter t...";
CM_ SG_ 2556886782 EltrfdAssrGnrtrClntPmpCmmndCr "Electrified Accessory Generator Coolant Pump Command CRC: The CRC is defined as follows:  - Length: 8 bits  - Polynomial: x^8+x^5+x^3+x^2+x+1  - Initial Value: FFh  - Input Data Reflection: Not reflected  - Result Data Reflection: Not reflected  - XO...";
CM_ BO_ 2556952318 "Electrified Accessory Generator Coolant Fan Command ";
CM_ SG_ 2556952318 GnrtrClntFnEnlCmmnd "Generator Coolant Fan Enable Command: Enable and direction command to the Generator Coolant Fan.00b = Accessory Motor Off01b = Accessory Motor On Normal/Default Direction10b = Accessory Motor On Reverse Direction11b = Don't Care/Take no action...";
CM_ SG_ 2556952318 GeneratorCoolantFanPowerHold "Generator Coolant Fan Power Hold: Command to allow the Generator Coolant Fan to remain alive independently of the electrical enable input to the Accessory Motor.  For example, this could allow continued device operation after the keyswitch has turned...";
CM_ SG_ 2556952318 GeneratorCoolantFanSpeedCommand "Generator Coolant Fan Speed Command: Speed command to the Generator Coolant Fan.Note: Both Speed Command and Percent Speed Command cannot be used at the same time.  Always set the unused speed command to Not Available.  If both commands are set to No...";
CM_ SG_ 2556952318 GnrtrClntFnPrntSpdCmmnd "Generator Coolant Fan Percent Speed Command: Speed command to the Generator Coolant Fan in percentage of maximum speed.Note: Both Speed Command and Percent Speed Command cannot be used at the same time.  Always set the unused speed command to Not Ava...";
CM_ SG_ 2556952318 EtdAssGtCtFCdEdddIttSppt "Electrified Accessory Generator Coolant Fan Command Embedded Integrity Support: Indicates that SPN 23543 (Electrified Accessory Generator Coolant Fan Command CRC) and SPN 23542 (Electrified Accessory Generator Coolant Fan Command Counter) are support...";
CM_ SG_ 2556952318 EltrfdAssrGnrtrClntFnCmmndCntr "Electrified Accessory Generator Coolant Fan Command Counter: The message counter is used to detect situations where the transmitting ECU malfunction repeats the same frame all the time. The receiver of the information may use the counter parameter to...";
CM_ SG_ 2556952318 EltrfdAssrGnrtrClntFnCmmndCr "Electrified Accessory Generator Coolant Fan Command CRC: The CRC is defined as follows:  - Length: 8 bits  - Polynomial: x^8+x^5+x^3+x^2+x+1  - Initial Value: FFh  - Input Data Reflection: Not reflected  - Result Data Reflection: Not reflected  - XOR...";
CM_ BO_ 2557017854 "On Board Programming 1";
CM_ SG_ 2557017854 OnBoardProgrammingStatus "On Board Programming Status: Status of a software update.0000b = Software Up to Date: no new software is available0001b = Available for Installation: updated software is available0010b = In process/Installing: update has been initiated and progressin...";
CM_ SG_ 2557017854 ObpInterlockOverallStatus "OBP Interlock - Overall Status: Indicates whether all interlocks for on board programming (OBP) have been satisfied. This parameter should be set to On whever any of the other OBP Interlocks are on. This allows a receiving device to know whether prog...";
CM_ SG_ 2557017854 ObpInterlockEngineSpeed "OBP Interlock - Engine Speed: Engine speed requirement is not met to allow initiation of on board programming (OBP).00b = Off: Engine speed is permitting on board programming01b = On: On board programming is inhibited due to engine speed.10b = Error1...";
CM_ SG_ 2557017854 ObpInterlockKeySwitchPosition "OBP Interlock - Key Switch Position: Key switch position requirement is not met to allow initiation of on board programming (OBP).00b = Off: Key switch position is permitting on board programming01b = On: On board programming is inhibited due to key ...";
CM_ SG_ 2557017854 ObpInterlockParkBrake "OBP Interlock - Park Brake: Park brake requirement is not met to allow initiation of on board programming (OBP).00b = Off: Park brake is permitting on board programming01b = On: On board programming is inhibited due to park brake10b = Error11b = Not ...";
CM_ SG_ 2557017854 ObpInterlockTargetNotReady "OBP Interlock - Target Not Ready: Indicates whether the target is not ready to accept on board programming (OBP).00b = Off: Target is not inhibiting on board programming01b = On: Target has indicated that it is currently unable to accept on board pro...";
CM_ SG_ 2557017854 ObpKeySwitchRequest "OBP Key Switch Request: Request to turn the key switch to the ignition or run position and/or prevent the ignition bus from turning off during on board programming (OBP).00b = On board programming device is not requesting key switch on.01b = On board...";
CM_ SG_ 2557017854 OnBoardProgrammingProgress "On Board Programming Progress: Amount of programming progress completed in relation to the total expected duration of the programming event.";
CM_ SG_ 2557017854 OnBrdPrgrmmngTrgtEAddrss "On Board Programming Target ECU Address: Source address of target device to be programmed, for which the message parameters apply.When SPN 9767 (On Board Programming Status) parameter indicates no updates are available for all supported targets, this...";
CM_ SG_ 2557017854 OpIntrlkPwrSpplInsffnt "OBP Interlock - Power Supply Insufficient: Power supply (e.g. SLI battery state of charge) is not sufficient to allow initiation of on board programming (OBP).00b = Off: Power supply is sufficient to permit on board programming01b = On: On board prog...";
CM_ SG_ 2557017854 OpSftwrUpdtDfrrlsRmnng "OBP Software Update Deferrals Remaining: Indicates the remaining number of times a software update can be deferred. Value is reset to maximum when the software is updated or when new software is available.";
CM_ SG_ 2557017854 ObpPowerOffSoftwareUpdateStatus "OBP Power-Off Software Update Status: Indicates On Board Programming will occur on the next powerdown event when all interlocks indicate it is permitted.00b - Software will not be updated at power-off01b - Software will be updated at power-off10b - R...";
CM_ BO_ 2557083390 "Marine Control Information Configuration 1";
CM_ SG_ 2557083390 OperatorStationLocationSetting "Operator Station Location Setting: Configurable location of the selected operator station.00h = Bridge01h = Port Wing02h = Starboard Wing03h = Tower04h = Engine Room05h = Aft. Station06h = Fly Bridge07h = Bow Station08h to FDh = ReservedFEh = ErrorFF...";
CM_ SG_ 2557083390 TrollingModeSettingCommand "Trolling Mode Setting Command: The commanded setting of the Trolling Mode.  In traditional trolling mode, engine speed remains constant while the throttle lever changes the amount of slip within the transmission clutches. In advanced trolling mode, t...";
CM_ SG_ 2557083390 EngnThrttlSnhrnztnMdCmmnd "Engine Throttle Synchronization Mode Command: The setting of the throttle synchronization mode. Throttle synchronization mode is used to indicate which throttle, if any, is used to be used for the synchronized throttle.0000b = Not Synchronized0001b =...";
CM_ SG_ 2557083390 EngineTrollingModeSetSpeed "Engine Trolling Mode Set Speed: The (chosen) vessel trolling speed that has been selected by the operator";
CM_ BO_ 2557148926 "Marine Control Information 2";
CM_ SG_ 2557148926 OprtrSttnInCntrlLtn "Operator Station In Control Location: Identifies the location of the operator station that is currently in control of the system.00h = Bridge01h = Port Wing02h = Starboard Wing03h = Tower04h = Engine Room05h = Aft. Station06h = Fly Bridge07h = Bow St...";
CM_ SG_ 2557148926 OperatorStationLockout "Operator Station Lockout: Indicates the status of a lockout to prevent changing the active control station. Lockout active indicates a change is not permitted to the active control station.00b = Station Lockout Inactive01b = Station Lockout Active10b...";
CM_ SG_ 2557148926 EngnThrttlSnhrnztnMdCrrntSttng "Engine Throttle Synchronization Mode Current Setting: The current setting of the engine throttle synchronization mode. Throttle synchronization mode indicates which throttle, if any, is to be used for the synchronized throttle.0000b = Not Synchronize...";
CM_ SG_ 2557148926 TrollingModeExtendedRange "Trolling Mode (Extended Range): The active status of the Trolling Mode (Extended Range). In traditional trolling mode, engine speed remains constant while the throttle lever changes the amount of slip within the transmission clutches. In advanced tro...";
CM_ SG_ 2557148926 TrollingModeCurrentSetting "Trolling Mode Current Setting: The current setting of the Trolling Mode.  In traditional trolling mode, engine speed remains constant while the throttle lever changes the amount of slip within the transmission clutches. In advanced trolling mode, the...";
CM_ SG_ 2557148926 VesselEngineSetSpeed "Vessel Engine Set Speed: The (chosen) vessel speed that has been selected by the operator.";
CM_ SG_ 2557148926 VesselSpeedControlMode "Vessel Speed Control Mode: The vessel set speed type that is selected by the operator.00h = No Set Speed01h = Slow Vessel Mode02h = Synchronization Mode03h = Trolling Mode04h to FDh = ReservedFEh = ErrorFFh = Not Available";
CM_ BO_ 2364617726 "Engine Pre-Chamber Fuel Valve Duration Command 1";
CM_ SG_ 2364617726 EngnPrChmrFlVlv1Drtn "Engine Pre-Chamber Fuel Valve 1 Duration: Amount of time the pre-chamber fuel valve 1 is activated.";
CM_ SG_ 2364617726 EngnPrChmrFlVlv2Drtn "Engine Pre-Chamber Fuel Valve 2 Duration: Amount of time the pre-chamber fuel valve 2 is activated.";
CM_ SG_ 2364617726 EngnPrChmrFlVlv3Drtn "Engine Pre-Chamber Fuel Valve 3 Duration: Amount of time the pre-chamber fuel valve 3 is activated.";
CM_ SG_ 2364617726 EngnPrChmrFlVlv4Drtn "Engine Pre-Chamber Fuel Valve 4 Duration: Amount of time the pre-chamber fuel valve 4 is activated.";
CM_ BO_ 2364617982 "Engine Pre-Chamber Fuel Valve Duration Command 2";
CM_ SG_ 2364617982 EngnPrChmrFlVlv5Drtn "Engine Pre-Chamber Fuel Valve 5 Duration: Amount of time the pre-chamber fuel valve 5 is activated.";
CM_ SG_ 2364617982 EngnPrChmrFlVlv6Drtn "Engine Pre-Chamber Fuel Valve 6 Duration: Amount of time the pre-chamber fuel valve 6 is activated.";
CM_ SG_ 2364617982 EngnPrChmrFlVlv7Drtn "Engine Pre-Chamber Fuel Valve 7 Duration: Amount of time the pre-chamber fuel valve 7 is activated.";
CM_ SG_ 2364617982 EngnPrChmrFlVlv8Drtn "Engine Pre-Chamber Fuel Valve 8 Duration: Amount of time the pre-chamber fuel valve 8 is activated.";
CM_ BO_ 2364618238 "Engine Pre-Chamber Fuel Valve Duration Command 3";
CM_ SG_ 2364618238 EngnPrChmrFlVlv9Drtn "Engine Pre-Chamber Fuel Valve 9 Duration: Amount of time the pre-chamber fuel valve 9 is activated.";
CM_ SG_ 2364618238 EngnPrChmrFlVlv10Drtn "Engine Pre-Chamber Fuel Valve 10 Duration: Amount of time the pre-chamber fuel valve 10 is activated.";
CM_ SG_ 2364618238 EngnPrChmrFlVlv11Drtn "Engine Pre-Chamber Fuel Valve 11 Duration: Amount of time the pre-chamber fuel valve 11 is activated.";
CM_ SG_ 2364618238 EngnPrChmrFlVlv12Drtn "Engine Pre-Chamber Fuel Valve 12 Duration: Amount of time the pre-chamber fuel valve 12 is activated.";
CM_ BO_ 2364618494 "Engine Pre-Chamber Fuel Valve Duration Command 4";
CM_ SG_ 2364618494 EngnPrChmrFlVlv13Drtn "Engine Pre-Chamber Fuel Valve 13 Duration: Amount of time the pre-chamber fuel valve 13 is activated.";
CM_ SG_ 2364618494 EngnPrChmrFlVlv14Drtn "Engine Pre-Chamber Fuel Valve 14 Duration: Amount of time the pre-chamber fuel valve 14 is activated.";
CM_ SG_ 2364618494 EngnPrChmrFlVlv15Drtn "Engine Pre-Chamber Fuel Valve 15 Duration: Amount of time the pre-chamber fuel valve 15 is activated.";
CM_ SG_ 2364618494 EngnPrChmrFlVlv16Drtn "Engine Pre-Chamber Fuel Valve 16 Duration: Amount of time the pre-chamber fuel valve 16 is activated.";
CM_ BO_ 2364618750 "Engine Pre-Chamber Fuel Valve Duration Command 5";
CM_ SG_ 2364618750 EngnPrChmrFlVlv17Drtn "Engine Pre-Chamber Fuel Valve 17 Duration: Amount of time the pre-chamber fuel valve 17 is activated.";
CM_ SG_ 2364618750 EngnPrChmrFlVlv18Drtn "Engine Pre-Chamber Fuel Valve 18 Duration: Amount of time the pre-chamber fuel valve 18 is activated.";
CM_ SG_ 2364618750 EngnPrChmrFlVlv19Drtn "Engine Pre-Chamber Fuel Valve 19 Duration: Amount of time the pre-chamber fuel valve 19 is activated.";
CM_ SG_ 2364618750 EngnPrChmrFlVlv20Drtn "Engine Pre-Chamber Fuel Valve 20 Duration: Amount of time the pre-chamber fuel valve 20 is activated.";
CM_ BO_ 2364619006 "Engine Pre-Chamber Fuel Valve Start of Actuation Command 1";
CM_ SG_ 2364619006 EngnPrChmrFlVlv1StrtOfAttnCmmnd "Engine Pre-Chamber Fuel Valve 1 Start of Actuation Command: The angle, relative to the TDC of cylinder 1 with 0 being the TDC before the power stroke commences, at the which pre-chamber fuel valve 1 is activated to open.";
CM_ SG_ 2364619006 EngnPrChmrFlVlv2StrtOfAttnCmmnd "Engine Pre-Chamber Fuel Valve 2 Start of Actuation Command: The angle, relative to the TDC of cylinder 2 with 0 being the TDC before the power stroke commences, at the which pre-chamber fuel valve 2 is activated to open.";
CM_ SG_ 2364619006 EngnPrChmrFlVlv3StrtOfAttnCmmnd "Engine Pre-Chamber Fuel Valve 3 Start of Actuation Command: The angle, relative to the TDC of cylinder 3 with 0 being the TDC before the power stroke commences, at the which pre-chamber fuel valve 3 is activated to open.";
CM_ SG_ 2364619006 EngnPrChmrFlVlv4StrtOfAttnCmmnd "Engine Pre-Chamber Fuel Valve 4 Start of Actuation Command: The angle, relative to the TDC of cylinder 4 with 0 being the TDC before the power stroke commences, at the which pre-chamber fuel valve 4 is activated to open.";
CM_ BO_ 2364619262 "Engine Pre-Chamber Fuel Valve Start of Actuation Command 2";
CM_ SG_ 2364619262 EngnPrChmrFlVlv5StrtOfAttnCmmnd "Engine Pre-Chamber Fuel Valve 5 Start of Actuation Command: The angle, relative to the TDC of cylinder 5 with 0 being the TDC before the power stroke commences, at the which pre-chamber fuel valve 5 is activated to open.";
CM_ SG_ 2364619262 EngnPrChmrFlVlv6StrtOfAttnCmmnd "Engine Pre-Chamber Fuel Valve 6 Start of Actuation Command: The angle, relative to the TDC of cylinder 6 with 0 being the TDC before the power stroke commences, at the which pre-chamber fuel valve 6 is activated to open.";
CM_ SG_ 2364619262 EngnPrChmrFlVlv7StrtOfAttnCmmnd "Engine Pre-Chamber Fuel Valve 7 Start of Actuation Command: The angle, relative to the TDC of cylinder 7 with 0 being the TDC before the power stroke commences, at the which pre-chamber fuel valve 7 is activated to open.";
CM_ SG_ 2364619262 EngnPrChmrFlVlv8StrtOfAttnCmmnd "Engine Pre-Chamber Fuel Valve 8 Start of Actuation Command: The angle, relative to the TDC of cylinder 8 with 0 being the TDC before the power stroke commences, at the which pre-chamber fuel valve 8 is activated to open.";
CM_ BO_ 2364619518 "Engine Pre-Chamber Fuel Valve Start of Actuation Command 3";
CM_ SG_ 2364619518 EngnPrChmrFlVlv9StrtOfAttnCmmnd "Engine Pre-Chamber Fuel Valve 9 Start of Actuation Command: The angle, relative to the TDC of cylinder 9 with 0 being the TDC before the power stroke commences, at the which pre-chamber fuel valve 9 is activated to open.";
CM_ SG_ 2364619518 EPCFVv10SttOAttCd "Engine Pre-Chamber Fuel Valve 10 Start of Actuation Command: The angle, relative to the TDC of cylinder 10 with 0 being the TDC before the power stroke commences, at the which pre-chamber fuel valve 10 is activated to open.";
CM_ SG_ 2364619518 EPCFVv11SttOAttCd "Engine Pre-Chamber Fuel Valve 11 Start of Actuation Command: The angle, relative to the TDC of cylinder 11 with 0 being the TDC before the power stroke commences, at the which pre-chamber fuel valve 11 is activated to open.";
CM_ SG_ 2364619518 EPCFVv12SttOAttCd "Engine Pre-Chamber Fuel Valve 12 Start of Actuation Command: The angle, relative to the TDC of cylinder 12 with 0 being the TDC before the power stroke commences, at the which pre-chamber fuel valve 12 is activated to open.";
CM_ BO_ 2364619774 "Engine Pre-Chamber Fuel Valve Start of Actuation Command 4";
CM_ SG_ 2364619774 EPCFVv13SttOAttCd "Engine Pre-Chamber Fuel Valve 13 Start of Actuation Command: The angle, relative to the TDC of cylinder 13 with 0 being the TDC before the power stroke commences, at the which pre-chamber fuel valve 13 is activated to open.";
CM_ SG_ 2364619774 EPCFVv14SttOAttCd "Engine Pre-Chamber Fuel Valve 14 Start of Actuation Command: The angle, relative to the TDC of cylinder 14 with 0 being the TDC before the power stroke commences, at the which pre-chamber fuel valve 14 is activated to open.";
CM_ SG_ 2364619774 EPCFVv15SttOAttCd "Engine Pre-Chamber Fuel Valve 15 Start of Actuation Command: The angle, relative to the TDC of cylinder 15 with 0 being the TDC before the power stroke commences, at the which pre-chamber fuel valve 15 is activated to open.";
CM_ SG_ 2364619774 EPCFVv16SttOAttCd "Engine Pre-Chamber Fuel Valve 16 Start of Actuation Command: The angle, relative to the TDC of cylinder 16 with 0 being the TDC before the power stroke commences, at the which pre-chamber fuel valve 16 is activated to open.";
CM_ BO_ 2364620030 "Engine Pre-Chamber Fuel Valve Start of Actuation Command 5";
CM_ SG_ 2364620030 EPCFVv17SttOAttCd "Engine Pre-Chamber Fuel Valve 17 Start of Actuation Command: The angle, relative to the TDC of cylinder 17 with 0 being the TDC before the power stroke commences, at the which pre-chamber fuel valve 17 is activated to open.";
CM_ SG_ 2364620030 EPCFVv18SttOAttCd "Engine Pre-Chamber Fuel Valve 18 Start of Actuation Command: The angle, relative to the TDC of cylinder 18 with 0 being the TDC before the power stroke commences, at the which pre-chamber fuel valve 18 is activated to open.";
CM_ SG_ 2364620030 EPCFVv19SttOAttCd "Engine Pre-Chamber Fuel Valve 19 Start of Actuation Command: The angle, relative to the TDC of cylinder 19 with 0 being the TDC before the power stroke commences, at the which pre-chamber fuel valve 19 is activated to open.";
CM_ SG_ 2364620030 EPCFVv20SttOAttCd "Engine Pre-Chamber Fuel Valve 20 Start of Actuation Command: The angle, relative to the TDC of cylinder 20 with 0 being the TDC before the power stroke commences, at the which pre-chamber fuel valve 20 is activated to open.";
CM_ BO_ 2364620286 "Active Steering System Controls 1";
CM_ SG_ 2364620286 LnKpngAssstSttsRghtSd "Lane Keeping Assist Status Right Side: Indicates the current status of lane keeping assist feature for right side lane marker.000b = Lane Keeping Assist Not Available for Right Side001b = Lane Keeping Assist Available for Right Side010b = Lane Keepin...";
CM_ SG_ 2364620286 LaneKeepingAssistStatusLeftSide "Lane Keeping Assist Status Left Side: Indicates the current status of lane keeping assist feature for left side lane marker.000b = Lane Keeping Assist Not Available for Left Side001b = Lane Keeping Assist Available for Left Side010b = Lane Keeping As...";
CM_ SG_ 2364620286 LnKpngAssstIndtnEnlStts "Lane Keeping Assist Indication Enable Status: Indicates whether lane keeping assist is enabled.00b = Lane Keeping Assist disabled01b = Lane Keeping Assist enabled10b = Error11b = Not available";
CM_ SG_ 2364620286 LaneKeepingAssistSystemState "Lane Keeping Assist System State: Indicates the current state of the Lane Keep Assist feature.0000b = System is not ready (initialization not finished)0001b = System is temporarily not available (not all activation conditions fulfulled)0010b = System...";
CM_ SG_ 2364620286 ActiveSteeringDriverPreference "Active Steering Driver Preference: Indicates the current preference for active steering mode selected by the driver.000b = Active Steering Mode #1001b = Active Steering Mode #2010b = Active Steering Mode #3011b = Active Steering Mode #4100b = Active ...";
CM_ SG_ 2364620286 LnCntrngIndtnEnlStt "Lane Centering Indication Enable State: Indicates whether lane centering indication is enabled.00b = Lane Centering Indication disabled01b = Lane Centering Indication enabled10b = Error11b = Not available";
CM_ SG_ 2364620286 LaneCenteringSystemStatus "Lane Centering System Status: Indicates the current state of the Lane Centering feature.0000b = System is not ready (initialization not finished)0001b = System is temporarily not available (not all activation conditions fulfulled)0010b = System is de...";
CM_ SG_ 2364620286 HandsOffDetectionStatus "Hands Off Detection Status: Defines whether the Hands Off Detection feature has detected the operator is driving with their hands off the steering wheel for an extended amount of time000b = Hands Off Not Detected001b = Hands Off Detected010b = Hands ...";
CM_ SG_ 2364620286 HandsOffDetectionAvailability "Hands Off Detection Availability: Defines whether the Hands Off Detection feature has passed the set preconditions or not.  Allows the feature to be disabled if preconditions are not and be enabled when the preconditions are met.000b = Hands Off Dete...";
CM_ BO_ 2364621054 "Stationary Inverter Average Basic AC Quantities";
CM_ SG_ 2364621054 SttnrInvrtrAvrgARmsVltg "Stationary Inverter Average AC RMS Voltage: Average Line to Line AC RMS voltage measured at the inverter output.For stationary non-vehicular applications of inverters.";
CM_ SG_ 2364621054 SttnrInvrtrAvrgLnNtrlARmsVltg "Stationary Inverter Average Line-Neutral AC RMS Voltage: Average Line to Neutral AC RMS voltage measured at the inverter output.For stationary non-vehicular applications of inverters.";
CM_ SG_ 2364621054 SttnrInvrtrAvrgAFrqn "Stationary Inverter Average AC Frequency: Average AC frequency measured at the inverter output.For stationary non-vehicular applications of inverters.";
CM_ SG_ 2364621054 SttnrInvrtrAvrgARmsCrrnt "Stationary Inverter Average AC RMS Current: Average AC RMS current measured at the inverter output.For stationary non-vehicular applications of inverters.";
CM_ BO_ 2364621310 "Stationary Inverter Total AC Reactive Power";
CM_ SG_ 2364621310 SttnrInvrtrTtlRtvPwr "Stationary Inverter Total Reactive Power: The total reactive power delivered by the inverter.For stationary non-vehicular applications of inverters.";
CM_ SG_ 2364621310 SttnrInvrtrOvrllPwrFtr "Stationary Inverter Overall Power Factor: The average power factor of the inverter.For stationary non-vehicular applications of inverters.";
CM_ SG_ 2364621310 SttnrInvrtrOvrllPwrFtrLggng "Stationary Inverter Overall Power Factor Lagging: Lead/lag status for inverter average power factor.For stationary non-vehicular applications of inverters.00b = Leading01b = Lagging10b = Error11b = Not Available or Not Installed";
CM_ BO_ 2364621566 "Stationary Inverter Total AC Power";
CM_ SG_ 2364621566 SttnrInvrtrTtlRlPwr "Stationary Inverter Total Real Power: Total real power delivered by the inverter.For stationary non-vehicular applications of inverters.";
CM_ SG_ 2364621566 SttnrInvrtrTtlApprntPwr "Stationary Inverter Total Apparent Power: The total apparent power delivered by the inverter.For stationary non-vehicular applications of inverters.";
CM_ BO_ 2364621822 "Stationary Inverter Control";
CM_ SG_ 2364621822 SttnrInvrtrNtRdTAtmtllPrlllStt "Stationary Inverter Not Ready to Automatically Parallel State: This parameter indicates whether or not all systems required to operate the inverter and close to the bus are prepared to operate automatically. If systems are not ready to operate in par...";
CM_ SG_ 2364621822 SttnrInvrtrAxlrShtdwnSwth "Stationary Inverter Auxiliary Shutdown Switch: Switch signal which requests that all inverter functions stop.For stationary non-vehicular applications of inverters.00b = Off01b = On10b = Error11b = Not available";
CM_ BO_ 2364622078 "Stationary Inverter to Bus Sync Check Status";
CM_ SG_ 2364622078 StationaryInverterToBusDeadBus "Stationary Inverter to Bus Dead Bus: Indicator of whether the bus is considered dead for closing to the stationary inverter. This indicator will be based on parameters such as bus voltage and dead bus threshold values.For stationary non-vehicular app...";
CM_ SG_ 2364622078 SttnrInvrtrTBsPhsMth "Stationary Inverter to Bus Phase Match: Indicator of whether phase difference between the stationary inverter and the bus is adequate for paralleling.For stationary non-vehicular applications of inverters.00b = Phases do not match01b = Phases match10...";
CM_ SG_ 2364622078 SttnrInvrtrTBsFrqnMth "Stationary Inverter to Bus Frequency Match: Indicator of whether the frequency difference between the stationary inverter and the bus is adequate for paralleling.For stationary non-vehicular applications of inverters.00b = Frequencies do not match01b...";
CM_ SG_ 2364622078 SttnrInvrtrTBsVltgMth "Stationary Inverter to Bus Voltage Match: Indicator of whether the voltage difference the stationary inverter and the bus is adequate for paralleling.For stationary non-vehicular applications of inverters.00b = Voltages do not match01b = Voltages mat...";
CM_ SG_ 2364622078 StationaryInverterToBusInSync "Stationary Inverter to Bus In Sync: Indicator of whether the stationary inverter and the bus are properly synchronized for paralleling.  This indicator will be based on parameters such as Voltage Match, Frequency Match, and Phase Match.For stationary...";
CM_ SG_ 2364622078 SttnrInvrtrTBsAPhsDffrn "Stationary Inverter to Bus AC Phase Difference: The phase difference between the stationary inverter and the bus voltage.  For stationary non-vehicular applications of inverters.";
CM_ BO_ 2364622334 "Engine Cylinder 1 Combustion Pressures";
CM_ SG_ 2364622334 EngineCylinder1Timing1Pressure "Engine Cylinder 1 Timing 1 Pressure: In-cylinder pressure for Cylinder #1 at user-defined timing location #1 as per SPN 9845.  Will report FB00h (64256) when engine is not running.";
CM_ SG_ 2364622334 EngineCylinder1Timing2Pressure "Engine Cylinder 1 Timing 2 Pressure: In-cylinder pressure for Cylinder #1 at user-defined timing location #2 as per SPN 9846.  Will report FB00h (64256) when engine is not running.";
CM_ SG_ 2364622334 EngineCylinder1Timing3Pressure "Engine Cylinder 1 Timing 3 Pressure: In-cylinder pressure for Cylinder #1 at user-defined timing location #3 as per SPN 9847.  Will report FB00h (64256) when engine is not running.";
CM_ SG_ 2364622334 EngineCylinder1Timing4Pressure "Engine Cylinder 1 Timing 4 Pressure: In-cylinder pressure for Cylinder #1 at user-defined timing location #4 as per SPN 9848.  Will report FB00h (64256) when engine is not running.";
CM_ BO_ 2364622590 "Engine Cylinder 2 Combustion Pressures";
CM_ SG_ 2364622590 EngineCylinder2Timing1Pressure "Engine Cylinder 2 Timing 1 Pressure: In-cylinder pressure for Cylinder #2 at user-defined timing location #1 as per SPN 9845.  Will report FB00h (64256) when engine is not running.";
CM_ SG_ 2364622590 EngineCylinder2Timing2Pressure "Engine Cylinder 2 Timing 2 Pressure: In-cylinder pressure for Cylinder #2 at user-defined timing location #2 as per SPN 9846.  Will report FB00h (64256) when engine is not running.";
CM_ SG_ 2364622590 EngineCylinder2Timing3Pressure "Engine Cylinder 2 Timing 3 Pressure: In-cylinder pressure for Cylinder #2 at user-defined timing location #3 as per SPN 9847.  Will report FB00h (64256) when engine is not running.";
CM_ SG_ 2364622590 EngineCylinder2Timing4Pressure "Engine Cylinder 2 Timing 4 Pressure: In-cylinder pressure for Cylinder #2 at user-defined timing location #4 as per SPN 9848.  Will report FB00h (64256) when engine is not running.";
CM_ BO_ 2364622846 "Engine Cylinder 3 Combustion Pressures";
CM_ SG_ 2364622846 EngineCylinder3Timing1Pressure "Engine Cylinder 3 Timing 1 Pressure: In-cylinder pressure for Cylinder #3 at user-defined timing location #1 as per SPN 9845.  Will report FB00h (64256) when engine is not running.";
CM_ SG_ 2364622846 EngineCylinder3Timing2Pressure "Engine Cylinder 3 Timing 2 Pressure: In-cylinder pressure for Cylinder #3 at user-defined timing location #2 as per SPN 9846.  Will report FB00h (64256) when engine is not running.";
CM_ SG_ 2364622846 EngineCylinder3Timing3Pressure "Engine Cylinder 3 Timing 3 Pressure: In-cylinder pressure for Cylinder #3 at user-defined timing location #3 as per SPN 9847.  Will report FB00h (64256) when engine is not running.";
CM_ SG_ 2364622846 EngineCylinder3Timing4Pressure "Engine Cylinder 3 Timing 4 Pressure: In-cylinder pressure for Cylinder #3 at user-defined timing location #4 as per SPN 9848.  Will report FB00h (64256) when engine is not running.";
CM_ BO_ 2364623102 "Engine Cylinder 4 Combustion Pressures";
CM_ SG_ 2364623102 EngineCylinder4Timing1Pressure "Engine Cylinder 4 Timing 1 Pressure: In-cylinder pressure for Cylinder #4 at user-defined timing location #1 as per SPN 9845.  Will report FB00h (64256) when engine is not running.";
CM_ SG_ 2364623102 EngineCylinder4Timing2Pressure "Engine Cylinder 4 Timing 2 Pressure: In-cylinder pressure for Cylinder #4 at user-defined timing location #2 as per SPN 9846.  Will report FB00h (64256) when engine is not running.";
CM_ SG_ 2364623102 EngineCylinder4Timing3Pressure "Engine Cylinder 4 Timing 3 Pressure: In-cylinder pressure for Cylinder #4 at user-defined timing location #3 as per SPN 9847.  Will report FB00h (64256) when engine is not running.";
CM_ SG_ 2364623102 EngineCylinder4Timing4Pressure "Engine Cylinder 4 Timing 4 Pressure: In-cylinder pressure for Cylinder #4 at user-defined timing location #4 as per SPN 9848.  Will report FB00h (64256) when engine is not running.";
CM_ BO_ 2364623358 "Engine Cylinder 5 Combustion Pressures";
CM_ SG_ 2364623358 EngineCylinder5Timing1Pressure "Engine Cylinder 5 Timing 1 Pressure: In-cylinder pressure for Cylinder #5 at user-defined timing location #1 as per SPN 9845.  Will report FB00h (64256) when engine is not running.";
CM_ SG_ 2364623358 EngineCylinder5Timing2Pressure "Engine Cylinder 5 Timing 2 Pressure: In-cylinder pressure for Cylinder #5 at user-defined timing location #2 as per SPN 9846.  Will report FB00h (64256) when engine is not running.";
CM_ SG_ 2364623358 EngineCylinder5Timing3Pressure "Engine Cylinder 5 Timing 3 Pressure: In-cylinder pressure for Cylinder #5 at user-defined timing location #3 as per SPN 9847.  Will report FB00h (64256) when engine is not running.";
CM_ SG_ 2364623358 EngineCylinder5Timing4Pressure "Engine Cylinder 5 Timing 4 Pressure: In-cylinder pressure for Cylinder #5 at user-defined timing location #4 as per SPN 9848.  Will report FB00h (64256) when engine is not running.";
CM_ BO_ 2364623614 "Engine Cylinder 6 Combustion Pressures";
CM_ SG_ 2364623614 EngineCylinder6Timing1Pressure "Engine Cylinder 6 Timing 1 Pressure: In-cylinder pressure for Cylinder #6 at user-defined timing location #1 as per SPN 9845.  Will report FB00h (64256) when engine is not running.";
CM_ SG_ 2364623614 EngineCylinder6Timing2Pressure "Engine Cylinder 6 Timing 2 Pressure: In-cylinder pressure for Cylinder #6 at user-defined timing location #2 as per SPN 9846.  Will report FB00h (64256) when engine is not running.";
CM_ SG_ 2364623614 EngineCylinder6Timing3Pressure "Engine Cylinder 6 Timing 3 Pressure: In-cylinder pressure for Cylinder #6 at user-defined timing location #3 as per SPN 9847.  Will report FB00h (64256) when engine is not running.";
CM_ SG_ 2364623614 EngineCylinder6Timing4Pressure "Engine Cylinder 6 Timing 4 Pressure: In-cylinder pressure for Cylinder #6 at user-defined timing location #4 as per SPN 9848.  Will report FB00h (64256) when engine is not running.";
CM_ BO_ 2364623870 "Engine Cylinder 7 Combustion Pressures";
CM_ SG_ 2364623870 EngineCylinder7Timing1Pressure "Engine Cylinder 7 Timing 1 Pressure: In-cylinder pressure for Cylinder #7 at user-defined timing location #1 as per SPN 9845.  Will report FB00h (64256) when engine is not running.";
CM_ SG_ 2364623870 EngineCylinder7Timing2Pressure "Engine Cylinder 7 Timing 2 Pressure: In-cylinder pressure for Cylinder #7 at user-defined timing location #2 as per SPN 9846.  Will report FB00h (64256) when engine is not running.";
CM_ SG_ 2364623870 EngineCylinder7Timing3Pressure "Engine Cylinder 7 Timing 3 Pressure: In-cylinder pressure for Cylinder #7 at user-defined timing location #3 as per SPN 9847.  Will report FB00h (64256) when engine is not running.";
CM_ SG_ 2364623870 EngineCylinder7Timing4Pressure "Engine Cylinder 7 Timing 4 Pressure: In-cylinder pressure for Cylinder #7 at user-defined timing location #4 as per SPN 9848.  Will report FB00h (64256) when engine is not running.";
CM_ BO_ 2364624126 "Engine Cylinder 8 Combustion Pressures";
CM_ SG_ 2364624126 EngineCylinder8Timing1Pressure "Engine Cylinder 8 Timing 1 Pressure: In-cylinder pressure for Cylinder #8 at user-defined timing location #1 as per SPN 9845.  Will report FB00h (64256) when engine is not running.";
CM_ SG_ 2364624126 EngineCylinder8Timing2Pressure "Engine Cylinder 8 Timing 2 Pressure: In-cylinder pressure for Cylinder #8 at user-defined timing location #2 as per SPN 9846.  Will report FB00h (64256) when engine is not running.";
CM_ SG_ 2364624126 EngineCylinder8Timing3Pressure "Engine Cylinder 8 Timing 3 Pressure: In-cylinder pressure for Cylinder #8 at user-defined timing location #3 as per SPN 9847.  Will report FB00h (64256) when engine is not running.";
CM_ SG_ 2364624126 EngineCylinder8Timing4Pressure "Engine Cylinder 8 Timing 4 Pressure: In-cylinder pressure for Cylinder #8 at user-defined timing location #4 as per SPN 9848.  Will report FB00h (64256) when engine is not running.";
CM_ BO_ 2364624382 "Engine Cylinder 9 Combustion Pressures";
CM_ SG_ 2364624382 EngineCylinder9Timing1Pressure "Engine Cylinder 9 Timing 1 Pressure: In-cylinder pressure for Cylinder #9 at user-defined timing location #1 as per SPN 9845.  Will report FB00h (64256) when engine is not running.";
CM_ SG_ 2364624382 EngineCylinder9Timing2Pressure "Engine Cylinder 9 Timing 2 Pressure: In-cylinder pressure for Cylinder #9 at user-defined timing location #2 as per SPN 9846.  Will report FB00h (64256) when engine is not running.";
CM_ SG_ 2364624382 EngineCylinder9Timing3Pressure "Engine Cylinder 9 Timing 3 Pressure: In-cylinder pressure for Cylinder #9 at user-defined timing location #3 as per SPN 9847.  Will report FB00h (64256) when engine is not running.";
CM_ SG_ 2364624382 EngineCylinder9Timing4Pressure "Engine Cylinder 9 Timing 4 Pressure: In-cylinder pressure for Cylinder #9 at user-defined timing location #4 as per SPN 9848.  Will report FB00h (64256) when engine is not running.";
CM_ BO_ 2364624638 "Engine Cylinder 10 Combustion Pressures";
CM_ SG_ 2364624638 EngineCylinder10Timing1Pressure "Engine Cylinder 10 Timing 1 Pressure: In-cylinder pressure for Cylinder #10 at user-defined timing location #1 as per SPN 9845.  Will report FB00h (64256) when engine is not running.";
CM_ SG_ 2364624638 EngineCylinder10Timing2Pressure "Engine Cylinder 10 Timing 2 Pressure: In-cylinder pressure for Cylinder #10 at user-defined timing location #2 as per SPN 9846.  Will report FB00h (64256) when engine is not running.";
CM_ SG_ 2364624638 EngineCylinder10Timing3Pressure "Engine Cylinder 10 Timing 3 Pressure: In-cylinder pressure for Cylinder #10 at user-defined timing location #3 as per SPN 9847.  Will report FB00h (64256) when engine is not running.";
CM_ SG_ 2364624638 EngineCylinder10Timing4Pressure "Engine Cylinder 10 Timing 4 Pressure: In-cylinder pressure for Cylinder #10 at user-defined timing location #4 as per SPN 9848.  Will report FB00h (64256) when engine is not running.";
CM_ BO_ 2364624894 "Engine Cylinder 11 Combustion Pressures";
CM_ SG_ 2364624894 EngineCylinder11Timing1Pressure "Engine Cylinder 11 Timing 1 Pressure: In-cylinder pressure for Cylinder #11 at user-defined timing location #1 as per SPN 9845.  Will report FB00h (64256) when engine is not running.";
CM_ SG_ 2364624894 EngineCylinder11Timing2Pressure "Engine Cylinder 11 Timing 2 Pressure: In-cylinder pressure for Cylinder #11 at user-defined timing location #2 as per SPN 9846.  Will report FB00h (64256) when engine is not running.";
CM_ SG_ 2364624894 EngineCylinder11Timing3Pressure "Engine Cylinder 11 Timing 3 Pressure: In-cylinder pressure for Cylinder #11 at user-defined timing location #3 as per SPN 9847.  Will report FB00h (64256) when engine is not running.";
CM_ SG_ 2364624894 EngineCylinder11Timing4Pressure "Engine Cylinder 11 Timing 4 Pressure: In-cylinder pressure for Cylinder #11 at user-defined timing location #4 as per SPN 9848.  Will report FB00h (64256) when engine is not running.";
CM_ BO_ 2364625150 "Engine Cylinder 12 Combustion Pressures";
CM_ SG_ 2364625150 EngineCylinder12Timing1Pressure "Engine Cylinder 12 Timing 1 Pressure: In-cylinder pressure for Cylinder #12 at user-defined timing location #1 as per SPN 9845.  Will report FB00h (64256) when engine is not running.";
CM_ SG_ 2364625150 EngineCylinder12Timing2Pressure "Engine Cylinder 12 Timing 2 Pressure: In-cylinder pressure for Cylinder #12 at user-defined timing location #2 as per SPN 9846.  Will report FB00h (64256) when engine is not running.";
CM_ SG_ 2364625150 EngineCylinder12Timing3Pressure "Engine Cylinder 12 Timing 3 Pressure: In-cylinder pressure for Cylinder #12 at user-defined timing location #3 as per SPN 9847.  Will report FB00h (64256) when engine is not running.";
CM_ SG_ 2364625150 EngineCylinder12Timing4Pressure "Engine Cylinder 12 Timing 4 Pressure: In-cylinder pressure for Cylinder #12 at user-defined timing location #4 as per SPN 9848.  Will report FB00h (64256) when engine is not running.";
CM_ BO_ 2364625406 "Engine Cylinder 13 Combustion Pressures";
CM_ SG_ 2364625406 EngineCylinder13Timing1Pressure "Engine Cylinder 13 Timing 1 Pressure: In-cylinder pressure for Cylinder #13 at user-defined timing location #1 as per SPN 9845.  Will report FB00h (64256) when engine is not running.";
CM_ SG_ 2364625406 EngineCylinder13Timing2Pressure "Engine Cylinder 13 Timing 2 Pressure: In-cylinder pressure for Cylinder #13 at user-defined timing location #2 as per SPN 9846.  Will report FB00h (64256) when engine is not running.";
CM_ SG_ 2364625406 EngineCylinder13Timing3Pressure "Engine Cylinder 13 Timing 3 Pressure: In-cylinder pressure for Cylinder #13 at user-defined timing location #3 as per SPN 9847.  Will report FB00h (64256) when engine is not running.";
CM_ SG_ 2364625406 EngineCylinder13Timing4Pressure "Engine Cylinder 13 Timing 4 Pressure: In-cylinder pressure for Cylinder #13 at user-defined timing location #4 as per SPN 9848.  Will report FB00h (64256) when engine is not running.";
CM_ BO_ 2364625662 "Engine Cylinder 14 Combustion Pressures";
CM_ SG_ 2364625662 EngineCylinder14Timing1Pressure "Engine Cylinder 14 Timing 1 Pressure: In-cylinder pressure for Cylinder #14 at user-defined timing location #1 as per SPN 9845.  Will report FB00h (64256) when engine is not running.";
CM_ SG_ 2364625662 EngineCylinder14Timing2Pressure "Engine Cylinder 14 Timing 2 Pressure: In-cylinder pressure for Cylinder #14 at user-defined timing location #2 as per SPN 9846.  Will report FB00h (64256) when engine is not running.";
CM_ SG_ 2364625662 EngineCylinder14Timing3Pressure "Engine Cylinder 14 Timing 3 Pressure: In-cylinder pressure for Cylinder #14 at user-defined timing location #3 as per SPN 9847.  Will report FB00h (64256) when engine is not running.";
CM_ SG_ 2364625662 EngineCylinder14Timing4Pressure "Engine Cylinder 14 Timing 4 Pressure: In-cylinder pressure for Cylinder #14 at user-defined timing location #4 as per SPN 9848.  Will report FB00h (64256) when engine is not running.";
CM_ BO_ 2364625918 "Engine Cylinder 15 Combustion Pressures";
CM_ SG_ 2364625918 EngineCylinder15Timing1Pressure "Engine Cylinder 15 Timing 1 Pressure: In-cylinder pressure for Cylinder #15 at user-defined timing location #1 as per SPN 9845.  Will report FB00h (64256) when engine is not running.";
CM_ SG_ 2364625918 EngineCylinder15Timing2Pressure "Engine Cylinder 15 Timing 2 Pressure: In-cylinder pressure for Cylinder #15 at user-defined timing location #2 as per SPN 9846.  Will report FB00h (64256) when engine is not running.";
CM_ SG_ 2364625918 EngineCylinder15Timing3Pressure "Engine Cylinder 15 Timing 3 Pressure: In-cylinder pressure for Cylinder #15 at user-defined timing location #3 as per SPN 9847.  Will report FB00h (64256) when engine is not running.";
CM_ SG_ 2364625918 EngineCylinder15Timing4Pressure "Engine Cylinder 15 Timing 4 Pressure: In-cylinder pressure for Cylinder #15 at user-defined timing location #4 as per SPN 9848.  Will report FB00h (64256) when engine is not running.";
CM_ BO_ 2364626174 "Engine Cylinder 16 Combustion Pressures";
CM_ SG_ 2364626174 EngineCylinder16Timing1Pressure "Engine Cylinder 16 Timing 1 Pressure: In-cylinder pressure for Cylinder #16 at user-defined timing location #1 as per SPN 9845.  Will report FB00h (64256) when engine is not running.";
CM_ SG_ 2364626174 EngineCylinder16Timing2Pressure "Engine Cylinder 16 Timing 2 Pressure: In-cylinder pressure for Cylinder #16 at user-defined timing location #2 as per SPN 9846.  Will report FB00h (64256) when engine is not running.";
CM_ SG_ 2364626174 EngineCylinder16Timing3Pressure "Engine Cylinder 16 Timing 3 Pressure: In-cylinder pressure for Cylinder #16 at user-defined timing location #3 as per SPN 9847.  Will report FB00h (64256) when engine is not running.";
CM_ SG_ 2364626174 EngineCylinder16Timing4Pressure "Engine Cylinder 16 Timing 4 Pressure: In-cylinder pressure for Cylinder #16 at user-defined timing location #4 as per SPN 9848.  Will report FB00h (64256) when engine is not running.";
BA_DEF_ SG_  "SPN" INT 0 524287;
BA_DEF_ BO_  "VFrameFormat" ENUM  "StandardCAN","ExtendedCAN","reserved","J1939PG";
BA_DEF_DEF_  "SPN" 0;
BA_DEF_DEF_  "VFrameFormat" "J1939PG";
BA_ "SPN" SG_ 2633924094 EngineCylinder10CombustionTime 1453;
BA_ "SPN" SG_ 2633924094 EngineCylinder11CombustionTime 1454;
BA_ "SPN" SG_ 2633924094 EngineCylinder12CombustionTime 1455;
BA_ "SPN" SG_ 2633924094 EngineCylinder9CombustionTime 1452;
BA_ "SPN" SG_ 2633924350 EngineCylinder13CombustionTime 1456;
BA_ "SPN" SG_ 2633924350 EngineCylinder14CombustionTime 1457;
BA_ "SPN" SG_ 2633924350 EngineCylinder15CombustionTime 1458;
BA_ "SPN" SG_ 2633924350 EngineCylinder16CombustionTime 1459;
BA_ "SPN" SG_ 2633924606 EngineCylinder17CombustionTime 1460;
BA_ "SPN" SG_ 2633924606 EngineCylinder18CombustionTime 1461;
BA_ "SPN" SG_ 2633924606 EngineCylinder19CombustionTime 1462;
BA_ "SPN" SG_ 2633924606 EngineCylinder20CombustionTime 1463;
BA_ "SPN" SG_ 2633924862 EngineAverageCombustionTime 1465;
BA_ "SPN" SG_ 2633924862 EngineDesiredCombustionTime 1464;
BA_ "SPN" SG_ 2633925118 EngineFuelFlowRate1 1440;
BA_ "SPN" SG_ 2633925118 EngineFuelFlowRate2 1441;
BA_ "SPN" SG_ 2633925118 EngineFuelValve1Position 1442;
BA_ "SPN" SG_ 2633925118 EngineFuelValve2Position 1443;
BA_ "SPN" SG_ 2633925118 EngnFlVlv1CmmnddPstn 1765;
BA_ "SPN" SG_ 2633925118 EngnFlVlv2CmmnddPstn 1766;
BA_ "SPN" SG_ 2633925374 EngineCylinder1IgnitionTiming 1413;
BA_ "SPN" SG_ 2633925374 EngineCylinder2IgnitionTiming 1414;
BA_ "SPN" SG_ 2633925374 EngineCylinder3IgnitionTiming 1415;
BA_ "SPN" SG_ 2633925374 EngineCylinder4IgnitionTiming 1416;
BA_ "SPN" SG_ 2633925630 EngineCylinder5IgnitionTiming 1417;
BA_ "SPN" SG_ 2633925630 EngineCylinder6IgnitionTiming 1418;
BA_ "SPN" SG_ 2633925630 EngineCylinder7IgnitionTiming 1419;
BA_ "SPN" SG_ 2633925630 EngineCylinder8IgnitionTiming 1420;
BA_ "SPN" SG_ 2633925886 EngineCylinder10IgnitionTiming 1422;
BA_ "SPN" SG_ 2633925886 EngineCylinder11IgnitionTiming 1423;
BA_ "SPN" SG_ 2633925886 EngineCylinder12IgnitionTiming 1424;
BA_ "SPN" SG_ 2633925886 EngineCylinder9IgnitionTiming 1421;
BA_ "SPN" SG_ 2633926142 EngineCylinder13IgnitionTiming 1425;
BA_ "SPN" SG_ 2633926142 EngineCylinder14IgnitionTiming 1426;
BA_ "SPN" SG_ 2633926142 EngineCylinder15IgnitionTiming 1427;
BA_ "SPN" SG_ 2633926142 EngineCylinder16IgnitionTiming 1428;
BA_ "SPN" SG_ 2633926398 EngineCylinder17IgnitionTiming 1429;
BA_ "SPN" SG_ 2633926398 EngineCylinder18IgnitionTiming 1430;
BA_ "SPN" SG_ 2633926398 EngineCylinder19IgnitionTiming 1431;
BA_ "SPN" SG_ 2633926398 EngineCylinder20IgnitionTiming 1432;
BA_ "SPN" SG_ 2633926654 EngineActualIgnitionTiming 1436;
BA_ "SPN" SG_ 2633926654 EngineDesiredIgnitionTiming1 1433;
BA_ "SPN" SG_ 2633926654 EngineDesiredIgnitionTiming2 1434;
BA_ "SPN" SG_ 2633926654 EngineDesiredIgnitionTiming3 1435;
BA_ "SPN" SG_ 2633926910 EngnClndr1IgntnTrnsfrmrSndrOtpt 1393;
BA_ "SPN" SG_ 2633926910 EngnClndr2IgntnTrnsfrmrSndrOtpt 1394;
BA_ "SPN" SG_ 2633926910 EngnClndr3IgntnTrnsfrmrSndrOtpt 1395;
BA_ "SPN" SG_ 2633926910 EngnClndr4IgntnTrnsfrmrSndrOtpt 1396;
BA_ "SPN" SG_ 2633926910 EngnClndr5IgntnTrnsfrmrSndrOtpt 1397;
BA_ "SPN" SG_ 2633926910 EngnClndr6IgntnTrnsfrmrSndrOtpt 1398;
BA_ "SPN" SG_ 2633926910 EngnClndr7IgntnTrnsfrmrSndrOtpt 1399;
BA_ "SPN" SG_ 2633926910 EngnClndr8IgntnTrnsfrmrSndrOtpt 1400;
BA_ "SPN" SG_ 2633927166 ECd10ItTsSdOtpt 1402;
BA_ "SPN" SG_ 2633927166 ECd11ItTsSdOtpt 1403;
BA_ "SPN" SG_ 2633927166 ECd12ItTsSdOtpt 1404;
BA_ "SPN" SG_ 2633927166 ECd13ItTsSdOtpt 1405;
BA_ "SPN" SG_ 2633927166 ECd14ItTsSdOtpt 1406;
BA_ "SPN" SG_ 2633927166 ECd15ItTsSdOtpt 1407;
BA_ "SPN" SG_ 2633927166 ECd16ItTsSdOtpt 1408;
BA_ "SPN" SG_ 2633927166 EngnClndr9IgntnTrnsfrmrSndrOtpt 1401;
BA_ "SPN" SG_ 2633927422 ECd17ItTsSdOtpt 1409;
BA_ "SPN" SG_ 2633927422 ECd18ItTsSdOtpt 1410;
BA_ "SPN" SG_ 2633927422 ECd19ItTsSdOtpt 1411;
BA_ "SPN" SG_ 2633927422 ECd20ItTsSdOtpt 1412;
BA_ "SPN" SG_ 2633927678 EngnArTFlDffrntlPrssr 1392;
BA_ "SPN" SG_ 2633927678 EngnFlVlv1DffrntlPrssr 1391;
BA_ "SPN" SG_ 2633927678 EngnFlVlv1IntkAsltPrssr 1390;
BA_ "SPN" SG_ 2633927678 EngnFlVlv1OtltAsltPrssr 2980;
BA_ "SPN" SG_ 2633927934 AuxiliaryLevel 3087;
BA_ "SPN" SG_ 2633927934 AuxiliaryPressure1 1387;
BA_ "SPN" SG_ 2633927934 AuxiliaryPressure2 1388;
BA_ "SPN" SG_ 2633927934 AuxiliaryTemperature1 441;
BA_ "SPN" SG_ 2633927934 AuxiliaryTemperature2 442;
BA_ "SPN" SG_ 2633927934 RelativeHumidity 354;
BA_ "SPN" SG_ 2633927934 AuxiliaryTemperature3 21161;
BA_ "SPN" SG_ 2633928446 ServiceComponentIdentification 1379;
BA_ "SPN" SG_ 2633928446 TimeSinceLastService 1350;
BA_ "SPN" SG_ 2633929214 EngineFluidBundLevel 7785;
BA_ "SPN" SG_ 2633929214 EngineFuelLeakage1 1239;
BA_ "SPN" SG_ 2633929214 EngineFuelLeakage2 1240;
BA_ "SPN" SG_ 2633929470 EngineFuelRackPosition 1210;
BA_ "SPN" SG_ 2633929470 EngineOilFilterIntakePressure 1208;
BA_ "SPN" SG_ 2633929470 EngnFlSstm1GsMssFlwRt 1241;
BA_ "SPN" SG_ 2633929470 InstntnsEstmtdBrkPwr 1242;
BA_ "SPN" SG_ 2633929470 EngineExhaustBank1Pressure1 1209;
BA_ "SPN" SG_ 2633929726 ElectricalLoad 1204;
BA_ "SPN" SG_ 2633929726 EngineTurningGearEngaged 1206;
BA_ "SPN" SG_ 2633929726 SafetyWireStatus 1205;
BA_ "SPN" SG_ 2633930238 EngineOperationTimeSinceRebuild 1193;
BA_ "SPN" SG_ 2633931774 EngineTurbocharger2Speed 1169;
BA_ "SPN" SG_ 2633931774 EngineTurbocharger3Speed 1170;
BA_ "SPN" SG_ 2633931774 EngineTurbocharger4Speed 1171;
BA_ "SPN" SG_ 2633931774 EngnTrhrgrLOlPrssr2 1168;
BA_ "SPN" SG_ 2633932798 EngnExhstGsPrt17Tmprtr 1153;
BA_ "SPN" SG_ 2633932798 EngnExhstGsPrt18Tmprtr 1154;
BA_ "SPN" SG_ 2633932798 EngnExhstGsPrt19Tmprtr 1155;
BA_ "SPN" SG_ 2633932798 EngnExhstGsPrt20Tmprtr 1156;
BA_ "SPN" SG_ 2633933310 EngnExhstGsPrt10Tmprtr 1146;
BA_ "SPN" SG_ 2633933310 EngnExhstGsPrt11Tmprtr 1147;
BA_ "SPN" SG_ 2633933310 EngnExhstGsPrt12Tmprtr 1148;
BA_ "SPN" SG_ 2633933310 EngnExhstGsPrt9Tmprtr 1145;
BA_ "SPN" SG_ 2633933566 EngnExhstGsPrt5Tmprtr 1141;
BA_ "SPN" SG_ 2633933566 EngnExhstGsPrt6Tmprtr 1142;
BA_ "SPN" SG_ 2633933566 EngnExhstGsPrt7Tmprtr 1143;
BA_ "SPN" SG_ 2633933566 EngnExhstGsPrt8Tmprtr 1144;
BA_ "SPN" SG_ 2633933822 EngnExhstGsPrt1Tmprtr 1137;
BA_ "SPN" SG_ 2633933822 EngnExhstGsPrt2Tmprtr 1138;
BA_ "SPN" SG_ 2633933822 EngnExhstGsPrt3Tmprtr 1139;
BA_ "SPN" SG_ 2633933822 EngnExhstGsPrt4Tmprtr 1140;
BA_ "SPN" SG_ 2633934334 EngnIntkMnfld2Tmprtr 1131;
BA_ "SPN" SG_ 2633934334 EngnIntkMnfld3Tmprtr 1132;
BA_ "SPN" SG_ 2633934334 EngnIntkMnfld4Tmprtr 1133;
BA_ "SPN" SG_ 2633934334 EngnIntkMnfld5Tmprtr 1802;
BA_ "SPN" SG_ 2633934334 EngnIntkMnfld6Tmprtr 1803;
BA_ "SPN" SG_ 2633934334 DsrdEngnIntkMnfldTmprtr 12304;
BA_ "SPN" SG_ 2633934334 DsrdEngnIntkMnfldTmprtrHghLmt 12305;
BA_ "SPN" SG_ 2633934846 EngnAltrntrBrng1Tmprtr 1122;
BA_ "SPN" SG_ 2633934846 EngnAltrntrBrng2Tmprtr 1123;
BA_ "SPN" SG_ 2633934846 EngnAltrntrWndng1Tmprtr 1124;
BA_ "SPN" SG_ 2633934846 EngnAltrntrWndng2Tmprtr 1125;
BA_ "SPN" SG_ 2633934846 EngnAltrntrWndng3Tmprtr 1126;
BA_ "SPN" SG_ 2633934846 EngnAltrntrWndng4Tmprtr 8463;
BA_ "SPN" SG_ 2633934846 EngnAltrntrWndng5Tmprtr 8464;
BA_ "SPN" SG_ 2633934846 EngnAltrntrWndng6Tmprtr 8465;
BA_ "SPN" SG_ 2633935102 ArticulationAngle 1120;
BA_ "SPN" SG_ 2633935102 ArticulationAngularVelocity 9652;
BA_ "SPN" SG_ 2633935358 EngineActualExhaust1Oxygen 1119;
BA_ "SPN" SG_ 2633935358 EngineDesiredExhaustOxygen 1118;
BA_ "SPN" SG_ 2633935358 EngineDesiredRatedExhaustOxygen 1117;
BA_ "SPN" SG_ 2633935358 EngnExhstO2SnsrClsdLpOprtn 1696;
BA_ "SPN" SG_ 2633935358 EngnExhstO2SnsrFlngCrrtn 1695;
BA_ "SPN" SG_ 2633935614 EFSstGsMssFwRtSsFCt 1694;
BA_ "SPN" SG_ 2633935614 EngnIntkMnfldDsrdAsltPrssr 1692;
BA_ "SPN" SG_ 2633935614 EngnTrhrgrWstgtVlvPstn 1693;
BA_ "SPN" SG_ 2633935614 GaseousFuelCorrectionFactor 1116;
BA_ "SPN" SG_ 2633935614 GssFlInjtnPlsCrrtnFtr 6649;
BA_ "SPN" SG_ 2633935870 ClutchLifeRemaining 2983;
BA_ "SPN" SG_ 2633935870 HighestPossibleGear 1115;
BA_ "SPN" SG_ 2633935870 LowestPossibleGear 1114;
BA_ "SPN" SG_ 2633935870 RecommendedGear 1113;
BA_ "SPN" SG_ 2633936126 BrkLnngRmnngFrntAxlLftWhl 1099;
BA_ "SPN" SG_ 2633936126 BrkLnngRmnngFrntAxlRghtWhl 1100;
BA_ "SPN" SG_ 2633936126 BrkLnngRmnngRrAxl1LftWhl 1101;
BA_ "SPN" SG_ 2633936126 BrkLnngRmnngRrAxl1RghtWhl 1102;
BA_ "SPN" SG_ 2633936126 BrkLnngRmnngRrAxl2LftWhl 1103;
BA_ "SPN" SG_ 2633936126 BrkLnngRmnngRrAxl2RghtWhl 1104;
BA_ "SPN" SG_ 2633936126 BrkLnngRmnngRrAxl3LftWhl 1105;
BA_ "SPN" SG_ 2633936126 BrkLnngRmnngRrAxl3RghtWhl 1106;
BA_ "SPN" SG_ 2633936894 TotalFuelUsedGaseous 1040;
BA_ "SPN" SG_ 2633936894 TripFuelGaseous 1039;
BA_ "SPN" SG_ 2633937150 TripAirCompressorOnTime 1038;
BA_ "SPN" SG_ 2633937150 TripCruiseTime 1034;
BA_ "SPN" SG_ 2633937150 TripEngineRunningTime 1036;
BA_ "SPN" SG_ 2633937150 TripIdleTime 1037;
BA_ "SPN" SG_ 2633937150 TripPtoGovernorTime 1035;
BA_ "SPN" SG_ 2633937406 TotalEcuDistance 1032;
BA_ "SPN" SG_ 2633937406 TotalEcuRunTime 1033;
BA_ "SPN" SG_ 2633937662 EngineFuelSpecificGravity 1389;
BA_ "SPN" SG_ 2633937662 TripAverageFuelRateGaseous 1031;
BA_ "SPN" SG_ 2633937662 TtlEngnPtGvrnrFlUsdGss 1030;
BA_ "SPN" SG_ 2633937918 FlexibleFuelPercentage 5458;
BA_ "SPN" SG_ 2633937918 TotalEnginePtoGovernorFuelUsed 1028;
BA_ "SPN" SG_ 2633937918 TripAverageFuelRate 1029;
BA_ "SPN" SG_ 2633938174 TripTimeInDerateByEngine 1027;
BA_ "SPN" SG_ 2633938174 TripTimeInGearDown 1026;
BA_ "SPN" SG_ 2633938174 TripTimeInTopGear 1025;
BA_ "SPN" SG_ 2633938174 TripTimeInVsl 1024;
BA_ "SPN" SG_ 2633938430 TripNumberOfHotShutdowns 1020;
BA_ "SPN" SG_ 2633938430 TripNumberOfIdleShutdowns 1021;
BA_ "SPN" SG_ 2633938430 TripSuddenDecelerations 1023;
BA_ "SPN" SG_ 2633938430 TrpNmrOfIdlShtdwnOvrrds 1022;
BA_ "SPN" SG_ 2633938686 TripCruiseDistance 1019;
BA_ "SPN" SG_ 2633938686 TripMaximumVehicleSpeed 1018;
BA_ "SPN" SG_ 2633938942 TotalEngineCruiseTime 1017;
BA_ "SPN" SG_ 2633938942 TripAverageEngineSpeed 1014;
BA_ "SPN" SG_ 2633938942 TripMaximumEngineSpeed 1013;
BA_ "SPN" SG_ 2633938942 TripDriveAverageLoadFactor 1015;
BA_ "SPN" SG_ 2633938942 TotalDriveAverageLoadFactor 1016;
BA_ "SPN" SG_ 2633939198 TripCruiseFuelUsedGaseous 1011;
BA_ "SPN" SG_ 2633939198 TripDriveFuelEconomyGaseous 1012;
BA_ "SPN" SG_ 2633939198 TripDriveFuelUsedGaseous 1007;
BA_ "SPN" SG_ 2633939198 TripVehicleIdleFuelUsedGaseous 1010;
BA_ "SPN" SG_ 2633939198 TrpPtGvrnrMvngFlUsdGss 1008;
BA_ "SPN" SG_ 2633939198 TrpPtGvrnrNnMvngFlUsdGss 1009;
BA_ "SPN" SG_ 2633939454 TripCruiseFuelUsed 1005;
BA_ "SPN" SG_ 2633939454 TripDriveFuelEconomy 1006;
BA_ "SPN" SG_ 2633939454 TripDriveFuelUsed 1001;
BA_ "SPN" SG_ 2633939454 TripPtoGovernorMovingFuelUsed 1002;
BA_ "SPN" SG_ 2633939454 TripVehicleIdleFuelUsed 1004;
BA_ "SPN" SG_ 2633939454 TrpPtGvrnrNnMvngFlUsd 1003;
BA_ "SPN" SG_ 2633939710 TripDistanceInTopGear 1000;
BA_ "SPN" SG_ 2633939710 TripDistanceOnVsl 998;
BA_ "SPN" SG_ 2633939710 TripGearDownDistance 999;
BA_ "SPN" SG_ 2633939966 TripFanOnTime 994;
BA_ "SPN" SG_ 2633939966 TripFanOnTimeDueToAManualSwitch 996;
BA_ "SPN" SG_ 2633939966 TripFanOnTimeDueToTheACSystem 997;
BA_ "SPN" SG_ 2633939966 TrpFnOnTmDTThEngnSstm 995;
BA_ "SPN" SG_ 2633940222 TotalCompressionBrakeDistance 990;
BA_ "SPN" SG_ 2633940222 TripCompressionBrakeDistance 991;
BA_ "SPN" SG_ 2633940222 TripServiceBrakeApplications 993;
BA_ "SPN" SG_ 2633940222 TripServiceBrakeDistance 992;
BA_ "SPN" SG_ 2633940734 EngineRatedPower 166;
BA_ "SPN" SG_ 2633940734 EngineRatedSpeed 189;
BA_ "SPN" SG_ 2633940734 EngineRotationDirection 3669;
BA_ "SPN" SG_ 2633940734 EngnIntkMnfldPrssrCntrlMd 5465;
BA_ "SPN" SG_ 2633940734 EngnPrlOlLwPrssrThrshld 8622;
BA_ "SPN" SG_ 2633940734 CrnkAttmptCntOnPrsntStrtAttmpt 3671;
BA_ "SPN" SG_ 2633941758 CrsCntrlRtrdrAtvSpdOffst 7496;
BA_ "SPN" SG_ 2633941758 TransmissionOutputRetarder 748;
BA_ "SPN" SG_ 2633941758 RetarderRoadSpeedLimitEnable 12990;
BA_ "SPN" SG_ 2633941758 RetarderRoadSpeedLimitActive 12991;
BA_ "SPN" SG_ 2633941758 TrnsmssnRtrdrEnlSwth 4055;
BA_ "SPN" SG_ 2633941758 RetarderRoadSpeedLimitSetSpeed 12992;
BA_ "SPN" SG_ 2633941758 RetarderRoadSpeedLimitReadiness 23059;
BA_ "SPN" SG_ 2633942014 TransmissionLowRangeSenseSwitch 779;
BA_ "SPN" SG_ 2633942014 TransmissionNeutralSwitch 604;
BA_ "SPN" SG_ 2633942014 TrnsmssnFrwrdDrtnSwth 903;
BA_ "SPN" SG_ 2633942014 TrnsmssnHghRngSnsSwth 778;
BA_ "SPN" SG_ 2633942014 TrnsmssnRvrsDrtnSwth 767;
BA_ "SPN" SG_ 2633942014 TransmissionSplitterPosition 32;
BA_ "SPN" SG_ 2633942526 TrnsmssnSnhrnzrBrkVl 54;
BA_ "SPN" SG_ 2633942526 TrnsmssnSnhrnzrClthVl 53;
BA_ "SPN" SG_ 2633943038 TransmissionClutchActuator 788;
BA_ "SPN" SG_ 2633943038 TransmissionDefuelActuator 786;
BA_ "SPN" SG_ 2633943038 TransmissionRangeHighActuator 768;
BA_ "SPN" SG_ 2633943038 TransmissionRangeLowActuator 769;
BA_ "SPN" SG_ 2633943038 TrnsmssnInrtBrkAttr 787;
BA_ "SPN" SG_ 2633943038 TrnsmssnShftFngrCntrRlIndtr 782;
BA_ "SPN" SG_ 2633943038 TrnsmssnShftFngrEnggmntIndtr 781;
BA_ "SPN" SG_ 2633943038 TrnsmssnShftFngrGrAttr1 773;
BA_ "SPN" SG_ 2633943038 TrnsmssnShftFngrGrAttr2 784;
BA_ "SPN" SG_ 2633943038 TrnsmssnShftFngrGrPstn 59;
BA_ "SPN" SG_ 2633943038 TrnsmssnShftFngrNtrlIndtr 780;
BA_ "SPN" SG_ 2633943038 TrnsmssnShftFngrRlAttr1 772;
BA_ "SPN" SG_ 2633943038 TrnsmssnShftFngrRlAttr2 783;
BA_ "SPN" SG_ 2633943038 TrnsmssnShftFngrRlPstn 60;
BA_ "SPN" SG_ 2633943038 TrnsmssnSplttrDrtAttr 770;
BA_ "SPN" SG_ 2633943038 TrnsmssnSplttrIndrtAttr 771;
BA_ "SPN" SG_ 2633943038 TrnsmssnTrqCnvrtrLkpClthAttr 740;
BA_ "SPN" SG_ 2565865726 ActualRetarderPercentTorque 520;
BA_ "SPN" SG_ 2565865726 AtlMxmmAvllRtrdrPrntTrq 1717;
BA_ "SPN" SG_ 2565865726 DrvrsDmndRtrdrPrntTrq 1715;
BA_ "SPN" SG_ 2565865726 EngineCoolantLoadIncrease 1082;
BA_ "SPN" SG_ 2565865726 IntendedRetarderPercentTorque 1085;
BA_ "SPN" SG_ 2565865726 RetarderEnableBrakeAssistSwitch 571;
BA_ "SPN" SG_ 2565865726 RetarderEnableShiftAssistSwitch 572;
BA_ "SPN" SG_ 2565865726 RetarderRequestingBrakeLight 1667;
BA_ "SPN" SG_ 2565865726 RetarderRoadSpeedExceededStatus 4234;
BA_ "SPN" SG_ 2565865726 RetarderRoadSpeedLimitSwitch 4233;
BA_ "SPN" SG_ 2565865726 RetarderSelectionNonEngine 1716;
BA_ "SPN" SG_ 2565865726 RetarderTorqueMode 900;
BA_ "SPN" SG_ 2565865726 SAddssOCtDvFRtdCt 1480;
BA_ "SPN" SG_ 2499608830 EngineCoolantPressure2 5708;
BA_ "SPN" SG_ 2499608830 EngnExhstGsRrltn2DffrntlPrssr 5252;
BA_ "SPN" SG_ 2499608830 EngnExhstGsRrltn2IntkAsltPrssr 5429;
BA_ "SPN" SG_ 2499608830 EngnExhstGsRrltn2IntkPrssr 5253;
BA_ "SPN" SG_ 2499608830 EngnExhstGsRrltn2OtltAsltPrssr 5254;
BA_ "SPN" SG_ 2365456638 GeneratorPhaseBAcFrequency 2438;
BA_ "SPN" SG_ 2365456638 GeneratorPhaseBAcRmsCurrent 2450;
BA_ "SPN" SG_ 2365456638 GnrtrPhsBLnLnARmsVltg 2442;
BA_ "SPN" SG_ 2365456638 GnrtrPhsBLnNtrlARmsVltg 2446;
BA_ "SPN" SG_ 2351365886 MtrGnrtr1InvrtrCntrlCntr 10158;
BA_ "SPN" SG_ 2351365886 MtGt1IvtCtLtsRqstOvdMd 10159;
BA_ "SPN" SG_ 2351365886 MtrGnrtr1InvrtrCntrlStpntMdRqst 10162;
BA_ "SPN" SG_ 2351365886 MtrGnrtr1InvrtrCntrlStpntRqst 10163;
BA_ "SPN" SG_ 2351365886 MtrGnrtr1InvrtrCntrlCr 10157;
BA_ "SPN" SG_ 2351365886 MtGt1IvtCtLtsRqstOvdMx 10160;
BA_ "SPN" SG_ 2351365886 MtGt1IvtCtLtsRqstOvdM 10161;
BA_ "SPN" SG_ 2351431422 MtrGnrtr2InvrtrCntrlCntr 10224;
BA_ "SPN" SG_ 2351431422 MtGt2IvtCtLtsRqstOvdMd 10225;
BA_ "SPN" SG_ 2351431422 MtrGnrtr2InvrtrCntrlStpntMdRqst 10228;
BA_ "SPN" SG_ 2351431422 MtrGnrtr2InvrtrCntrlStpntRqst 10229;
BA_ "SPN" SG_ 2351431422 MtrGnrtr2InvrtrCntrlCr 10223;
BA_ "SPN" SG_ 2351431422 MtGt2IvtCtLtsRqstOvdMx 10226;
BA_ "SPN" SG_ 2351431422 MtGt2IvtCtLtsRqstOvdM 10227;
BA_ "SPN" SG_ 2556165886 MtrGnrtr2InvrtrLmtsRqstPwrCntr 10243;
BA_ "SPN" SG_ 2556165886 MtrGnrtr2InvrtrLmtsRqstPwrCr 10242;
BA_ "SPN" SG_ 2556165886 MtGt2IvtLtsRqstMPwMx 10244;
BA_ "SPN" SG_ 2556165886 MtGt2IvtLtsRqstMPwM 10245;
BA_ "SPN" SG_ 2556165886 MtGt2IvtLtsRqstDSdPwMx 10246;
BA_ "SPN" SG_ 2556165886 MtGt2IvtLtsRqstDSdPwM 10247;
BA_ "SPN" SG_ 2556231422 MtrGnrtr2InvrtrLmtsRqstMhnlCntr 10255;
BA_ "SPN" SG_ 2556231422 MtrGnrtr2InvrtrLmtsRqstMhnlCr 10254;
BA_ "SPN" SG_ 2556231422 MtrGnrtr2InvrtrLmtsRqstTrqMxmm 10256;
BA_ "SPN" SG_ 2556231422 MtrGnrtr2InvrtrLmtsRqstTrqMnmm 10257;
BA_ "SPN" SG_ 2556231422 MtrGnrtr2InvrtrLmtsRqstSpdMxmm 10258;
BA_ "SPN" SG_ 2556231422 MtrGnrtr2InvrtrLmtsRqstSpdMnmm 10259;
BA_ "SPN" SG_ 2556296958 MtrGnrtr2InvrtrLmtsRqstDSdCr 10270;
BA_ "SPN" SG_ 2556296958 MtrGnrtr2InvrtrLmtsRqstDSdCntr 10271;
BA_ "SPN" SG_ 2556296958 MtGt2IvtLtsRqstDSdVtMx 10272;
BA_ "SPN" SG_ 2556296958 MtGt2IvtLtsRqstDSdVtM 10273;
BA_ "SPN" SG_ 2556296958 MtGt2IvtLtsRqstDSdCtMx 10274;
BA_ "SPN" SG_ 2556296958 MtGt2IvtLtsRqstDSdCtM 10275;
BA_ "SPN" SG_ 2556362494 MtrGnrtr1InvrtrLmtsRqstDSdCr 10204;
BA_ "SPN" SG_ 2556362494 MtrGnrtr1InvrtrLmtsRqstDSdCntr 10205;
BA_ "SPN" SG_ 2556362494 MtGt1IvtLtsRqstDSdVtMx 10206;
BA_ "SPN" SG_ 2556362494 MtGt1IvtLtsRqstDSdVtM 10207;
BA_ "SPN" SG_ 2556362494 MtGt1IvtLtsRqstDSdCtMx 10208;
BA_ "SPN" SG_ 2556362494 MtGt1IvtLtsRqstDSdCtM 10209;
BA_ "SPN" SG_ 2556428030 MtrGnrtr1InvrtrLmtsRqstMhnlCntr 10189;
BA_ "SPN" SG_ 2556428030 MtrGnrtr1InvrtrLmtsRqstMhnlCr 10188;
BA_ "SPN" SG_ 2556428030 MtrGnrtr1InvrtrLmtsRqstTrqMxmm 10190;
BA_ "SPN" SG_ 2556428030 MtrGnrtr1InvrtrLmtsRqstTrqMnmm 10191;
BA_ "SPN" SG_ 2556428030 MtrGnrtr1InvrtrLmtsRqstSpdMxmm 10192;
BA_ "SPN" SG_ 2556428030 MtrGnrtr1InvrtrLmtsRqstSpdMnmm 10193;
BA_ "SPN" SG_ 2556493566 MtrGnrtr1InvrtrLmtsRqstPwrCntr 10177;
BA_ "SPN" SG_ 2556493566 MtrGnrtr1InvrtrLmtsRqstPwrCr 10176;
BA_ "SPN" SG_ 2556493566 MtGt1IvtLtsRqstMPwMx 10178;
BA_ "SPN" SG_ 2556493566 MtGt1IvtLtsRqstMPwM 10179;
BA_ "SPN" SG_ 2556493566 MtGt1IvtLtsRqstDSdPwMx 10180;
BA_ "SPN" SG_ 2556493566 MtGt1IvtLtsRqstDSdPwM 10181;
BA_ "SPN" SG_ 2556559102 PrsnnlDttAlrmRvStts 10142;
BA_ "SPN" SG_ 2556559102 PrsnnlDttSqnCntrEh 10143;
BA_ "SPN" SG_ 2556624638 CnfgrdEngnClndrMssFrtnBrndLtn1 9935;
BA_ "SPN" SG_ 2556624638 CnfgrdEngnClndrMssFrtnBrndLtn2 9936;
BA_ "SPN" SG_ 2556690174 EngnClndrMssFrtnBrndLtn1 9933;
BA_ "SPN" SG_ 2556690174 EngnClndrMssFrtnBrndLtn2 9934;
BA_ "SPN" SG_ 2556755710 CnfgrdEngnClndrPrssrTmng1 9845;
BA_ "SPN" SG_ 2556755710 CnfgrdEngnClndrPrssrTmng2 9846;
BA_ "SPN" SG_ 2556755710 CnfgrdEngnClndrPrssrTmng3 9847;
BA_ "SPN" SG_ 2556755710 CnfgrdEngnClndrPrssrTmng4 9848;
BA_ "SPN" SG_ 2556821246 EngineCylinderPressureTiming1 9849;
BA_ "SPN" SG_ 2556821246 EngineCylinderPressureTiming2 9850;
BA_ "SPN" SG_ 2556821246 EngineCylinderPressureTiming3 9851;
BA_ "SPN" SG_ 2556821246 EngineCylinderPressureTiming4 9852;
BA_ "SPN" SG_ 2556886782 GnrtrClntPmpEnlCmmnd 9829;
BA_ "SPN" SG_ 2556886782 GeneratorCoolantPumpPowerHold 9830;
BA_ "SPN" SG_ 2556886782 GnrtrClntPmpSpdCmmnd 9831;
BA_ "SPN" SG_ 2556886782 GnrtrClntPmpPrntSpdCmmnd 9832;
BA_ "SPN" SG_ 2556886782 EtdAssGtCtPpCdEdddIttSppt 23538;
BA_ "SPN" SG_ 2556886782 EltrfdAssrGnrtrClntPmpCmmndCntr 23539;
BA_ "SPN" SG_ 2556886782 EltrfdAssrGnrtrClntPmpCmmndCr 23540;
BA_ "SPN" SG_ 2556952318 GnrtrClntFnEnlCmmnd 9816;
BA_ "SPN" SG_ 2556952318 GeneratorCoolantFanPowerHold 9817;
BA_ "SPN" SG_ 2556952318 GeneratorCoolantFanSpeedCommand 9818;
BA_ "SPN" SG_ 2556952318 GnrtrClntFnPrntSpdCmmnd 9819;
BA_ "SPN" SG_ 2556952318 EtdAssGtCtFCdEdddIttSppt 23541;
BA_ "SPN" SG_ 2556952318 EltrfdAssrGnrtrClntFnCmmndCntr 23542;
BA_ "SPN" SG_ 2556952318 EltrfdAssrGnrtrClntFnCmmndCr 23543;
BA_ "SPN" SG_ 2557017854 OnBoardProgrammingStatus 9767;
BA_ "SPN" SG_ 2557017854 ObpInterlockOverallStatus 9768;
BA_ "SPN" SG_ 2557017854 ObpInterlockEngineSpeed 9769;
BA_ "SPN" SG_ 2557017854 ObpInterlockKeySwitchPosition 9770;
BA_ "SPN" SG_ 2557017854 ObpInterlockParkBrake 9771;
BA_ "SPN" SG_ 2557017854 ObpInterlockTargetNotReady 9773;
BA_ "SPN" SG_ 2557017854 ObpKeySwitchRequest 9775;
BA_ "SPN" SG_ 2557017854 OnBoardProgrammingProgress 9774;
BA_ "SPN" SG_ 2557017854 OnBrdPrgrmmngTrgtEAddrss 9766;
BA_ "SPN" SG_ 2557017854 OpIntrlkPwrSpplInsffnt 9772;
BA_ "SPN" SG_ 2557017854 OpSftwrUpdtDfrrlsRmnng 22933;
BA_ "SPN" SG_ 2557017854 ObpPowerOffSoftwareUpdateStatus 22934;
BA_ "SPN" SG_ 2557083390 OperatorStationLocationSetting 9661;
BA_ "SPN" SG_ 2557083390 TrollingModeSettingCommand 9662;
BA_ "SPN" SG_ 2557083390 EngnThrttlSnhrnztnMdCmmnd 9663;
BA_ "SPN" SG_ 2557083390 EngineTrollingModeSetSpeed 9664;
BA_ "SPN" SG_ 2557148926 OprtrSttnInCntrlLtn 9654;
BA_ "SPN" SG_ 2557148926 OperatorStationLockout 9655;
BA_ "SPN" SG_ 2557148926 EngnThrttlSnhrnztnMdCrrntSttng 9656;
BA_ "SPN" SG_ 2557148926 TrollingModeExtendedRange 9657;
BA_ "SPN" SG_ 2557148926 TrollingModeCurrentSetting 9658;
BA_ "SPN" SG_ 2557148926 VesselEngineSetSpeed 9659;
BA_ "SPN" SG_ 2557148926 VesselSpeedControlMode 9660;
BA_ "SPN" SG_ 2364617726 EngnPrChmrFlVlv1Drtn 9591;
BA_ "SPN" SG_ 2364617726 EngnPrChmrFlVlv2Drtn 9592;
BA_ "SPN" SG_ 2364617726 EngnPrChmrFlVlv3Drtn 9593;
BA_ "SPN" SG_ 2364617726 EngnPrChmrFlVlv4Drtn 9594;
BA_ "SPN" SG_ 2364617982 EngnPrChmrFlVlv5Drtn 9595;
BA_ "SPN" SG_ 2364617982 EngnPrChmrFlVlv6Drtn 9596;
BA_ "SPN" SG_ 2364617982 EngnPrChmrFlVlv7Drtn 9597;
BA_ "SPN" SG_ 2364617982 EngnPrChmrFlVlv8Drtn 9598;
BA_ "SPN" SG_ 2364618238 EngnPrChmrFlVlv9Drtn 9599;
BA_ "SPN" SG_ 2364618238 EngnPrChmrFlVlv10Drtn 9600;
BA_ "SPN" SG_ 2364618238 EngnPrChmrFlVlv11Drtn 9601;
BA_ "SPN" SG_ 2364618238 EngnPrChmrFlVlv12Drtn 9602;
BA_ "SPN" SG_ 2364618494 EngnPrChmrFlVlv13Drtn 9603;
BA_ "SPN" SG_ 2364618494 EngnPrChmrFlVlv14Drtn 9604;
BA_ "SPN" SG_ 2364618494 EngnPrChmrFlVlv15Drtn 9605;
BA_ "SPN" SG_ 2364618494 EngnPrChmrFlVlv16Drtn 9606;
BA_ "SPN" SG_ 2364618750 EngnPrChmrFlVlv17Drtn 9607;
BA_ "SPN" SG_ 2364618750 EngnPrChmrFlVlv18Drtn 9608;
BA_ "SPN" SG_ 2364618750 EngnPrChmrFlVlv19Drtn 9609;
BA_ "SPN" SG_ 2364618750 EngnPrChmrFlVlv20Drtn 9610;
BA_ "SPN" SG_ 2364619006 EngnPrChmrFlVlv1StrtOfAttnCmmnd 9611;
BA_ "SPN" SG_ 2364619006 EngnPrChmrFlVlv2StrtOfAttnCmmnd 9612;
BA_ "SPN" SG_ 2364619006 EngnPrChmrFlVlv3StrtOfAttnCmmnd 9613;
BA_ "SPN" SG_ 2364619006 EngnPrChmrFlVlv4StrtOfAttnCmmnd 9614;
BA_ "SPN" SG_ 2364619262 EngnPrChmrFlVlv5StrtOfAttnCmmnd 9615;
BA_ "SPN" SG_ 2364619262 EngnPrChmrFlVlv6StrtOfAttnCmmnd 9616;
BA_ "SPN" SG_ 2364619262 EngnPrChmrFlVlv7StrtOfAttnCmmnd 9617;
BA_ "SPN" SG_ 2364619262 EngnPrChmrFlVlv8StrtOfAttnCmmnd 9618;
BA_ "SPN" SG_ 2364619518 EngnPrChmrFlVlv9StrtOfAttnCmmnd 9619;
BA_ "SPN" SG_ 2364619518 EPCFVv10SttOAttCd 9620;
BA_ "SPN" SG_ 2364619518 EPCFVv11SttOAttCd 9621;
BA_ "SPN" SG_ 2364619518 EPCFVv12SttOAttCd 9622;
BA_ "SPN" SG_ 2364619774 EPCFVv13SttOAttCd 9623;
BA_ "SPN" SG_ 2364619774 EPCFVv14SttOAttCd 9624;
BA_ "SPN" SG_ 2364619774 EPCFVv15SttOAttCd 9625;
BA_ "SPN" SG_ 2364619774 EPCFVv16SttOAttCd 9626;
BA_ "SPN" SG_ 2364620030 EPCFVv17SttOAttCd 9627;
BA_ "SPN" SG_ 2364620030 EPCFVv18SttOAttCd 9628;
BA_ "SPN" SG_ 2364620030 EPCFVv19SttOAttCd 9629;
BA_ "SPN" SG_ 2364620030 EPCFVv20SttOAttCd 9630;
BA_ "SPN" SG_ 2364620286 LnKpngAssstSttsRghtSd 9753;
BA_ "SPN" SG_ 2364620286 LaneKeepingAssistStatusLeftSide 9754;
BA_ "SPN" SG_ 2364620286 LnKpngAssstIndtnEnlStts 9755;
BA_ "SPN" SG_ 2364620286 LaneKeepingAssistSystemState 9756;
BA_ "SPN" SG_ 2364620286 ActiveSteeringDriverPreference 9757;
BA_ "SPN" SG_ 2364620286 LnCntrngIndtnEnlStt 9758;
BA_ "SPN" SG_ 2364620286 LaneCenteringSystemStatus 9759;
BA_ "SPN" SG_ 2364620286 HandsOffDetectionStatus 12855;
BA_ "SPN" SG_ 2364620286 HandsOffDetectionAvailability 12854;
BA_ "SPN" SG_ 2364621054 SttnrInvrtrAvrgARmsVltg 9794;
BA_ "SPN" SG_ 2364621054 SttnrInvrtrAvrgLnNtrlARmsVltg 9795;
BA_ "SPN" SG_ 2364621054 SttnrInvrtrAvrgAFrqn 9796;
BA_ "SPN" SG_ 2364621054 SttnrInvrtrAvrgARmsCrrnt 9797;
BA_ "SPN" SG_ 2364621310 SttnrInvrtrTtlRtvPwr 9798;
BA_ "SPN" SG_ 2364621310 SttnrInvrtrOvrllPwrFtr 9799;
BA_ "SPN" SG_ 2364621310 SttnrInvrtrOvrllPwrFtrLggng 9800;
BA_ "SPN" SG_ 2364621566 SttnrInvrtrTtlRlPwr 9801;
BA_ "SPN" SG_ 2364621566 SttnrInvrtrTtlApprntPwr 9802;
BA_ "SPN" SG_ 2364621822 SttnrInvrtrNtRdTAtmtllPrlllStt 9803;
BA_ "SPN" SG_ 2364621822 SttnrInvrtrAxlrShtdwnSwth 9804;
BA_ "SPN" SG_ 2364622078 StationaryInverterToBusDeadBus 9806;
BA_ "SPN" SG_ 2364622078 SttnrInvrtrTBsPhsMth 9807;
BA_ "SPN" SG_ 2364622078 SttnrInvrtrTBsFrqnMth 9808;
BA_ "SPN" SG_ 2364622078 SttnrInvrtrTBsVltgMth 9809;
BA_ "SPN" SG_ 2364622078 StationaryInverterToBusInSync 9810;
BA_ "SPN" SG_ 2364622078 SttnrInvrtrTBsAPhsDffrn 9811;
BA_ "SPN" SG_ 2364622334 EngineCylinder1Timing1Pressure 9853;
BA_ "SPN" SG_ 2364622334 EngineCylinder1Timing2Pressure 9854;
BA_ "SPN" SG_ 2364622334 EngineCylinder1Timing3Pressure 9855;
BA_ "SPN" SG_ 2364622334 EngineCylinder1Timing4Pressure 9856;
BA_ "SPN" SG_ 2364622590 EngineCylinder2Timing1Pressure 9857;
BA_ "SPN" SG_ 2364622590 EngineCylinder2Timing2Pressure 9858;
BA_ "SPN" SG_ 2364622590 EngineCylinder2Timing3Pressure 9859;
BA_ "SPN" SG_ 2364622590 EngineCylinder2Timing4Pressure 9860;
BA_ "SPN" SG_ 2364622846 EngineCylinder3Timing1Pressure 9861;
BA_ "SPN" SG_ 2364622846 EngineCylinder3Timing2Pressure 9862;
BA_ "SPN" SG_ 2364622846 EngineCylinder3Timing3Pressure 9863;
BA_ "SPN" SG_ 2364622846 EngineCylinder3Timing4Pressure 9864;
BA_ "SPN" SG_ 2364623102 EngineCylinder4Timing1Pressure 9865;
BA_ "SPN" SG_ 2364623102 EngineCylinder4Timing2Pressure 9866;
BA_ "SPN" SG_ 2364623102 EngineCylinder4Timing3Pressure 9867;
BA_ "SPN" SG_ 2364623102 EngineCylinder4Timing4Pressure 9868;
BA_ "SPN" SG_ 2364623358 EngineCylinder5Timing1Pressure 9869;
BA_ "SPN" SG_ 2364623358 EngineCylinder5Timing2Pressure 9870;
BA_ "SPN" SG_ 2364623358 EngineCylinder5Timing3Pressure 9871;
BA_ "SPN" SG_ 2364623358 EngineCylinder5Timing4Pressure 9872;
BA_ "SPN" SG_ 2364623614 EngineCylinder6Timing1Pressure 9873;
BA_ "SPN" SG_ 2364623614 EngineCylinder6Timing2Pressure 9874;
BA_ "SPN" SG_ 2364623614 EngineCylinder6Timing3Pressure 9875;
BA_ "SPN" SG_ 2364623614 EngineCylinder6Timing4Pressure 9876;
BA_ "SPN" SG_ 2364623870 EngineCylinder7Timing1Pressure 9877;
BA_ "SPN" SG_ 2364623870 EngineCylinder7Timing2Pressure 9878;
BA_ "SPN" SG_ 2364623870 EngineCylinder7Timing3Pressure 9879;
BA_ "SPN" SG_ 2364623870 EngineCylinder7Timing4Pressure 9880;
BA_ "SPN" SG_ 2364624126 EngineCylinder8Timing1Pressure 9881;
BA_ "SPN" SG_ 2364624126 EngineCylinder8Timing2Pressure 9882;
BA_ "SPN" SG_ 2364624126 EngineCylinder8Timing3Pressure 9883;
BA_ "SPN" SG_ 2364624126 EngineCylinder8Timing4Pressure 9884;
BA_ "SPN" SG_ 2364624382 EngineCylinder9Timing1Pressure 9885;
BA_ "SPN" SG_ 2364624382 EngineCylinder9Timing2Pressure 9886;
BA_ "SPN" SG_ 2364624382 EngineCylinder9Timing3Pressure 9887;
BA_ "SPN" SG_ 2364624382 EngineCylinder9Timing4Pressure 9888;
BA_ "SPN" SG_ 2364624638 EngineCylinder10Timing1Pressure 9889;
BA_ "SPN" SG_ 2364624638 EngineCylinder10Timing2Pressure 9890;
BA_ "SPN" SG_ 2364624638 EngineCylinder10Timing3Pressure 9891;
BA_ "SPN" SG_ 2364624638 EngineCylinder10Timing4Pressure 9892;
BA_ "SPN" SG_ 2364624894 EngineCylinder11Timing1Pressure 9893;
BA_ "SPN" SG_ 2364624894 EngineCylinder11Timing2Pressure 9894;
BA_ "SPN" SG_ 2364624894 EngineCylinder11Timing3Pressure 9895;
BA_ "SPN" SG_ 2364624894 EngineCylinder11Timing4Pressure 9896;
BA_ "SPN" SG_ 2364625150 EngineCylinder12Timing1Pressure 9897;
BA_ "SPN" SG_ 2364625150 EngineCylinder12Timing2Pressure 9898;
BA_ "SPN" SG_ 2364625150 EngineCylinder12Timing3Pressure 9899;
BA_ "SPN" SG_ 2364625150 EngineCylinder12Timing4Pressure 9900;
BA_ "SPN" SG_ 2364625406 EngineCylinder13Timing1Pressure 9901;
BA_ "SPN" SG_ 2364625406 EngineCylinder13Timing2Pressure 9902;
BA_ "SPN" SG_ 2364625406 EngineCylinder13Timing3Pressure 9903;
BA_ "SPN" SG_ 2364625406 EngineCylinder13Timing4Pressure 9904;
BA_ "SPN" SG_ 2364625662 EngineCylinder14Timing1Pressure 9905;
BA_ "SPN" SG_ 2364625662 EngineCylinder14Timing2Pressure 9906;
BA_ "SPN" SG_ 2364625662 EngineCylinder14Timing3Pressure 9907;
BA_ "SPN" SG_ 2364625662 EngineCylinder14Timing4Pressure 9908;
BA_ "SPN" SG_ 2364625918 EngineCylinder15Timing1Pressure 9909;
BA_ "SPN" SG_ 2364625918 EngineCylinder15Timing2Pressure 9910;
BA_ "SPN" SG_ 2364625918 EngineCylinder15Timing3Pressure 9911;
BA_ "SPN" SG_ 2364625918 EngineCylinder15Timing4Pressure 9912;
BA_ "SPN" SG_ 2364626174 EngineCylinder16Timing1Pressure 9913;
BA_ "SPN" SG_ 2364626174 EngineCylinder16Timing2Pressure 9914;
BA_ "SPN" SG_ 2364626174 EngineCylinder16Timing3Pressure 9915;
BA_ "SPN" SG_ 2364626174 EngineCylinder16Timing4Pressure 9916;
